VERSION ""

NS_ :

BS_:

BU_: ADSP CH ChassisBus DIPF DIPR ETH FC GTW GTWU HVI HVS ODIN PARTY PartyBus Receiver SDCV SUI UI UIS VEH VIRT VITALS VehicleBus X

CM_ "Merged Tesla Model Y DBC. Priority order (highest wins on message-ID conflict):
  1. joshwardell/model3dbc (Model3CAN.dbc) (159 messages)
  2. talas9/tesla_can_signals (ModelY_ETH.compact.json) (148 messages)
  3. onyx-m2/onyx-m2-dbc (tesla_model3.dbc) (316 messages)
  4. commaai/opendbc (tesla_model3_party.dbc) (21 messages)
Generated by overlaying sources by message ID; lower-priority sources fill IDs missing from higher-priority ones.";

BO_ 12 ID00CUI_status: 8 VehicleBus
 SG_ UI_audioActive : 1|1@1+ (1,0) [0|1] ""  Receiver
 SG_ UI_autopilotTrial : 12|2@1+ (1,0) [0|3] ""  Receiver
 SG_ UI_bluetoothActive : 2|1@1+ (1,0) [0|1] ""  Receiver
 SG_ UI_cameraActive : 41|1@1+ (1,0) [0|1] ""  Receiver
 SG_ UI_cellActive : 3|1@1+ (1,0) [0|1] ""  Receiver
 SG_ UI_cellConnected : 10|1@1+ (1,0) [0|1] ""  Receiver
 SG_ UI_cellNetworkTechnology : 19|4@1+ (1,0) [0|15] ""  Receiver
 SG_ UI_cellReceiverPower : 24|8@1+ (1,-128) [-128|127] "dB"  Receiver
 SG_ UI_cellSignalBars : 42|3@1+ (1,0) [0|7] ""  Receiver
 SG_ UI_cpuTemperature : 56|8@1- (1,40) [-20|100] "C"  Receiver
 SG_ UI_developmentCar : 40|1@1+ (1,0) [0|1] ""  Receiver
 SG_ UI_displayOn : 5|1@1+ (1,0) [0|1] ""  Receiver
 SG_ UI_displayReady : 4|1@1+ (1,0) [0|1] ""  Receiver
 SG_ UI_factoryReset : 14|2@1+ (1,0) [0|3] ""  Receiver
 SG_ UI_falseTouchCounter : 32|8@1+ (1,0) [0|255] "1"  Receiver
 SG_ UI_gpsActive : 16|1@1+ (1,0) [0|1] ""  Receiver
 SG_ UI_pcbTemperature : 48|8@1- (1,40) [-20|100] "C"  Receiver
 SG_ UI_radioActive : 18|1@1+ (1,0) [0|1] ""  Receiver
 SG_ UI_readyForDrive : 9|1@1+ (1,0) [0|1] ""  Receiver
 SG_ UI_screenshotActive : 17|1@1+ (1,0) [0|1] ""  Receiver
 SG_ UI_systemActive : 8|1@1+ (1,0) [0|1] ""  Receiver
 SG_ UI_touchActive : 0|1@1+ (1,0) [0|1] ""  Receiver
 SG_ UI_vpnActive : 11|1@1+ (1,0) [0|1] ""  Receiver
 SG_ UI_wifiActive : 6|1@1+ (1,0) [0|1] ""  Receiver
 SG_ UI_wifiConnected : 7|1@1+ (1,0) [0|1] ""  Receiver

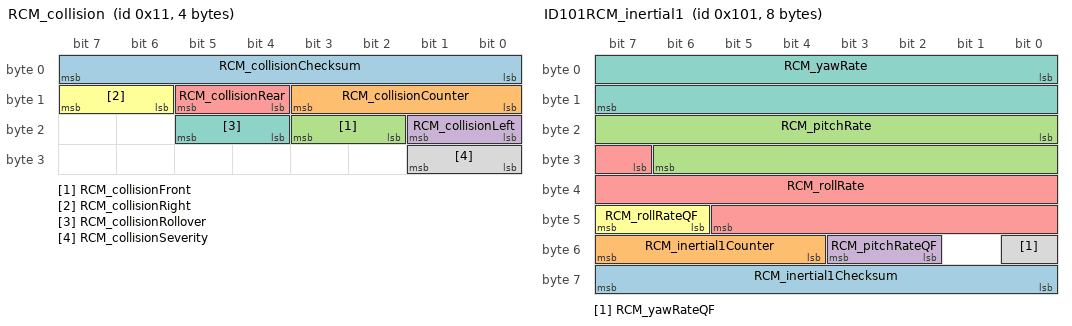
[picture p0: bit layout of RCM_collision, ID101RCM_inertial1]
BO_ 17 RCM_collision: 4 VEH
 SG_ RCM_collisionChecksum: 0|8@1+ (1,0) [0|0] "" X
 SG_ RCM_collisionCounter: 8|4@1+ (1,0) [0|0] "" X
 SG_ RCM_collisionFront: 18|2@1+ (1,0) [0|0] "" X
 SG_ RCM_collisionLeft: 16|2@1+ (1,0) [0|0] "" X
 SG_ RCM_collisionRear: 12|2@1+ (1,0) [0|0] "" X
 SG_ RCM_collisionRight: 14|2@1+ (1,0) [0|0] "" X
 SG_ RCM_collisionRollover: 20|2@1+ (1,0) [0|0] "" X
 SG_ RCM_collisionSeverity: 24|2@1+ (1,0) [0|0] "" X

BO_ 22 ID016DI_bmsRequest: 1 VehicleBus
 SG_ DI_bmsOpenContactorsRequest : 4|1@1+ (1,0) [0|1] ""  Receiver
 SG_ DI_bmsRequestInterfaceVersion : 0|4@1+ (1,0) [0|15] ""  Receiver

BO_ 60 GTW_info: 8 VEH
 SG_ GTW_infoIndex M: 0|8@1+ (1,0) [0|0] "" X
 SG_ GTW_applicationGitHash m17: 10|54@1+ (4,0) [0|0] "" X
 SG_ GTW_buildType m10: 8|3@1+ (1,0) [0|0] "" X
 SG_ GTW_hardwareId m10: 32|16@1+ (1,0) [0|0] "" X
 SG_ GTW_bootGitHash m18: 10|54@1+ (4,0) [0|0] "" X
 SG_ GTW_bootCrc m20: 32|32@1+ (1,0) [0|0] "" X
 SG_ GTW_platformType m13: 8|8@1+ (1,0) [0|0] "" X
 SG_ GTW_appCrc m13: 32|32@1+ (1,0) [0|0] "" X

BO_ 62 GTW_alertMatrix: 8 VEH
 SG_ GTW_matrixIndex M: 0|4@1+ (1,0) [0|0] "" X
 SG_ GTW_w000_GTW_ALERT_DO_NOT_USE m0: 4|1@1+ (1,0) [0|0] "" X
 SG_ GTW_w001_canVEHTxQueue m0: 5|1@1+ (1,0) [0|0] "" X
 SG_ GTW_w002_taskError m0: 6|1@1+ (1,0) [0|0] "" X
 SG_ GTW_w003_logWriteRecord m0: 7|1@1+ (1,0) [0|0] "" X
 SG_ GTW_w004_mallocHook m0: 8|1@1+ (1,0) [0|0] "" X
 SG_ GTW_w005_stackOverflowHook m0: 9|1@1+ (1,0) [0|0] "" X
 SG_ GTW_w006_ifTxOutputFull m0: 10|1@1+ (1,0) [0|0] "" X
 SG_ GTW_w007_ifRxBufError m0: 11|1@1+ (1,0) [0|0] "" X
 SG_ GTW_w008_ifPbufAllocError m0: 12|1@1+ (1,0) [0|0] "" X
 SG_ GTW_w009_lateTask m0: 13|1@1+ (1,0) [0|0] "" X
 SG_ GTW_w010_wdTaskCount m0: 14|1@1+ (1,0) [0|0] "" X
 SG_ GTW_w011_cancoreWatchdog m0: 15|1@1+ (1,0) [0|0] "" X
 SG_ GTW_w012_maincoreWatchdog m0: 16|1@1+ (1,0) [0|0] "" X
 SG_ GTW_w014_APSversionMismatch m0: 17|1@1+ (1,0) [0|0] "" X
 SG_ GTW_w015_DISversionMismatch m0: 18|1@1+ (1,0) [0|0] "" X
 SG_ GTW_w016_BLEEPversionMismatch m0: 19|1@1+ (1,0) [0|0] "" X
 SG_ GTW_w017_BMSversionMismatch m0: 20|1@1+ (1,0) [0|0] "" X
 SG_ GTW_w018_CMPversionMismatch m0: 21|1@1+ (1,0) [0|0] "" X
 SG_ GTW_w019_CPversionMismatch m0: 22|1@1+ (1,0) [0|0] "" X
 SG_ GTW_w020_DIversionMismatch m0: 23|1@1+ (1,0) [0|0] "" X
 SG_ GTW_w021_EPAS3PversionMismatch m0: 24|1@1+ (1,0) [0|0] "" X
 SG_ GTW_w022_EPBLversionMismatch m0: 25|1@1+ (1,0) [0|0] "" X
 SG_ GTW_w023_EPBRversionMismatch m0: 26|1@1+ (1,0) [0|0] "" X
 SG_ GTW_w024_ESPversionMismatch m0: 27|1@1+ (1,0) [0|0] "" X
 SG_ GTW_w025_ESPCALversionMismatch m0: 28|1@1+ (1,0) [0|0] "" X
 SG_ GTW_w026_GTWversionMismatch m0: 29|1@1+ (1,0) [0|0] "" X
 SG_ GTW_w027_HVPversionMismatch m0: 30|1@1+ (1,0) [0|0] "" X
 SG_ GTW_w028_IBSTversionMismatch m0: 31|1@1+ (1,0) [0|0] "" X
 SG_ GTW_w029_IBSTCALversionMismatch m0: 32|1@1+ (1,0) [0|0] "" X
 SG_ GTW_w030_OCS1PversionMismatch m0: 33|1@1+ (1,0) [0|0] "" X
 SG_ GTW_w031_PARKversionMismatch m0: 34|1@1+ (1,0) [0|0] "" X
 SG_ GTW_w032_PCSversionMismatch m0: 35|1@1+ (1,0) [0|0] "" X
 SG_ GTW_w033_PCSCPU2versionMismatch m0: 36|1@1+ (1,0) [0|0] "" X
 SG_ GTW_w034_PMversionMismatch m0: 37|1@1+ (1,0) [0|0] "" X
 SG_ GTW_w035_PMSversionMismatch m0: 38|1@1+ (1,0) [0|0] "" X
 SG_ GTW_w036_PTCversionMismatch m0: 39|1@1+ (1,0) [0|0] "" X
 SG_ GTW_w037_RADCversionMismatch m0: 40|1@1+ (1,0) [0|0] "" X
 SG_ GTW_w038_RCMversionMismatch m0: 41|1@1+ (1,0) [0|0] "" X
 SG_ GTW_w039_RCMCALversionMismatch m0: 42|1@1+ (1,0) [0|0] "" X
 SG_ GTW_w040_SCCMversionMismatch m0: 43|1@1+ (1,0) [0|0] "" X
 SG_ GTW_w041_VCSECversionMismatch m0: 44|1@1+ (1,0) [0|0] "" X
 SG_ GTW_w042_TASversionMismatch m0: 45|1@1+ (1,0) [0|0] "" X
 SG_ GTW_w043_THSversionMismatch m0: 46|1@1+ (1,0) [0|0] "" X
 SG_ GTW_w044_TPMSversionMismatch m0: 47|1@1+ (1,0) [0|0] "" X
 SG_ GTW_w045_VCFRONTversionMismatch m0: 48|1@1+ (1,0) [0|0] "" X
 SG_ GTW_w046_VCLEFTversionMismatch m0: 49|1@1+ (1,0) [0|0] "" X
 SG_ GTW_w047_VCRIGHTversionMismatch m0: 50|1@1+ (1,0) [0|0] "" X
 SG_ GTW_w048_EPAS3SversionMismatch m0: 51|1@1+ (1,0) [0|0] "" X
 SG_ GTW_w049_corruptedManifest m0: 52|1@1+ (1,0) [0|0] "" X
 SG_ GTW_w050_sdCardInitFailure m0: 53|1@1+ (1,0) [0|0] "" X
 SG_ GTW_w051_sdCardFileSystemFailure m0: 54|1@1+ (1,0) [0|0] "" X
 SG_ GTW_w052_ifTxSpans m0: 55|1@1+ (1,0) [0|0] "" X
 SG_ GTW_w053_busSleepFailure m0: 56|1@1+ (1,0) [0|0] "" X
 SG_ GTW_w054_OPCversionMismatch m0: 57|1@1+ (1,0) [0|0] "" X
 SG_ GTW_w055_OPCSversionMismatch m0: 58|1@1+ (1,0) [0|0] "" X
 SG_ GTW_w057_i2cFailure m0: 59|1@1+ (1,0) [0|0] "" X
 SG_ GTW_w058_rtcAlarmFailure m0: 60|1@1+ (1,0) [0|0] "" X
 SG_ GTW_w059_inFactoryMode m0: 61|1@1+ (1,0) [0|0] "" X
 SG_ GTW_w060_unFused m0: 62|1@1+ (1,0) [0|0] "" X
 SG_ GTW_w061_bmpSleepFailure m0: 63|1@1+ (1,0) [0|0] "" X
 SG_ GTW_w062_bmpWatchdog m1: 4|1@1+ (1,0) [0|0] "" X
 SG_ GTW_w063_VEH_canFault m1: 5|1@1+ (1,0) [0|0] "" X
 SG_ GTW_w064_CH_canFault m1: 6|1@1+ (1,0) [0|0] "" X
 SG_ GTW_w065_PARTY_canFault m1: 7|1@1+ (1,0) [0|0] "" X
 SG_ GTW_w066_exception m1: 8|1@1+ (1,0) [0|0] "" X
 SG_ GTW_w067_tcpDebug m1: 9|1@1+ (1,0) [0|0] "" X
 SG_ GTW_w068_prodKeyMissing m1: 10|1@1+ (1,0) [0|0] "" X
 SG_ GTW_w069_diskioErr m1: 11|1@1+ (1,0) [0|0] "" X
 SG_ GTW_w070_hrlDump m1: 12|1@1+ (1,0) [0|0] "" X
 SG_ GTW_w071_hrlTrigger m1: 13|1@1+ (1,0) [0|0] "" X
 SG_ GTW_w072_updateFailure m1: 14|1@1+ (1,0) [0|0] "" X
 SG_ GTW_w073_steeringWheelReset m1: 15|1@1+ (1,0) [0|0] "" X
 SG_ GTW_w074_epas3pMIA m1: 16|1@1+ (1,0) [0|0] "" X
 SG_ GTW_w075_epas3sMIA m1: 17|1@1+ (1,0) [0|0] "" X
 SG_ GTW_w076_VEHInterfaceReset m1: 18|1@1+ (1,0) [0|0] "" X
 SG_ GTW_w077_bmpPmicError m1: 19|1@1+ (1,0) [0|0] "" X
 SG_ GTW_w078_VEHbusOverloaded m1: 20|1@1+ (1,0) [0|0] "" X
 SG_ GTW_w079_PARTYbusOverloaded m1: 21|1@1+ (1,0) [0|0] "" X
 SG_ GTW_w080_CHbusOverloaded m1: 22|1@1+ (1,0) [0|0] "" X
 SG_ GTW_w081_udsMessageRejected m1: 23|1@1+ (1,0) [0|0] "" X
 SG_ GTW_w082_sdCardBSCorrupted m1: 24|1@1+ (1,0) [0|0] "" X
 SG_ GTW_w083_udsMsgDroppedByTcpStack m1: 25|1@1+ (1,0) [0|0] "" X
 SG_ GTW_w084_canFrameDropped m1: 26|1@1+ (1,0) [0|0] "" X
 SG_ GTW_w085_iBoosterStuck m1: 27|1@1+ (1,0) [0|0] "" X
 SG_ GTW_w086_ocu m1: 28|1@1+ (1,0) [0|0] "" X
 SG_ GTW_w087_ocuInProgress m1: 29|1@1+ (1,0) [0|0] "" X
 SG_ GTW_w088_sdCardInvReqParallel m1: 30|1@1+ (1,0) [0|0] "" X
 SG_ GTW_w089_sdCardWatchdog m1: 31|1@1+ (1,0) [0|0] "" X
 SG_ GTW_w090_ocuFailed m1: 32|1@1+ (1,0) [0|0] "" X
 SG_ GTW_w091_lowStack m1: 33|1@1+ (1,0) [0|0] "" X
 SG_ GTW_w092_sdCardInvReqZero m1: 34|1@1+ (1,0) [0|0] "" X
 SG_ GTW_w093_sdCardInvReqOverflowBase m1: 35|1@1+ (1,0) [0|0] "" X
 SG_ GTW_w094_sdCardInvReqOverflowCount m1: 36|1@1+ (1,0) [0|0] "" X
 SG_ GTW_w095_sdCardFull m1: 37|1@1+ (1,0) [0|0] "" X
 SG_ GTW_w096_sdCardFatCorrupted m1: 38|1@1+ (1,0) [0|0] "" X
 SG_ GTW_w097_HCMLversionMismatch m1: 39|1@1+ (1,0) [0|0] "" X
 SG_ GTW_w098_HCMRversionMismatch m1: 40|1@1+ (1,0) [0|0] "" X
 SG_ GTW_w099_SWCversionMismatch m1: 41|1@1+ (1,0) [0|0] "" X
 SG_ GTW_w100_CBCversionMismatch m1: 42|1@1+ (1,0) [0|0] "" X
 SG_ GTW_w101_switchWatchdog m1: 43|1@1+ (1,0) [0|0] "" X
 SG_ GTW_w103_sdCardFormatted m1: 44|1@1+ (1,0) [0|0] "" X
 SG_ GTW_w104_sdCardDriverArgCorrupted m1: 45|1@1+ (1,0) [0|0] "" X
 SG_ GTW_w105_eBuckConfigured m1: 46|1@1+ (1,0) [0|0] "" X
 SG_ GTW_w106_failedToStartUpdater m1: 47|1@1+ (1,0) [0|0] "" X

BO_ 79 ID04FGPSLatLong: 8 ChassisBus
 SG_ GPSAccuracy04F : 57|7@1+ (0.2,0) [0|25.2] "m"  Receiver
 SG_ GPSLongitude04F : 28|28@1- (1E-006,0) [-134.218|134.218] "Deg"  Receiver
 SG_ GPSLatitude04F : 0|28@1- (1E-006,0) [-134.218|134.218] "Deg"  Receiver

BO_ 130 ID082UI_tripPlanning: 8 VehicleBus
 SG_ UI_energyAtDestination : 48|16@1- (0.01,0) [-327.67|327.67] "kWh"  Receiver
 SG_ UI_hindsightEnergy : 32|16@1- (0.01,0) [-327.67|327.67] "kWh"  Receiver
 SG_ UI_navToSupercharger : 1|1@1+ (1,0) [0|1] ""  Receiver
 SG_ UI_predictedEnergy : 16|16@1- (0.01,0) [-327.67|327.67] "kWh"  Receiver
 SG_ UI_requestActiveBatteryHeating : 2|1@1+ (1,0) [0|1] ""  Receiver
 SG_ UI_tripPlanningActive : 0|1@1+ (1,0) [0|1] ""  Receiver

BO_ 139 UI_tripPlanning2: 6 VEH
 SG_ UI_maxSpeedToReachDestination : 0|16@1+ (0.01,0) [0|655.34] "m/s" X
 SG_ UI_remainingWeightedRMSSpeed : 16|16@1+ (0.01,0) [0|655.34] "m/s" X
 SG_ UI_timeToDestination : 32|16@1+ (1,0) [0|65534] "s" X

BO_ 257 ID101RCM_inertial1: 8 ChassisBus
 SG_ RCM_inertial1Checksum : 56|8@1+ (1,0) [0|255] ""  Receiver
 SG_ RCM_inertial1Counter : 52|4@1+ (1,0) [0|15] ""  Receiver
 SG_ RCM_pitchRate : 16|15@1- (0.00025,0) [-4.096|4.09575] "rad/s"  Receiver
 SG_ RCM_pitchRateQF : 50|2@1+ (1,0) [0|3] ""  Receiver
 SG_ RCM_rollRate : 31|15@1- (0.00025,0) [-4.096|4.09575] "rad/s"  Receiver
 SG_ RCM_rollRateQF : 46|2@1+ (1,0) [0|3] ""  Receiver
 SG_ RCM_yawRate : 0|16@1- (0.0001,0) [-3.2766|3.2766] "rad/s"  Receiver
 SG_ RCM_yawRateQF : 48|1@1+ (1,0) [0|1] ""  Receiver

BO_ 258 ID102VCLEFT_doorStatus: 8 VehicleBus
 SG_ VCLEFT_frontHandlePWM : 16|7@1+ (1,0) [0|100] "%"  Receiver
 SG_ VCLEFT_frontHandlePulled : 10|1@1+ (1,0) [0|1] ""  Receiver
 SG_ VCLEFT_frontHandlePulledPersist : 62|1@1+ (1,0) [0|1] ""  Receiver
 SG_ VCLEFT_frontIntSwitchPressed : 31|1@1+ (1,0) [0|1] ""  Receiver
 SG_ VCLEFT_frontLatchStatus : 0|4@1+ (1,0) [0|8] ""  Receiver
 SG_ VCLEFT_frontLatchSwitch : 8|1@1+ (1,0) [0|1] ""  Receiver
 SG_ VCLEFT_frontRelActuatorSwitch : 12|1@1+ (1,0) [0|1] ""  Receiver
 SG_ VCLEFT_mirrorDipped : 61|1@1+ (1,0) [0|1] ""  Receiver
 SG_ VCLEFT_mirrorFoldState : 52|3@1+ (1,0) [0|4] ""  Receiver
 SG_ VCLEFT_mirrorHeatState : 58|3@1+ (1,0) [0|4] ""  Receiver
 SG_ VCLEFT_mirrorRecallState : 55|3@1+ (1,0) [0|5] ""  Receiver
 SG_ VCLEFT_mirrorState : 49|3@1+ (1,0) [0|4] ""  Receiver
 SG_ VCLEFT_mirrorTiltXPosition : 33|8@1+ (0.02,0) [0|5] "V"  Receiver
 SG_ VCLEFT_mirrorTiltYPosition : 41|8@1+ (0.02,0) [0|5] "V"  Receiver
 SG_ VCLEFT_rearHandlePWM : 24|7@1+ (1,0) [0|100] "%"  Receiver
 SG_ VCLEFT_rearHandlePulled : 11|1@1+ (1,0) [0|1] ""  Receiver
 SG_ VCLEFT_rearIntSwitchPressed : 32|1@1+ (1,0) [0|1] ""  Receiver
 SG_ VCLEFT_rearLatchStatus : 4|4@1+ (1,0) [0|8] ""  Receiver
 SG_ VCLEFT_rearLatchSwitch : 9|1@1+ (1,0) [0|1] ""  Receiver
 SG_ VCLEFT_rearRelActuatorSwitch : 13|1@1+ (1,0) [0|1] ""  Receiver

BO_ 259 ID103VCRIGHT_doorStatus: 8 VehicleBus
 SG_ VCRIGHT_frontHandlePWM : 14|7@1+ (1,0) [0|100] "%"  Receiver
 SG_ VCRIGHT_frontHandlePulled : 10|1@1+ (1,0) [0|1] ""  Receiver
 SG_ VCRIGHT_frontHandlePulledPersist : 30|1@1+ (1,0) [0|1] ""  Receiver
 SG_ VCRIGHT_frontIntSwitchPressed : 31|1@1+ (1,0) [0|1] ""  Receiver
 SG_ VCRIGHT_frontLatchStatus : 0|4@1+ (1,0) [0|8] ""  Receiver
 SG_ VCRIGHT_frontLatchSwitch : 8|1@1+ (1,0) [0|1] ""  Receiver
 SG_ VCRIGHT_frontRelActuatorSwitch : 12|1@1+ (1,0) [0|1] ""  Receiver
 SG_ VCRIGHT_mirrorDipped : 63|1@1+ (1,0) [0|1] ""  Receiver
 SG_ VCRIGHT_mirrorFoldState : 52|3@1+ (1,0) [0|4] ""  Receiver
 SG_ VCRIGHT_mirrorRecallState : 60|3@1+ (1,0) [0|5] ""  Receiver
 SG_ VCRIGHT_mirrorState : 49|3@1+ (1,0) [0|4] ""  Receiver
 SG_ VCRIGHT_mirrorTiltXPosition : 33|8@1+ (0.02,0) [0|5] "V"  Receiver
 SG_ VCRIGHT_mirrorTiltYPosition : 41|8@1+ (0.02,0) [0|5] "V"  Receiver
 SG_ VCRIGHT_rearHandlePWM : 21|7@1+ (1,0) [0|100] "%"  Receiver
 SG_ VCRIGHT_rearHandlePulled : 11|1@1+ (1,0) [0|1] ""  Receiver
 SG_ VCRIGHT_rearIntSwitchPressed : 32|1@1+ (1,0) [0|1] ""  Receiver
 SG_ VCRIGHT_rearLatchStatus : 4|4@1+ (1,0) [0|8] ""  Receiver
 SG_ VCRIGHT_rearLatchSwitch : 9|1@1+ (1,0) [0|1] ""  Receiver
 SG_ VCRIGHT_rearRelActuatorSwitch : 13|1@1+ (1,0) [0|1] ""  Receiver
 SG_ VCRIGHT_reservedForBackCompat : 28|2@1+ (1,0) [0|3] ""  Receiver
 SG_ VCRIGHT_trunkLatchStatus : 56|4@1+ (1,0) [0|8] ""  Receiver

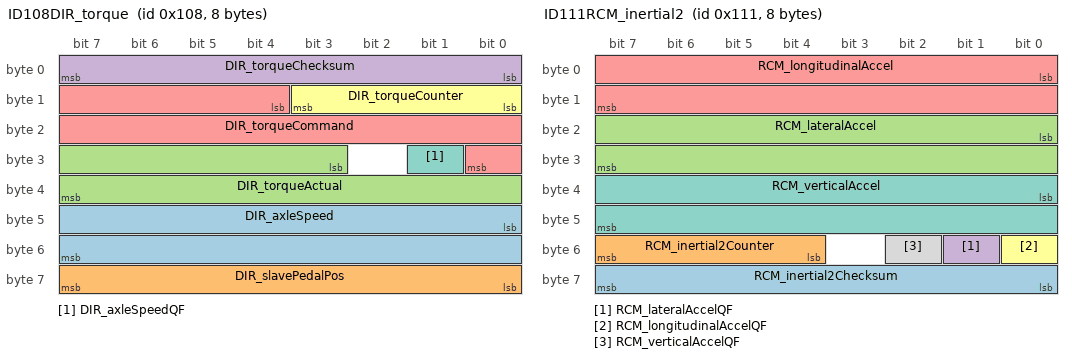
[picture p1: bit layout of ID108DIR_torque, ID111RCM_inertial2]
BO_ 264 ID108DIR_torque: 8 VehicleBus
 SG_ DIR_axleSpeed : 40|16@1- (0.1,0) [-2750|2750] "RPM"  Receiver
 SG_ DIR_slavePedalPos : 56|8@1+ (0.4,0) [0|100] "%"  Receiver
 SG_ DIR_torqueActual : 27|13@1- (2,0) [-7500|7500] "Nm"  Receiver
 SG_ DIR_torqueChecksum : 0|8@1+ (1,0) [0|255] ""  Receiver
 SG_ DIR_torqueCommand : 12|13@1- (2,0) [-7500|7500] "Nm"  Receiver
 SG_ DIR_torqueCounter : 8|4@1+ (1,0) [0|15] ""  Receiver
 SG_ DIR_axleSpeedQF : 25|1@1+ (1,0) [0|1] ""  Receiver

BO_ 273 ID111RCM_inertial2: 8 ChassisBus
 SG_ RCM_inertial2Checksum : 56|8@1+ (1,0) [0|255] ""  Receiver
 SG_ RCM_inertial2Counter : 52|4@1+ (1,0) [0|15] ""  Receiver
 SG_ RCM_lateralAccel : 16|16@1- (0.00125,0) [-40.9575|40.9575] "m/s^2"  Receiver
 SG_ RCM_lateralAccelQF : 49|1@1+ (1,0) [0|1] ""  Receiver
 SG_ RCM_longitudinalAccel : 0|16@1- (0.00125,0) [-40.9575|40.9575] "m/s^2"  Receiver
 SG_ RCM_longitudinalAccelQF : 48|1@1+ (1,0) [0|1] ""  Receiver
 SG_ RCM_verticalAccel : 32|16@1- (0.00125,0) [-40.9575|40.9575] "m/s^2"  Receiver
 SG_ RCM_verticalAccelQF : 50|1@1+ (1,0) [0|1] ""  Receiver

BO_ 274 GTW_adc1: 8 VEH
 SG_ GTW_1V1_VEH: 24|12@0+ (1,0) [0|0] "mV" X
 SG_ GTW_1V5_VEH: 32|12@0+ (1,0) [0|0] "mV" X
 SG_ GTW_3V3_VEH: 0|12@0+ (1.03,0) [0|0] "mV" X
 SG_ GTW_3V3_SW: 8|12@0+ (1.5,0) [0|0] "mV" X
 SG_ GTW_5V0_SW: 48|12@0+ (2,0) [0|0] "mV" X

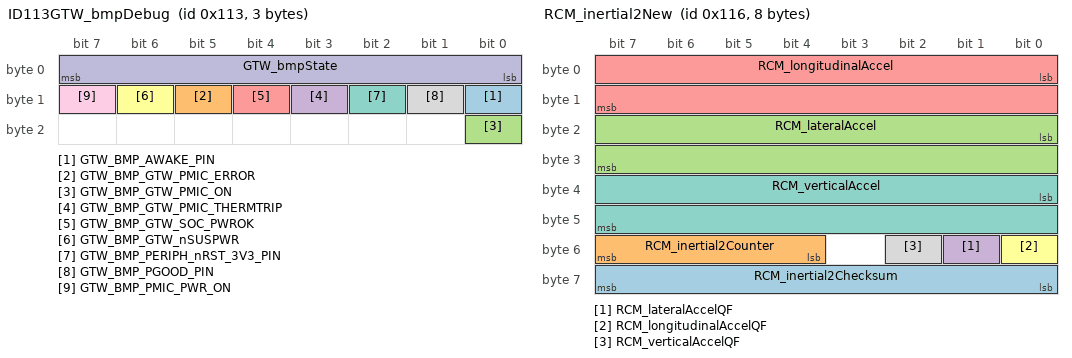
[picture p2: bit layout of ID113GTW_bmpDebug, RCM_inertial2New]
BO_ 275 ID113GTW_bmpDebug: 3 VehicleBus
 SG_ GTW_BMP_AWAKE_PIN : 8|1@1+ (1,0) [0|1] ""  Receiver
 SG_ GTW_BMP_GTW_PMIC_ERROR : 13|1@1+ (1,0) [0|1] ""  Receiver
 SG_ GTW_BMP_GTW_PMIC_ON : 16|1@1+ (1,0) [0|1] ""  Receiver
 SG_ GTW_BMP_GTW_PMIC_THERMTRIP : 11|1@1+ (1,0) [0|1] ""  Receiver
 SG_ GTW_BMP_GTW_SOC_PWROK : 12|1@1+ (1,0) [0|1] ""  Receiver
 SG_ GTW_BMP_GTW_nSUSPWR : 14|1@1+ (1,0) [0|1] ""  Receiver
 SG_ GTW_BMP_PERIPH_nRST_3V3_PIN : 10|1@1+ (1,0) [0|1] ""  Receiver
 SG_ GTW_BMP_PGOOD_PIN : 9|1@1+ (1,0) [0|1] ""  Receiver
 SG_ GTW_BMP_PMIC_PWR_ON : 15|1@1+ (1,0) [0|1] ""  Receiver
 SG_ GTW_bmpState : 7|8@0+ (1,0) [0|255] ""  Receiver

BO_ 276 GTW_adc3: 8 VEH
 SG_ GTW_1V2_CSI: 24|12@0+ (1,0) [0|0] "mV" X
 SG_ GTW_1V8_VID: 8|12@0+ (1,0) [0|0] "mV" X
 SG_ GTW_1V8_VIO: 0|12@0+ (2,0) [0|0] "mV" X
 SG_ GTW_3V3_BMP: 32|12@0+ (2,0) [0|0] "mV" X
 SG_ GTW_GSM_BRD_REV: 48|12@0+ (1,0) [0|0] "mV" X

BO_ 278 RCM_inertial2New: 8 ChassisBus
 SG_ RCM_inertial2Checksum : 56|8@1+ (1,0) [0|255] ""  Receiver
 SG_ RCM_inertial2Counter : 52|4@1+ (1,0) [0|15] ""  Receiver
 SG_ RCM_lateralAccel : 16|16@1- (0.00125,0) [-40.9575|40.9575] "m/s^2"  Receiver
 SG_ RCM_lateralAccelQF : 49|1@1+ (1,0) [0|1] ""  Receiver
 SG_ RCM_longitudinalAccel : 0|16@1- (0.00125,0) [-40.9575|40.9575] "m/s^2"  Receiver
 SG_ RCM_longitudinalAccelQF : 48|1@1+ (1,0) [0|1] ""  Receiver
 SG_ RCM_verticalAccel : 32|16@1- (0.00125,0) [-40.9575|40.9575] "m/s^2"  Receiver
 SG_ RCM_verticalAccelQF : 50|1@1+ (1,0) [0|1] ""  Receiver

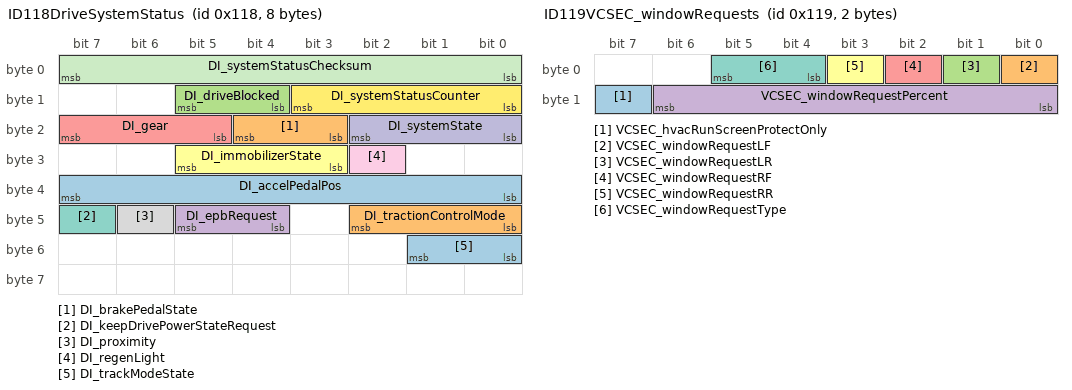
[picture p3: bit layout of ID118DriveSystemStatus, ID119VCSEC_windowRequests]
BO_ 280 ID118DriveSystemStatus: 8 VehicleBus
 SG_ DI_accelPedalPos : 32|8@1+ (0.4,0) [0|100] "%"  Receiver
 SG_ DI_brakePedalState : 19|2@1+ (1,0) [0|2] ""  Receiver
 SG_ DI_driveBlocked : 12|2@1+ (1,0) [0|2] ""  Receiver
 SG_ DI_epbRequest : 44|2@1+ (1,0) [0|2] ""  Receiver
 SG_ DI_gear : 21|3@1+ (1,0) [0|7] ""  Receiver
 SG_ DI_immobilizerState : 27|3@1+ (1,0) [0|6] ""  Receiver
 SG_ DI_keepDrivePowerStateRequest : 47|1@1+ (1,0) [0|1] ""  Receiver
 SG_ DI_proximity : 46|1@1+ (1,0) [0|1] ""  Receiver
 SG_ DI_regenLight : 26|1@1+ (1,0) [0|1] ""  Receiver
 SG_ DI_systemState : 16|3@1+ (1,0) [0|5] ""  Receiver
 SG_ DI_systemStatusChecksum : 0|8@1+ (1,0) [0|255] ""  Receiver
 SG_ DI_systemStatusCounter : 8|4@1+ (1,0) [0|15] ""  Receiver
 SG_ DI_trackModeState : 48|2@1+ (1,0) [0|2] ""  Receiver
 SG_ DI_tractionControlMode : 40|3@1+ (1,0) [0|6] ""  Receiver

BO_ 281 ID119VCSEC_windowRequests: 2 VehicleBus
 SG_ VCSEC_hvacRunScreenProtectOnly : 15|1@1+ (1,0) [0|1] ""  Receiver
 SG_ VCSEC_windowRequestLF : 0|1@1+ (1,0) [0|1] ""  Receiver
 SG_ VCSEC_windowRequestLR : 1|1@1+ (1,0) [0|1] ""  Receiver
 SG_ VCSEC_windowRequestPercent : 8|7@1+ (1,0) [0|127] ""  Receiver
 SG_ VCSEC_windowRequestRF : 2|1@1+ (1,0) [0|1] ""  Receiver
 SG_ VCSEC_windowRequestRR : 3|1@1+ (1,0) [0|1] ""  Receiver
 SG_ VCSEC_windowRequestType : 4|2@1+ (1,0) [0|3] ""  Receiver

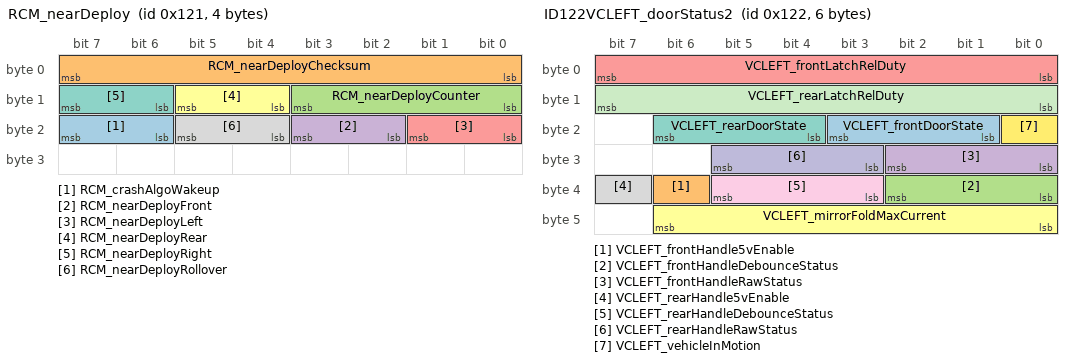
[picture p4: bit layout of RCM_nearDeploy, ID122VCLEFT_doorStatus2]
BO_ 289 RCM_nearDeploy: 4 VEH
 SG_ RCM_crashAlgoWakeup: 22|2@1+ (1,0) [0|0] "" X
 SG_ RCM_nearDeployChecksum: 0|8@1+ (1,0) [0|0] "" X
 SG_ RCM_nearDeployCounter: 8|4@1+ (1,0) [0|0] "" X
 SG_ RCM_nearDeployFront: 18|2@1+ (1,0) [0|0] "" X
 SG_ RCM_nearDeployLeft: 16|2@1+ (1,0) [0|0] "" X
 SG_ RCM_nearDeployRear: 12|2@1+ (1,0) [0|0] "" X
 SG_ RCM_nearDeployRight: 14|2@1+ (1,0) [0|0] "" X
 SG_ RCM_nearDeployRollover: 20|2@1+ (1,0) [0|0] "" X

BO_ 290 ID122VCLEFT_doorStatus2: 6 VehicleBus
 SG_ VCLEFT_frontDoorState : 17|3@1+ (1,0) [0|4] ""  Receiver
 SG_ VCLEFT_frontHandle5vEnable : 38|1@1+ (1,0) [0|1] ""  Receiver
 SG_ VCLEFT_frontHandleDebounceStatus : 32|3@1+ (1,0) [0|5] ""  Receiver
 SG_ VCLEFT_frontHandleRawStatus : 24|3@1+ (1,0) [0|5] ""  Receiver
 SG_ VCLEFT_frontLatchRelDuty : 0|8@1+ (1,0) [0|255] "%"  Receiver
 SG_ VCLEFT_mirrorFoldMaxCurrent : 40|7@1- (0.046,0) [-2.944|2.898] "A"  Receiver
 SG_ VCLEFT_rearDoorState : 20|3@1+ (1,0) [0|4] ""  Receiver
 SG_ VCLEFT_rearHandle5vEnable : 39|1@1+ (1,0) [0|1] ""  Receiver
 SG_ VCLEFT_rearHandleDebounceStatus : 35|3@1+ (1,0) [0|5] ""  Receiver
 SG_ VCLEFT_rearHandleRawStatus : 27|3@1+ (1,0) [0|5] ""  Receiver
 SG_ VCLEFT_rearLatchRelDuty : 8|8@1+ (1,0) [0|255] "%"  Receiver
 SG_ VCLEFT_vehicleInMotion : 16|1@1+ (1,0) [0|1] ""  Receiver

BO_ 291 ID123UI_alertMatrix1: 8 VehicleBus
 SG_ UI_a001_DriverDoorOpen : 0|1@1+ (1,0) [0|1] ""  Receiver
 SG_ UI_a002_DoorOpen : 1|1@1+ (1,0) [0|1] ""  Receiver
 SG_ UI_a003_TrunkOpen : 2|1@1+ (1,0) [0|1] ""  Receiver
 SG_ UI_a004_FrunkOpen : 3|1@1+ (1,0) [0|1] ""  Receiver
 SG_ UI_a005_HeadlightsOnDoorOpen : 4|1@1+ (1,0) [0|1] ""  Receiver
 SG_ UI_a006_RemoteServiceAlert : 5|1@1+ (1,0) [0|1] ""  Receiver
 SG_ UI_a007_SoftPackConfigMismatch : 6|1@1+ (1,0) [0|1] ""  Receiver
 SG_ UI_a008_TouchScreenError : 7|1@1+ (1,0) [0|1] ""  Receiver
 SG_ UI_a009_SquashfsError : 8|1@1+ (1,0) [0|1] ""  Receiver
 SG_ UI_a010_MapsMissing : 9|1@1+ (1,0) [0|1] ""  Receiver
 SG_ UI_a011_IncorrectMap : 10|1@1+ (1,0) [0|1] ""  Receiver
 SG_ UI_a012_NotOnPrivateProperty : 11|1@1+ (1,0) [0|1] ""  Receiver
 SG_ UI_a013_TPMSHardWarning : 12|1@1+ (1,0) [0|1] ""  Receiver
 SG_ UI_a014_TPMSSoftWarning : 13|1@1+ (1,0) [0|1] ""  Receiver
 SG_ UI_a015_TPMSOverPressureWarning : 14|1@1+ (1,0) [0|1] ""  Receiver
 SG_ UI_a016_TPMSTemperatureWarning : 15|1@1+ (1,0) [0|1] ""  Receiver
 SG_ UI_a017_TPMSSystemFault : 16|1@1+ (1,0) [0|1] ""  Receiver
 SG_ UI_a018_SlipStartOn : 17|1@1+ (1,0) [0|1] ""  Receiver
 SG_ UI_a019_ParkBrakeFault : 18|1@1+ (1,0) [0|1] ""  Receiver
 SG_ UI_a020_SteeringReduced : 19|1@1+ (1,0) [0|1] ""  Receiver
 SG_ UI_a021_RearSeatbeltUnbuckled : 20|1@1+ (1,0) [0|1] ""  Receiver
 SG_ UI_a022_ApeFusesEtc : 21|1@1+ (1,0) [0|1] ""  Receiver
 SG_ UI_a023_CellInternetCheckFailed : 22|1@1+ (1,0) [0|1] ""  Receiver
 SG_ UI_a024_WifiInternetCheckFailed : 23|1@1+ (1,0) [0|1] ""  Receiver
 SG_ UI_a025_WifiOnlineCheckFailed : 24|1@1+ (1,0) [0|1] ""  Receiver
 SG_ UI_a026_ModemResetLoopDetected : 25|1@1+ (1,0) [0|1] ""  Receiver
 SG_ UI_a027_AutoSteerMIA : 26|1@1+ (1,0) [0|1] ""  Receiver
 SG_ UI_a028_FrontTrunkPopupClosed : 27|1@1+ (1,0) [0|1] ""  Receiver
 SG_ UI_a029_ModemMIA : 28|1@1+ (1,0) [0|1] ""  Receiver
 SG_ UI_a030_ModemVMCrash : 29|1@1+ (1,0) [0|1] ""  Receiver
 SG_ UI_a031_BrakeFluidLow : 30|1@1+ (1,0) [0|1] ""  Receiver
 SG_ UI_a032_CellModemRecoveryResets : 31|1@1+ (1,0) [0|1] ""  Receiver
 SG_ UI_a033_ApTrialExpired : 32|1@1+ (1,0) [0|1] ""  Receiver
 SG_ UI_a034_WakeupProblem : 33|1@1+ (1,0) [0|1] ""  Receiver
 SG_ UI_a035_AudioWatchdogKernelError : 34|1@1+ (1,0) [0|1] ""  Receiver
 SG_ UI_a036_AudioWatchdogHfpError : 35|1@1+ (1,0) [0|1] ""  Receiver
 SG_ UI_a037_AudioWatchdogXrunStormEr : 36|1@1+ (1,0) [0|1] ""  Receiver
 SG_ UI_a038_AudioWatchdogA2bI2cLocku : 37|1@1+ (1,0) [0|1] ""  Receiver
 SG_ UI_a039_AudioA2bNeedRediscovery : 38|1@1+ (1,0) [0|1] ""  Receiver
 SG_ UI_a040_HomelinkTransmit : 39|1@1+ (1,0) [0|1] ""  Receiver
 SG_ UI_a041_AudioDmesgXrun : 40|1@1+ (1,0) [0|1] ""  Receiver
 SG_ UI_a042_AudioDmesgRtThrottling : 41|1@1+ (1,0) [0|1] ""  Receiver
 SG_ UI_a043_InvalidMapDataOverride : 42|1@1+ (1,0) [0|1] ""  Receiver
 SG_ UI_a044_AudioDmesgDspException : 43|1@1+ (1,0) [0|1] ""  Receiver
 SG_ UI_a045_ECallNeedsService : 44|1@1+ (1,0) [0|1] ""  Receiver
 SG_ UI_a046_BackupCameraStreamError : 45|1@1+ (1,0) [0|1] ""  Receiver
 SG_ UI_a047_CellRoamingDisallowed : 46|1@1+ (1,0) [0|1] ""  Receiver
 SG_ UI_a048_AudioPremiumAmpCheckFail : 47|1@1+ (1,0) [0|1] ""  Receiver
 SG_ UI_a049_BrakeShiftRequired : 48|1@1+ (1,0) [0|1] ""  Receiver
 SG_ UI_a050_BackupCameraIPUTimeout : 49|1@1+ (1,0) [0|1] ""  Receiver
 SG_ UI_a051_BackupCameraFrameTimeout : 50|1@1+ (1,0) [0|1] ""  Receiver
 SG_ UI_a052_KernelPanicReported : 51|1@1+ (1,0) [0|1] ""  Receiver
 SG_ UI_a053_QtCarExitError : 52|1@1+ (1,0) [0|1] ""  Receiver
 SG_ UI_a054_AudioBoostPowerBad : 53|1@1+ (1,0) [0|1] ""  Receiver
 SG_ UI_a055_ManualECallDisabled : 54|1@1+ (1,0) [0|1] ""  Receiver
 SG_ UI_a056_ManualECallButtonDisconn : 55|1@1+ (1,0) [0|1] ""  Receiver
 SG_ UI_a057_CellAntennaDisconnected : 56|1@1+ (1,0) [0|1] ""  Receiver
 SG_ UI_a058_GPSAntennaDisconnected : 57|1@1+ (1,0) [0|1] ""  Receiver
 SG_ UI_a059_ECallSpeakerDisconnected : 58|1@1+ (1,0) [0|1] ""  Receiver
 SG_ UI_a060_ECallMicDisconnected : 59|1@1+ (1,0) [0|1] ""  Receiver
 SG_ UI_a061_SIMTestFailed : 60|1@1+ (1,0) [0|1] ""  Receiver
 SG_ UI_a062_ENSTestFailed : 61|1@1+ (1,0) [0|1] ""  Receiver
 SG_ UI_a063_CellularTestFailed : 62|1@1+ (1,0) [0|1] ""  Receiver
 SG_ UI_a064_ModemFirmwareTestFailed : 63|1@1+ (1,0) [0|1] ""  Receiver

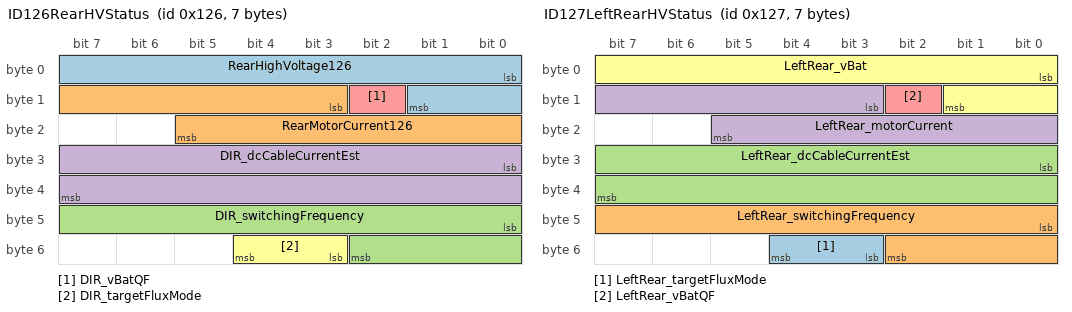
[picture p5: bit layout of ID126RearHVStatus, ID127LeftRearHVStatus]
BO_ 294 ID126RearHVStatus: 7 VehicleBus
 SG_ RearHighVoltage126 : 0|10@1+ (0.5,0) [0|500] "V"  Receiver
 SG_ RearMotorCurrent126 : 11|11@1+ (1,0) [0|2047] "A"  Receiver
 SG_ DIR_switchingFrequency : 40|11@1+ (0.01,0) [0|20] "kHz"  Receiver
 SG_ DIR_dcCableCurrentEst : 24|16@1- (0.1,0) [-3276.8|3276.7] "A"  Receiver
 SG_ DIR_vBatQF : 10|1@1+ (1,0) [0|1] ""  Receiver
 SG_ DIR_targetFluxMode : 51|2@1+ (1,0) [0|0] ""  Receiver

BO_ 295 ID127LeftRearHVStatus: 7 VehicleBus
 SG_ LeftRear_targetFluxMode : 51|2@1+ (1,0) [0|0] ""  Receiver
 SG_ LeftRear_switchingFrequency : 40|11@1+ (0.01,0) [0|0] "kHz"  Receiver
 SG_ LeftRear_dcCableCurrentEst : 24|16@1- (0.1,0) [0|0] "A"  Receiver
 SG_ LeftRear_motorCurrent : 11|11@1+ (1,0) [0|0] "A"  Receiver
 SG_ LeftRear_vBatQF : 10|1@1+ (1,0) [0|0] ""  Receiver
 SG_ LeftRear_vBat : 0|10@1+ (0.5,0) [0|0] "V"  Receiver

BO_ 297 ID129SteeringAngle: 8 VehicleBus
 SG_ SteeringSensorC129 : 56|8@1+ (1,0) [0|255] ""  Receiver
 SG_ SteeringSensorB129 : 48|8@1+ (1,0) [0|255] ""  Receiver
 SG_ SteeringSensorA129 : 46|2@1+ (1,0) [0|3] ""  Receiver
 SG_ SteeringSpeed129 : 32|14@1+ (0.5,-4096) [-4096|4095.5] "D/S"  Receiver
 SG_ SteeringAngle129 : 16|14@1+ (0.1,-819.2) [-819.2|819.1] "Deg"  Receiver

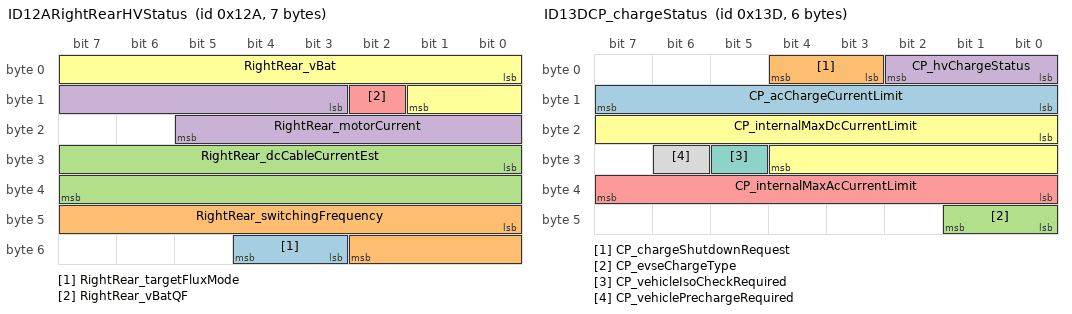
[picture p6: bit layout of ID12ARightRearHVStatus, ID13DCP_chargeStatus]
BO_ 298 ID12ARightRearHVStatus: 7 VehicleBus
 SG_ RightRear_targetFluxMode : 51|2@1+ (1,0) [0|0] ""  Receiver
 SG_ RightRear_switchingFrequency : 40|11@1+ (0.01,0) [0|0] "kHz"  Receiver
 SG_ RightRear_dcCableCurrentEst : 24|16@1- (0.1,0) [0|0] "A"  Receiver
 SG_ RightRear_motorCurrent : 11|11@1+ (1,0) [0|0] "A"  Receiver
 SG_ RightRear_vBatQF : 10|1@1+ (1,0) [0|0] ""  Receiver
 SG_ RightRear_vBat : 0|10@1+ (0.5,0) [0|0] "V"  Receiver

BO_ 306 ID132HVBattAmpVolt: 8 VehicleBus
 SG_ ChargeHoursRemaining132 : 48|12@1+ (1,0) [0|4095] "Min"  Receiver
 SG_ BattVoltage132 : 0|16@1+ (0.01,0) [0|655.35] "V"  Receiver
 SG_ RawBattCurrent132 : 32|16@1- (-0.05,822) [-1138.35|2138.4] "A"  Receiver
 SG_ SmoothBattCurrent132 : 16|16@1- (-0.1,0) [-3276.7|3276.7] "A"  Receiver

BO_ 307 UI_presentPhoneKeysOSInfo: 1 VEH
 SG_ UI_presentPhoneKey1RunsiOS: 0|1@1+ (1,0) [0|0] "" X
 SG_ UI_presentPhoneKey2RunsiOS: 1|1@1+ (1,0) [0|0] "" X
 SG_ UI_presentPhoneKey3RunsiOS: 2|1@1+ (1,0) [0|0] "" X

BO_ 317 ID13DCP_chargeStatus: 6 VehicleBus
 SG_ CP_acChargeCurrentLimit : 8|8@1+ (0.5,0) [0|127.5] "A"  Receiver
 SG_ CP_chargeShutdownRequest : 3|2@1+ (1,0) [0|2] ""  Receiver
 SG_ CP_evseChargeType : 40|2@1+ (1,0) [0|2] ""  Receiver
 SG_ CP_hvChargeStatus : 0|3@1+ (1,0) [0|6] ""  Receiver
 SG_ CP_internalMaxAcCurrentLimit : 32|8@1+ (0.5,0) [0|127.5] "A"  Receiver
 SG_ CP_internalMaxDcCurrentLimit : 16|13@1+ (0.146502,0) [0|1200] "A"  Receiver
 SG_ CP_vehicleIsoCheckRequired : 29|1@1+ (1,0) [0|1] ""  Receiver
 SG_ CP_vehiclePrechargeRequired : 30|1@1+ (1,0) [0|1] ""  Receiver

BO_ 322 ID142VCLEFT_liftgateStatus: 8 VehicleBus
 SG_ VCLEFT_liftgateStatusIndex M : 0|2@1+ (1,0) [0|2] ""  Receiver
 SG_ VCLEFT_liftgateLatchRequest m0 : 61|3@1+ (1,0) [0|4] ""  Receiver
 SG_ VCLEFT_liftgateMvmntNotAllowedCo m0 : 14|3@1+ (1,0) [0|5] ""  Receiver
 SG_ VCLEFT_liftgatePhysicalChimeRequ m0 : 21|3@1+ (1,0) [0|4] ""  Receiver
 SG_ VCLEFT_liftgatePosition m1 : 21|7@1- (1,46) [-5|95] "deg"  Receiver
 SG_ VCLEFT_liftgatePositionCalibrate m0 : 17|1@1+ (1,0) [0|1] ""  Receiver
 SG_ VCLEFT_liftgateRequestSource m0 : 7|3@1+ (1,0) [0|7] ""  Receiver
 SG_ VCLEFT_liftgateSpeed m1 : 28|10@1- (0.1,0) [-30|30] "deg/s"  Receiver
 SG_ VCLEFT_liftgateState m0 : 3|4@1+ (1,0) [0|12] ""  Receiver
 SG_ VCLEFT_liftgateStoppingCondition m0 : 10|4@1+ (1,0) [0|11] ""  Receiver
 SG_ VCLEFT_liftgateStrutCurrent m1 : 11|10@1- (0.1,0) [-30|30] "A"  Receiver
 SG_ VCLEFT_liftgateStrutDutyCycle m1 : 3|8@1- (1,0) [-100|100] "%"  Receiver
 SG_ VCLEFT_liftgateUIChimeRequest m0 : 18|3@1+ (1,0) [0|4] ""  Receiver

BO_ 325 ID145ESP_status: 8 ChassisBus
 SG_ ESP_absBrakeEvent2 : 22|2@1+ (1,0) [0|3] ""  Receiver
 SG_ ESP_absFaultLamp : 17|1@1+ (1,0) [0|1] ""  Receiver
 SG_ ESP_brakeApply : 31|1@1+ (1,0) [0|1] ""  Receiver
 SG_ ESP_brakeDiscWipingActive : 28|1@1+ (1,0) [0|1] ""  Receiver
 SG_ ESP_brakeLamp : 21|1@1+ (1,0) [0|1] ""  Receiver
 SG_ ESP_brakeTorqueTarget : 51|13@1+ (2,0) [0|16382] "Nm"  Receiver
 SG_ ESP_btcTargetState : 38|2@1+ (1,0) [0|3] ""  Receiver
 SG_ ESP_cdpStatus : 34|2@1+ (1,0) [0|3] ""  Receiver
 SG_ ESP_driverBrakeApply : 29|2@1+ (1,0) [0|3] ""  Receiver
 SG_ ESP_ebdFaultLamp : 16|1@1+ (1,0) [0|1] ""  Receiver
 SG_ ESP_ebrStandstillSkid : 48|1@1+ (1,0) [0|1] ""  Receiver
 SG_ ESP_ebrStatus : 49|2@1+ (1,0) [0|3] ""  Receiver
 SG_ ESP_espFaultLamp : 18|1@1+ (1,0) [0|1] ""  Receiver
 SG_ ESP_espLampFlash : 20|1@1+ (1,0) [0|1] ""  Receiver
 SG_ ESP_espModeActive : 12|2@1+ (1,0) [0|3] ""  Receiver
 SG_ ESP_hydraulicBoostEnabled : 19|1@1+ (1,0) [0|1] ""  Receiver
 SG_ ESP_lateralAccelQF : 25|1@1+ (1,0) [0|1] ""  Receiver
 SG_ ESP_longitudinalAccelQF : 24|1@1+ (1,0) [0|1] ""  Receiver
 SG_ ESP_ptcTargetState : 36|2@1+ (1,0) [0|3] ""  Receiver
 SG_ ESP_stabilityControlSts2 : 14|2@1+ (1,0) [0|3] ""  Receiver
 SG_ ESP_statusChecksum : 0|8@1+ (1,0) [0|255] ""  Receiver
 SG_ ESP_statusCounter : 8|4@1+ (1,0) [0|15] ""  Receiver
 SG_ ESP_steeringAngleQF : 27|1@1+ (1,0) [0|1] ""  Receiver
 SG_ ESP_yawRateQF : 26|1@1+ (1,0) [0|1] ""  Receiver

BO_ 340 ID154RearTorqueOld: 8 VehicleBus
 SG_ RAWTorqueRear154 : 40|12@1- (0.25,0) [-512|511.75] "NM"  Receiver

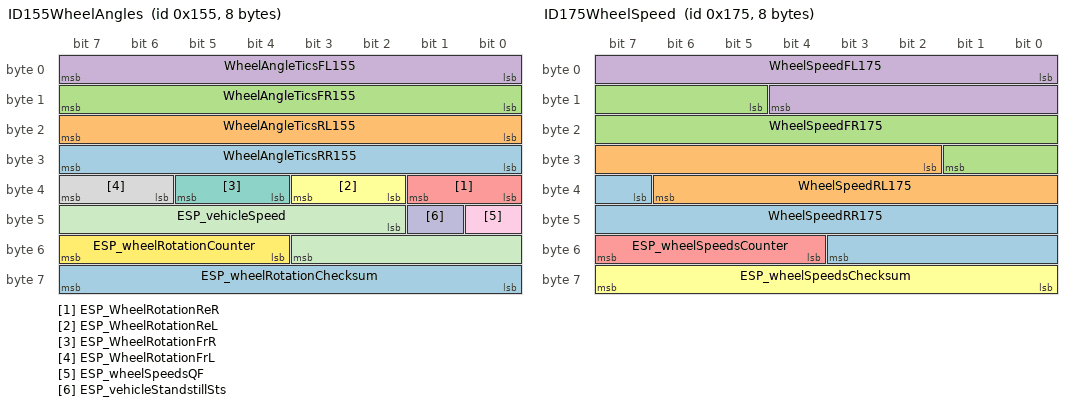
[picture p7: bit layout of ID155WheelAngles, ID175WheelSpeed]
BO_ 341 ID155WheelAngles: 8 ChassisBus
 SG_ WheelAngleTicsRR155 : 24|8@1+ (1.40625,0) [0|358.594] "deg"  Receiver
 SG_ WheelAngleTicsRL155 : 16|8@1+ (1.40625,0) [0|358.594] "deg"  Receiver
 SG_ WheelAngleTicsFR155 : 8|8@1+ (1.40625,0) [0|358.594] "deg"  Receiver
 SG_ WheelAngleTicsFL155 : 0|8@1+ (1.40625,0) [0|358.594] "deg"  Receiver
 SG_ ESP_WheelRotationReR : 32|2@1+ (1,0) [0|3] ""  Receiver
 SG_ ESP_WheelRotationReL : 34|2@1+ (1,0) [0|3] ""  Receiver
 SG_ ESP_WheelRotationFrR : 36|2@1+ (1,0) [0|3] ""  Receiver
 SG_ ESP_WheelRotationFrL : 38|2@1+ (1,0) [0|3] ""  Receiver
 SG_ ESP_wheelSpeedsQF : 40|1@1+ (1,0) [0|1] ""  Receiver
 SG_ ESP_vehicleStandstillSts : 41|1@1+ (1,0) [0|1] ""  Receiver
 SG_ ESP_vehicleSpeed : 42|10@1+ (0.5,0) [0|511] "kph"  Receiver
 SG_ ESP_wheelRotationCounter : 52|4@1+ (1,0) [0|15] ""  Receiver
 SG_ ESP_wheelRotationChecksum : 56|8@1+ (1,0) [0|255] ""  Receiver

BO_ 371 UI_presentPhoneKey3Info: 8 VEH
 SG_ UI_presentPhoneKey3SHA1: 10|54@1+ (1024,0) [0|0] "" X

BO_ 373 ID175WheelSpeed: 8 ChassisBus
 SG_ WheelSpeedRR175 : 39|13@1+ (0.04,0) [0|327.64] "KPH"  Receiver
 SG_ WheelSpeedRL175 : 26|13@1+ (0.04,0) [0|327.64] "KPH"  Receiver
 SG_ WheelSpeedFR175 : 13|13@1+ (0.04,0) [0|327.64] "KPH"  Receiver
 SG_ WheelSpeedFL175 : 0|13@1+ (0.04,0) [0|327.64] "KPH"  Receiver
 SG_ ESP_wheelSpeedsCounter : 52|4@1+ (1,0) [0|15] ""  Receiver
 SG_ ESP_wheelSpeedsChecksum : 56|8@1+ (1,0) [0|255] ""  Receiver

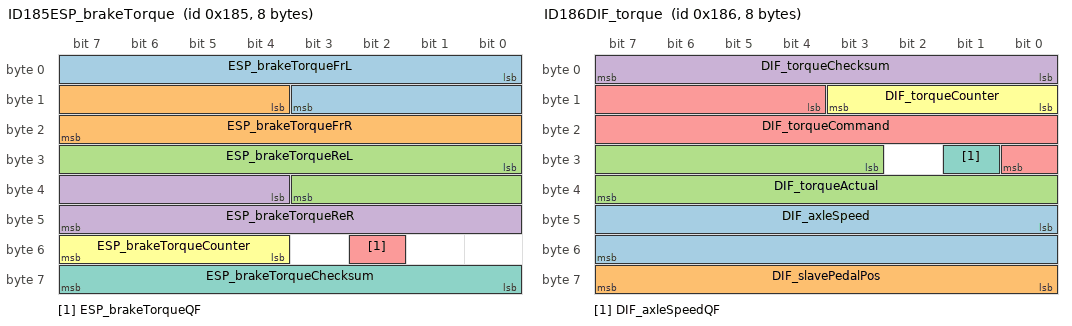
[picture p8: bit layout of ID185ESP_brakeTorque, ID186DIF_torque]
BO_ 389 ID185ESP_brakeTorque: 8 ChassisBus
 SG_ ESP_brakeTorqueFrL : 0|12@1+ (2,0) [0|8190] "Nm"  Receiver
 SG_ ESP_brakeTorqueFrR : 12|12@1+ (2,0) [0|8190] "Nm"  Receiver
 SG_ ESP_brakeTorqueReL : 24|12@1+ (2,0) [0|8190] "Nm"  Receiver
 SG_ ESP_brakeTorqueReR : 36|12@1+ (2,0) [0|8190] "Nm"  Receiver
 SG_ ESP_brakeTorqueQF : 50|1@1+ (1,0) [0|1] ""  Receiver
 SG_ ESP_brakeTorqueCounter : 52|4@1+ (1,0) [0|15] ""  Receiver
 SG_ ESP_brakeTorqueChecksum : 56|8@1+ (1,0) [0|255] ""  Receiver

BO_ 390 ID186DIF_torque: 8 VehicleBus
 SG_ DIF_axleSpeed : 40|16@1- (0.1,0) [-2750|2750] "RPM"  Receiver
 SG_ DIF_slavePedalPos : 56|8@1+ (0.4,0) [0|100] "%"  Receiver
 SG_ DIF_torqueActual : 27|13@1- (2,0) [-7500|7500] "Nm"  Receiver
 SG_ DIF_torqueChecksum : 0|8@1+ (1,0) [0|255] ""  Receiver
 SG_ DIF_torqueCommand : 12|13@1- (2,0) [-7500|7500] "Nm"  Receiver
 SG_ DIF_torqueCounter : 8|4@1+ (1,0) [0|15] ""  Receiver
 SG_ DIF_axleSpeedQF : 25|1@1+ (1,0) [0|1] ""  Receiver

BO_ 392 DIS_capability2: 2 VEH
 SG_ DIS_heatPowerMax: 8|8@1+ (0.08,0) [0|0] "kW" X
 SG_ DIS_heatPowerOptimal: 0|8@1+ (0.08,0) [0|0] "kW" X

BO_ 421 ID1A5FrontHVStatus: 7 VehicleBus
 SG_ FrontHighVoltage1A5 : 0|10@1+ (0.5,0) [0|500] "V"  Receiver
 SG_ FrontMotorCurrent1A5 : 11|11@1+ (1,0) [0|2047] "A"  Receiver
 SG_ DIF_switchingFrequency : 40|11@1+ (0.01,0) [0|20] "kHz"  Receiver
 SG_ DIF_dcCableCurrentEst : 24|16@1- (0.1,0) [-3276.8|3276.7] "A"  Receiver
 SG_ DIF_vBatQF : 10|1@1+ (1,0) [0|0] ""  Receiver
 SG_ DIF_targetFluxMode : 51|2@1+ (1,0) [0|0] ""  Receiver

BO_ 435 UI_presentPhoneKey2Info: 8 VEH
 SG_ UI_presentPhoneKey2SHA1: 10|54@1+ (1024,0) [0|0] "" X

BO_ 463 PM_systemState: 8 GTW
 SG_ PM_hvilSystemStatus : 24|2@1+ (1,0) [0|3] "" ODIN

BO_ 468 ID1D4FrontTorqueOld: 8 VehicleBus
 SG_ RAWTorqueFront1D4 : 40|12@1- (0.25,0) [-512|511.75] "NM"  Receiver

BO_ 469 ID1D5FrontTorque: 8 VehicleBus
 SG_ FrontTorqueRequest1D5 : 8|13@1- (0.222,0) [-909.312|909.09] "NM"  Receiver
 SG_ FrontTorque1D5 : 21|13@1- (0.222,0) [-909.312|909.09] "NM"  Receiver

BO_ 470 ID1D6DI_limits: 5 VehicleBus
 SG_ DI_limitBaseSpeed : 15|1@1+ (1,0) [0|1] ""  Receiver
 SG_ DI_limitClutch : 28|1@1+ (1,0) [0|1] ""  Receiver
 SG_ DI_limitDcCapTemp : 17|1@1+ (1,0) [0|1] ""  Receiver
 SG_ DI_limitDeltaFluidTemp : 5|1@1+ (1,0) [0|1] ""  Receiver
 SG_ DI_limitDiff : 22|1@1+ (1,0) [0|1] ""  Receiver
 SG_ DI_limitDischargePower : 6|1@1+ (1,0) [0|1] ""  Receiver
 SG_ DI_limitDriveTorque : 10|1@1+ (1,0) [0|1] ""  Receiver
 SG_ DI_limitGracefulPowerOff : 23|1@1+ (1,0) [0|1] ""  Receiver
 SG_ DI_limitIBat : 16|1@1+ (1,0) [0|1] ""  Receiver
 SG_ DI_limitIGBTJunctTemp : 24|1@1+ (1,0) [0|1] ""  Receiver
 SG_ DI_limitInverterTemp : 1|1@1+ (1,0) [0|1] ""  Receiver
 SG_ DI_limitLimpMode : 4|1@1+ (1,0) [0|1] ""  Receiver
 SG_ DI_limitMotorCurrent : 8|1@1+ (1,0) [0|1] ""  Receiver
 SG_ DI_limitMotorSpeed : 20|1@1+ (1,0) [0|1] ""  Receiver
 SG_ DI_limitMotorVoltage : 9|1@1+ (1,0) [0|1] ""  Receiver
 SG_ DI_limitObstacleDetection : 29|1@1+ (1,0) [0|1] ""  Receiver
 SG_ DI_limitOilPumpFluidTemp : 26|1@1+ (1,0) [0|1] ""  Receiver
 SG_ DI_limitPCBTemp : 0|1@1+ (1,0) [0|1] ""  Receiver
 SG_ DI_limitPoleTemp : 3|1@1+ (1,0) [0|1] ""  Receiver
 SG_ DI_limitRegenPower : 7|1@1+ (1,0) [0|1] ""  Receiver
 SG_ DI_limitRegenTorque : 11|1@1+ (1,0) [0|1] ""  Receiver
 SG_ DI_limitRotorTemp : 36|1@1+ (1,0) [0|1] ""  Receiver
 SG_ DI_limitShift : 14|1@1+ (1,0) [0|1] ""  Receiver
 SG_ DI_limitShockTorque : 25|1@1+ (1,0) [0|1] ""  Receiver
 SG_ DI_limitStatorFrequency : 27|1@1+ (1,0) [0|1] ""  Receiver
 SG_ DI_limitStatorTemp : 2|1@1+ (1,0) [0|1] ""  Receiver
 SG_ DI_limitTCDrive : 12|1@1+ (1,0) [0|1] ""  Receiver
 SG_ DI_limitTCRegen : 13|1@1+ (1,0) [0|1] ""  Receiver
 SG_ DI_limitVBatHigh : 19|1@1+ (1,0) [0|1] ""  Receiver
 SG_ DI_limitVBatLow : 18|1@1+ (1,0) [0|1] ""  Receiver
 SG_ DI_limitVehicleSpeed : 21|1@1+ (1,0) [0|1] ""  Receiver
 SG_ DI_limitdcLinkCapTemp : 33|1@1+ (1,0) [0|1] ""  Receiver
 SG_ DI_limithvDcCableTemp : 37|1@1+ (1,0) [0|1] ""  Receiver
 SG_ DI_limitnegDcBusbarTemp : 34|1@1+ (1,0) [0|1] ""  Receiver
 SG_ DI_limitphaseOutBusBarWeldTemp : 31|1@1+ (1,0) [0|1] ""  Receiver
 SG_ DI_limitphaseOutBusbarTemp : 30|1@1+ (1,0) [0|1] ""  Receiver
 SG_ DI_limitphaseOutLugTemp : 32|1@1+ (1,0) [0|1] ""  Receiver
 SG_ DI_limitposDcBusbarTemp : 35|1@1+ (1,0) [0|1] ""  Receiver

BO_ 472 ID1D8RearTorque: 8 VehicleBus
 SG_ Checksum1D8 : 56|8@1+ (1,0) [0|255] ""  Receiver
 SG_ Counter1D8 : 53|3@1+ (1,0) [0|7] ""  Receiver
 SG_ RearTorqueRequest1D8 : 8|13@1- (0.222,0) [-909.312|909.09] "NM"  Receiver
 SG_ RearTorque1D8 : 21|13@1- (0.222,0) [-909.312|909.09] "NM"  Receiver
 SG_ TorqueFlags1D8 : 0|8@1+ (1,0) [0|255] ""  Receiver

BO_ 473 VCSEC_IsoTpUDPPipeUI: 8 VEH
 SG_ VCSEC_IsoTpUDPPipeUI0: 0|8@1+ (1,0) [0|0] "" X
 SG_ VCSEC_IsoTpUDPPipeUI1: 8|8@1+ (1,0) [0|0] "" X
 SG_ VCSEC_IsoTpUDPPipeUI2: 16|8@1+ (1,0) [0|0] "" X
 SG_ VCSEC_IsoTpUDPPipeUI3: 24|8@1+ (1,0) [0|0] "" X
 SG_ VCSEC_IsoTpUDPPipeUI4: 32|8@1+ (1,0) [0|0] "" X
 SG_ VCSEC_IsoTpUDPPipeUI5: 40|8@1+ (1,0) [0|0] "" X
 SG_ VCSEC_IsoTpUDPPipeUI6: 48|8@1+ (1,0) [0|0] "" X
 SG_ VCSEC_IsoTpUDPPipeUI7: 56|8@1+ (1,0) [0|0] "" X

BO_ 499 UI_presentPhoneKey1Info: 8 VEH
 SG_ UI_presentPhoneKey1SHA1: 10|54@1+ (1024,0) [0|0] "" X

BO_ 505 VCSEC_requests: 1 VEH
 SG_ VCSEC_chargePortRequest: 0|2@1+ (1,0) [0|0] "" X
 SG_ VCSEC_driveAttemptedWithoutAuth: 2|1@1+ (1,0) [0|0] "" X

BO_ 513 ID201VCFRONT_loggingAndVitals10H: 8 VehicleBus
 SG_ VCFRONT_loggingAndVitals10HzInde M : 0|3@1+ (1,0) [0|7] ""  Receiver
 SG_ VCFRONT_activeLouverOpenPos m1 : 16|7@1+ (1,0) [0|100] "%"  Receiver
 SG_ VCFRONT_activeLouverOpenPosTarg m1 : 8|7@1+ (1,0) [0|100] "%"  Receiver
 SG_ VCFRONT_cclExvFlow m3 : 44|10@1+ (0.1,0) [0|100] "%"  Receiver
 SG_ VCFRONT_cclExvFlowTarget m5 : 44|10@1+ (0.1,0) [0|100] "%"  Receiver
 SG_ VCFRONT_cclExvState m6 : 20|4@1+ (1,0) [0|9] ""  Receiver
 SG_ VCFRONT_ccrExvFlow m3 : 54|10@1+ (0.1,0) [0|100] "%"  Receiver
 SG_ VCFRONT_ccrExvFlowTarget m5 : 54|10@1+ (0.1,0) [0|100] "%"  Receiver
 SG_ VCFRONT_ccrExvState m6 : 24|4@1+ (1,0) [0|9] ""  Receiver
 SG_ VCFRONT_chillerExvFlow m3 : 3|10@1+ (0.1,0) [0|100] "%"  Receiver
 SG_ VCFRONT_chillerExvFlowTarget m5 : 3|10@1+ (0.1,0) [0|100] "%"  Receiver
 SG_ VCFRONT_chillerExvState m6 : 3|4@1+ (1,0) [0|9] ""  Receiver
 SG_ VCFRONT_compDemandChiller m2 : 39|7@1+ (1,0) [0|100] "%"  Receiver
 SG_ VCFRONT_compDemandEvap m2 : 26|7@1+ (1,0) [0|100] "%"  Receiver
 SG_ VCFRONT_compressorState m2 : 24|2@1+ (1,0) [0|3] ""  Receiver
 SG_ VCFRONT_coolantValveMode m2 : 61|2@1+ (1,0) [0|3] ""  Receiver
 SG_ VCFRONT_evapExvFlow m3 : 13|10@1+ (0.1,0) [0|100] "%"  Receiver
 SG_ VCFRONT_evapExvFlowTarget m5 : 13|10@1+ (0.1,0) [0|100] "%"  Receiver
 SG_ VCFRONT_evapExvState m6 : 8|4@1+ (1,0) [0|9] ""  Receiver
 SG_ VCFRONT_exvFlowTarget m0 : 54|10@1+ (0.1,0) [0|100] "%"  Receiver
 SG_ VCFRONT_exvState m2 : 33|4@1+ (1,0) [0|9] ""  Receiver
 SG_ VCFRONT_fanDemand m2 : 16|7@1+ (1,0) [0|100] "%"  Receiver
 SG_ VCFRONT_hpBatteryLoadType m4 : 16|2@1+ (1,0) [0|2] ""  Receiver
 SG_ VCFRONT_hpBlendType m4 : 11|2@1+ (1,0) [0|2] ""  Receiver
 SG_ VCFRONT_hpCabinLoadType m4 : 14|2@1+ (1,0) [0|3] ""  Receiver
 SG_ VCFRONT_hpDominantLoad m4 : 8|3@1+ (1,0) [0|6] ""  Receiver
 SG_ VCFRONT_hpHighSideHX m4 : 3|2@1+ (1,0) [0|3] ""  Receiver
 SG_ VCFRONT_hpLowSideHX m4 : 5|2@1+ (1,0) [0|3] ""  Receiver
 SG_ VCFRONT_hpQuietModeEnabled m4 : 13|1@1+ (1,0) [0|1] ""  Receiver
 SG_ VCFRONT_hpReqCoolantMode m4 : 18|3@1+ (1,0) [0|4] ""  Receiver
 SG_ VCFRONT_lccExvFlow m3 : 34|10@1+ (0.1,0) [0|100] "%"  Receiver
 SG_ VCFRONT_lccExvFlowTarget m5 : 34|10@1+ (0.1,0) [0|100] "%"  Receiver
 SG_ VCFRONT_lccExvState m6 : 16|4@1+ (1,0) [0|9] ""  Receiver
 SG_ VCFRONT_pressureRefrigDischargeV m2 : 53|8@1+ (0.125,0) [0|31.75] "bar"  Receiver
 SG_ VCFRONT_pressureRefrigLiquid m1 : 40|8@1+ (0.125,0) [0|31.75] "bar"  Receiver
 SG_ VCFRONT_pressureRefrigSuctionVit m2 : 46|7@1+ (0.125,0) [0|11.5] "bar"  Receiver
 SG_ VCFRONT_pumpBatteryRPMActual m0 : 3|10@1+ (10,0) [0|10000] "rpm"  Receiver
 SG_ VCFRONT_pumpPowertrainRPMActual m0 : 13|10@1+ (10,0) [0|10000] "rpm"  Receiver
 SG_ VCFRONT_radiatorFanRPMActual m0 : 24|10@1+ (10,0) [0|10000] "rpm"  Receiver
 SG_ VCFRONT_recircExvFlow m3 : 24|10@1+ (0.1,0) [0|100] "%"  Receiver
 SG_ VCFRONT_recircExvFlowTarget m5 : 24|10@1+ (0.1,0) [0|100] "%"  Receiver
 SG_ VCFRONT_recircExvState m6 : 12|4@1+ (1,0) [0|9] ""  Receiver
 SG_ VCFRONT_solenoidEvapState m2 : 37|2@1+ (1,0) [0|3] ""  Receiver
 SG_ VCFRONT_tempRefrigDischarge m2 : 3|11@1+ (0.125,-40) [-40|150] "C"  Receiver
 SG_ VCFRONT_tempRefrigLiquid m1 : 24|11@1+ (0.125,-40) [-40|150] "C"  Receiver
 SG_ VCFRONT_tempSuperheatActFiltered m1 : 48|8@1- (0.25,26.5) [-5|58] "C"  Receiver
 SG_ VCFRONT_tempSuperheatActual m0 : 34|10@1+ (0.1,-20) [-20|80] "C"  Receiver
 SG_ VCFRONT_tempSuperheatTarget m0 : 44|10@1+ (0.1,0) [0|60] "C"  Receiver

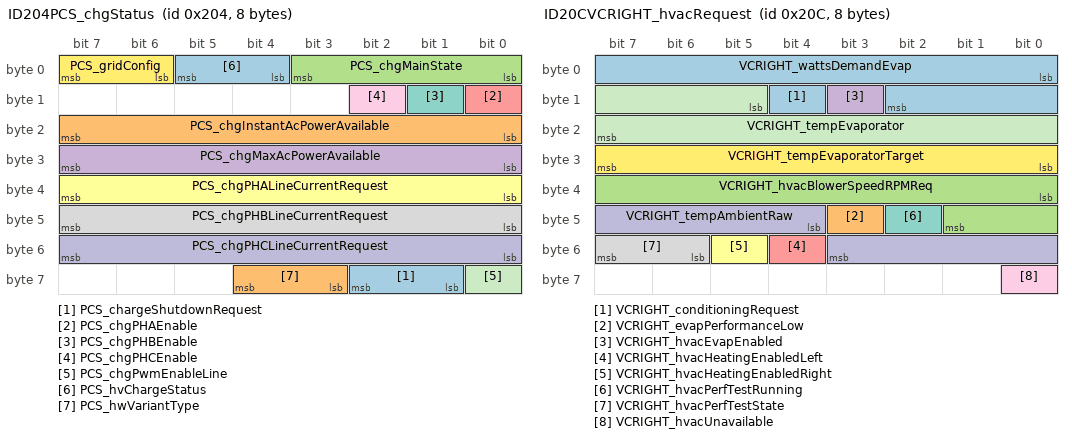
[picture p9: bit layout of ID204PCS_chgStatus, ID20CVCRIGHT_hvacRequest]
BO_ 516 ID204PCS_chgStatus: 8 VehicleBus
 SG_ PCS_chargeShutdownRequest : 57|2@1+ (1,0) [0|2] ""  Receiver
 SG_ PCS_chgInstantAcPowerAvailable : 16|8@1+ (0.1,0) [0|20] "kW"  Receiver
 SG_ PCS_chgMainState : 0|4@1+ (1,0) [0|9] ""  Receiver
 SG_ PCS_chgMaxAcPowerAvailable : 24|8@1+ (0.1,0) [0|20] "kW"  Receiver
 SG_ PCS_chgPHAEnable : 8|1@1+ (1,0) [0|1] ""  Receiver
 SG_ PCS_chgPHALineCurrentRequest : 32|8@1+ (0.1,0) [0|20] "A"  Receiver
 SG_ PCS_chgPHBEnable : 9|1@1+ (1,0) [0|1] ""  Receiver
 SG_ PCS_chgPHBLineCurrentRequest : 40|8@1+ (0.1,0) [0|20] "A"  Receiver
 SG_ PCS_chgPHCEnable : 10|1@1+ (1,0) [0|1] ""  Receiver
 SG_ PCS_chgPHCLineCurrentRequest : 48|8@1+ (0.1,0) [0|20] "A"  Receiver
 SG_ PCS_chgPwmEnableLine : 56|1@1+ (1,0) [0|1] ""  Receiver
 SG_ PCS_gridConfig : 6|2@1+ (1,0) [0|3] ""  Receiver
 SG_ PCS_hvChargeStatus : 4|2@1+ (1,0) [0|3] ""  Receiver
 SG_ PCS_hwVariantType : 59|2@1+ (1,0) [0|3] ""  Receiver

BO_ 522 ID20AHVP_contactorState: 6 VehicleBus
 SG_ HVP_dcLinkAllowedToEnergize : 36|1@1+ (1,0) [0|1] ""  Receiver
 SG_ HVP_fcContNegativeAuxOpen : 7|1@1+ (1,0) [0|1] ""  Receiver
 SG_ HVP_fcContNegativeState : 12|3@1+ (1,0) [0|7] ""  Receiver
 SG_ HVP_fcContPositiveAuxOpen : 6|1@1+ (1,0) [0|1] ""  Receiver
 SG_ HVP_fcContPositiveState : 16|3@1+ (1,0) [0|7] ""  Receiver
 SG_ HVP_fcContactorSetState : 19|4@1+ (1,0) [0|9] ""  Receiver
 SG_ HVP_fcCtrsClosingAllowed : 29|1@1+ (1,0) [0|1] ""  Receiver
 SG_ HVP_fcCtrsOpenNowRequested : 27|1@1+ (1,0) [0|1] ""  Receiver
 SG_ HVP_fcCtrsOpenRequested : 28|1@1+ (1,0) [0|1] ""  Receiver
 SG_ HVP_fcCtrsRequestStatus : 24|2@1+ (1,0) [0|2] ""  Receiver
 SG_ HVP_fcCtrsResetRequestRequired : 26|1@1+ (1,0) [0|1] ""  Receiver
 SG_ HVP_fcLinkAllowedToEnergize : 44|2@1+ (1,0) [0|2] ""  Receiver
 SG_ HVP_hvilStatus : 40|4@1+ (1,0) [0|9] ""  Receiver
 SG_ HVP_packContNegativeState : 0|3@1+ (1,0) [0|7] ""  Receiver
 SG_ HVP_packContPositiveState : 3|3@1+ (1,0) [0|7] ""  Receiver
 SG_ HVP_packContactorSetState : 8|4@1+ (1,0) [0|9] ""  Receiver
 SG_ HVP_packCtrsClosingAllowed : 35|1@1+ (1,0) [0|1] ""  Receiver
 SG_ HVP_packCtrsOpenNowRequested : 33|1@1+ (1,0) [0|1] ""  Receiver
 SG_ HVP_packCtrsOpenRequested : 34|1@1+ (1,0) [0|1] ""  Receiver
 SG_ HVP_packCtrsRequestStatus : 30|2@1+ (1,0) [0|2] ""  Receiver
 SG_ HVP_packCtrsResetRequestRequired : 32|1@1+ (1,0) [0|1] ""  Receiver
 SG_ HVP_pyroTestInProgress : 37|1@1+ (1,0) [0|1] ""  Receiver

BO_ 523 TAS_heights: 8 VEH
 SG_ TAS_fastFilteredHeightFL: 0|8@1+ (1,-128) [0|0] "mm" X
 SG_ TAS_fastFilteredHeightFR: 8|8@1+ (1,-128) [0|0] "mm" X
 SG_ TAS_fastFilteredHeightRL: 16|8@1+ (1,-128) [0|0] "mm" X
 SG_ TAS_fastFilteredHeightRR: 24|8@1+ (1,-128) [0|0] "mm" X
 SG_ TAS_modeFilteredHeightFL: 32|8@1+ (1,-128) [0|0] "mm" X
 SG_ TAS_modeFilteredHeightFR: 40|8@1+ (1,-128) [0|0] "mm" X
 SG_ TAS_modeFilteredHeightRL: 48|8@1+ (1,-128) [0|0] "mm" X
 SG_ TAS_modeFilteredHeightRR: 56|8@1+ (1,-128) [0|0] "mm" X

BO_ 524 ID20CVCRIGHT_hvacRequest: 8 VehicleBus
 SG_ VCRIGHT_conditioningRequest : 12|1@1+ (1,0) [0|1] ""  Receiver
 SG_ VCRIGHT_evapPerformanceLow : 43|1@1+ (1,0) [0|1] ""  Receiver
 SG_ VCRIGHT_hvacBlowerSpeedRPMReq : 32|10@1+ (5,0) [0|5115] "RPM"  Receiver
 SG_ VCRIGHT_hvacEvapEnabled : 11|1@1+ (1,0) [0|1] ""  Receiver
 SG_ VCRIGHT_hvacHeatingEnabledLeft : 52|1@1+ (1,0) [0|1] ""  Receiver
 SG_ VCRIGHT_hvacHeatingEnabledRight : 53|1@1+ (1,0) [0|1] ""  Receiver
 SG_ VCRIGHT_hvacPerfTestRunning : 42|1@1+ (1,0) [0|1] ""  Receiver
 SG_ VCRIGHT_hvacPerfTestState : 54|2@1+ (1,0) [0|2] ""  Receiver
 SG_ VCRIGHT_hvacUnavailable : 56|1@1+ (1,0) [0|1] ""  Receiver
 SG_ VCRIGHT_tempAmbientRaw : 44|8@1+ (0.5,-40) [-40|80] "C"  Receiver
 SG_ VCRIGHT_tempEvaporator : 13|11@1+ (0.1,-40) [-40|105] "C"  Receiver
 SG_ VCRIGHT_tempEvaporatorTarget : 24|8@1+ (0.2,0) [0|50] "C"  Receiver
 SG_ VCRIGHT_wattsDemandEvap : 0|11@1+ (5,0) [0|10000] "W"  Receiver

BO_ 525 TAS_states: 8 VEH
 SG_ TAS_compressorRun: 30|1@1+ (1,0) [0|0] "" X
 SG_ TAS_currentLevel: 42|3@1+ (1,0) [0|0] "" X
 SG_ TAS_filterMode: 27|3@1+ (1,0) [0|0] "" X
 SG_ TAS_highAllowed: 36|1@1+ (1,0) [0|0] "" X
 SG_ TAS_jackMode: 38|1@1+ (1,0) [0|0] "" X
 SG_ TAS_leanDetected: 32|1@1+ (1,0) [0|0] "" X
 SG_ TAS_levelingState: 0|4@1+ (1,0) [0|0] "" X
 SG_ TAS_levelingType: 4|4@1+ (1,0) [0|0] "" X
 SG_ TAS_limpHomeMode: 48|3@1+ (1,0) [0|0] "" X
 SG_ TAS_lowAllowed: 34|1@1+ (1,0) [0|0] "" X
 SG_ TAS_pressureGallery: 8|8@1+ (0.1,0) [0|0] "bar" X
 SG_ TAS_pressureReservoir: 16|8@1+ (0.1,0) [0|0] "bar" X
 SG_ TAS_redWarningLamp: 40|1@1+ (1,0) [0|0] "" X
 SG_ TAS_runMode: 24|3@1+ (1,0) [0|0] "" X
 SG_ TAS_spinnerUI: 41|1@1+ (1,0) [0|0] "" X
 SG_ TAS_standardAllowed: 35|1@1+ (1,0) [0|0] "" X
 SG_ TAS_statesChecksum: 56|8@1+ (1,0) [0|0] "" X
 SG_ TAS_statesCounter: 52|4@1+ (1,0) [0|0] "" X
 SG_ TAS_targetLevel: 45|3@1+ (1,0) [0|0] "" X
 SG_ TAS_twistDetected: 31|1@1+ (1,0) [0|0] "" X
 SG_ TAS_veryHighAllowed: 37|1@1+ (1,0) [0|0] "" X
 SG_ TAS_veryLowAllowed: 33|1@1+ (1,0) [0|0] "" X
 SG_ TAS_yellowWarningLamp: 39|1@1+ (1,0) [0|0] "" X

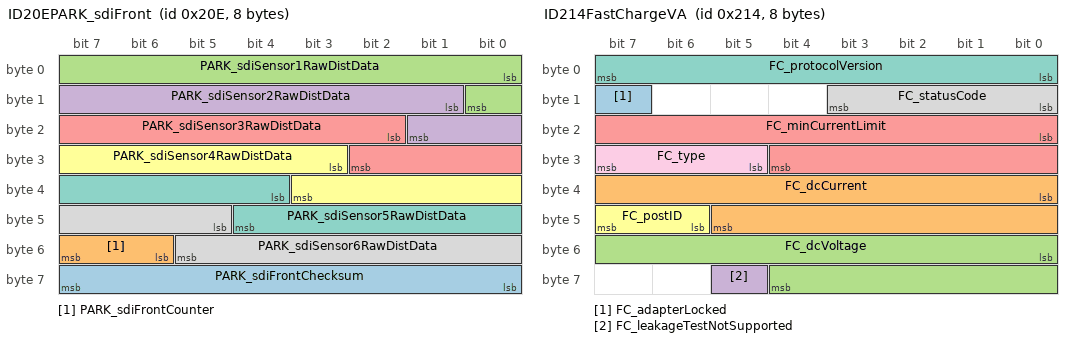
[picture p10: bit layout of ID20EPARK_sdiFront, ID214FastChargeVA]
BO_ 526 ID20EPARK_sdiFront: 8 ChassisBus
 SG_ PARK_sdiFrontChecksum : 56|8@1+ (1,0) [0|255] ""  Receiver
 SG_ PARK_sdiFrontCounter : 54|2@1+ (1,0) [0|3] ""  Receiver
 SG_ PARK_sdiSensor1RawDistData : 0|9@1+ (1,0) [0|511] "cm"  Receiver
 SG_ PARK_sdiSensor2RawDistData : 9|9@1+ (1,0) [0|511] "cm"  Receiver
 SG_ PARK_sdiSensor3RawDistData : 18|9@1+ (1,0) [0|511] "cm"  Receiver
 SG_ PARK_sdiSensor4RawDistData : 27|9@1+ (1,0) [0|511] "cm"  Receiver
 SG_ PARK_sdiSensor5RawDistData : 36|9@1+ (1,0) [0|511] "cm"  Receiver
 SG_ PARK_sdiSensor6RawDistData : 45|9@1+ (1,0) [0|511] "cm"  Receiver

BO_ 528 CP_status: 8 GTW
 SG_ CP_chargeCableState : 14|2@1+ (1,0) [0|2] "" ODIN,UI,VITALS

BO_ 529 RCM_status: 6 GTW
 SG_ RCM_armStatus : 12|2@1+ (1,0) [0|3] "" ODIN,SUI,UI

BO_ 530 ID212BMS_status: 8 VehicleBus
 SG_ BMS_activeHeatingWorthwhile : 5|1@1+ (1,0) [0|1] ""  Receiver
 SG_ BMS_chargeRequest : 29|1@1+ (1,0) [0|1] ""  Receiver
 SG_ BMS_chargeRetryCount : 51|3@1+ (1,0) [0|7] ""  Receiver
 SG_ BMS_chgPowerAvailable : 40|11@1+ (0.125,0) [0|255.75] "kW"  Receiver
 SG_ BMS_contactorState : 8|3@1+ (1,0) [0|6] ""  Receiver
 SG_ BMS_cpMiaOnHvs : 6|1@1+ (1,0) [0|1] ""  Receiver
 SG_ BMS_diLimpRequest : 36|1@1+ (1,0) [0|1] ""  Receiver
 SG_ BMS_ecuLogUploadRequest : 14|2@1+ (1,0) [0|3] ""  Receiver
 SG_ BMS_hvState : 16|3@1+ (1,0) [0|6] ""  Receiver
 SG_ BMS_hvacPowerRequest : 0|1@1+ (1,0) [0|1] ""  Receiver
 SG_ BMS_isolationResistance : 19|10@1+ (10,0) [0|10000] "kOhm"  Receiver
 SG_ BMS_keepWarmRequest : 30|1@1+ (1,0) [0|1] ""  Receiver
 SG_ BMS_notEnoughPowerForDrive : 1|1@1+ (1,0) [0|1] ""  Receiver
 SG_ BMS_notEnoughPowerForSupport : 2|1@1+ (1,0) [0|1] ""  Receiver
 SG_ BMS_okToShipByAir : 37|1@1+ (1,0) [0|1] ""  Receiver
 SG_ BMS_okToShipByLand : 38|1@1+ (1,0) [0|1] ""  Receiver
 SG_ BMS_pcsPwmEnabled : 7|1@1+ (1,0) [0|1] ""  Receiver
 SG_ BMS_preconditionAllowed : 3|1@1+ (1,0) [0|1] ""  Receiver
 SG_ BMS_smStateRequest : 56|4@1+ (1,0) [0|9] ""  Receiver
 SG_ BMS_state : 32|4@1+ (1,0) [0|10] ""  Receiver
 SG_ BMS_uiChargeStatus : 11|3@1+ (1,0) [0|5] ""  Receiver
 SG_ BMS_updateAllowed : 4|1@1+ (1,0) [0|1] ""  Receiver

BO_ 531 UI_cruiseControl: 3 VEH
 SG_ UI_cruiseControlChecksum: 16|8@1+ (1,0) [0|0] "" X
 SG_ UI_cruiseControlCounter: 11|4@1+ (1,0) [0|0] "" X
 SG_ UI_cruiseSpeedCommand: 8|3@1+ (1,0) [0|0] "" X
 SG_ UI_speedLimitTick: 0|8@1+ (1,0) [0|0] "speed" X

BO_ 532 ID214FastChargeVA: 8 VehicleBus
 SG_ FC_adapterLocked : 15|1@1+ (1,0) [0|1] ""  Receiver
 SG_ FC_dcCurrent : 32|14@1- (0.0732422,0) [-600|599.927] "A"  Receiver
 SG_ FC_dcVoltage : 48|13@1+ (0.0732422,0) [0|599.927] "V"  Receiver
 SG_ FC_leakageTestNotSupported : 61|1@1+ (1,0) [0|1] ""  Receiver
 SG_ FC_minCurrentLimit : 16|13@1+ (0.1,0) [0|600] "A"  Receiver
 SG_ FC_postID : 46|2@1+ (1,0) [0|3] ""  Receiver
 SG_ FC_protocolVersion : 0|8@1+ (1,0) [0|255] ""  Receiver
 SG_ FC_statusCode : 8|4@1+ (1,0) [0|15] ""  Receiver
 SG_ FC_type : 29|3@1+ (1,0) [0|7] ""  Receiver

BO_ 533 ID215FCisolation: 1 VehicleBus
 SG_ FCIsolation215 : 0|8@1+ (40,0) [0|10200] "kOhm"  Receiver

BO_ 535 ID217FC_status3: 8 VehicleBus
 SG_ FC_status3DataSelect M : 0|7@1+ (1,0) [0|1] ""  Receiver
 SG_ FC_billingEnergy m1 : 8|16@1+ (0.015259,0) [0|1000] "kWh"  Receiver
 SG_ FC_brand m0 : 16|4@1+ (1,0) [0|1] ""  Receiver
 SG_ FC_class m0 : 8|8@1+ (1,0) [0|2] ""  Receiver
 SG_ FC_coolingType m0 : 20|4@1+ (1,0) [0|2] ""  Receiver
 SG_ FC_generation m0 : 32|8@1+ (1,0) [0|255] ""  Receiver
 SG_ FC_status3DummySig : 7|1@1+ (1,0) [0|1] ""  Receiver
 SG_ FC_uiStopType m0 : 24|4@1+ (1,0) [0|2] ""  Receiver

BO_ 536 UI_driverAssistRoadSign: 8 VEH
 SG_ UI_roadSign M: 0|8@1+ (1,0) [0|0] "" X
 SG_ UI_roadSignChecksum: 56|8@1+ (1,0) [0|0] "" X
 SG_ UI_roadSignCounter: 52|4@1+ (1,0) [0|0] "" X
 SG_ UI_splineID: 48|4@1+ (1,0) [0|0] "" X
 SG_ UI_splineLocConfidence: 40|7@1+ (1,0) [0|0] "1" X
 SG_ UI_dummyData m0: 8|1@1+ (1,0) [0|0] "" X
 SG_ UI_stopSignStopLineDist m1: 8|10@1+ (0.25,-8) [0|0] "m" X
 SG_ UI_stopSignStopLineConf m1: 18|7@1+ (1,0) [0|0] "1" X
 SG_ UI_trafficLightStopLineDist m2: 8|10@1+ (0.25,-8) [0|0] "m" X
 SG_ UI_trafficLightStopLineConf m2: 18|7@1+ (1,0) [0|0] "1" X
 SG_ UI_baseMapSpeedLimitMPS m3: 8|8@1+ (0.25,0) [0|0] "m/s" X
 SG_ UI_bottomQrtlFleetSpeedMPS m3: 16|8@1+ (0.25,0) [0|0] "m/s" X
 SG_ UI_topQrtlFleetSpeedMPS m3: 24|8@1+ (0.25,0) [0|0] "m/s" X
 SG_ UI_meanFleetSplineSpeedMPS m4: 8|8@1+ (0.25,0) [0|0] "m/s" X
 SG_ UI_medianFleetSpeedMPS m4: 16|8@1+ (0.25,0) [0|0] "m/s" X
 SG_ UI_meanFleetSplineAccelMPS2 m4: 24|8@1+ (0.05,-6.35) [0|0] "m/s^2" X
 SG_ UI_rampType m4: 32|3@1+ (1,0) [0|0] "" X
 SG_ UI_currSplineIdFull m5: 8|32@1+ (1,0) [0|0] "1" X

BO_ 537 ID219VCSEC_TPMSData: 5 ChassisBus
 SG_ VCSEC_TPMSDataIndex M : 0|2@1+ (1,0) [0|3] ""  Receiver
 SG_ VCSEC_TPMSBatVoltage0 m0 : 24|8@1+ (0.01,1.5) [1.5|4.04] "V"  Receiver
 SG_ VCSEC_TPMSBatVoltage1 m1 : 24|8@1+ (0.01,1.5) [1.5|4.04] "V"  Receiver
 SG_ VCSEC_TPMSBatVoltage2 m2 : 24|8@1+ (0.01,1.5) [1.5|4.04] "V"  Receiver
 SG_ VCSEC_TPMSBatVoltage3 m3 : 24|8@1+ (0.01,1.5) [1.5|4.04] "V"  Receiver
 SG_ VCSEC_TPMSLocation0 m0 : 32|3@1+ (1,0) [0|4] ""  Receiver
 SG_ VCSEC_TPMSLocation1 m1 : 32|3@1+ (1,0) [0|4] ""  Receiver
 SG_ VCSEC_TPMSLocation2 m2 : 32|3@1+ (1,0) [0|4] ""  Receiver
 SG_ VCSEC_TPMSLocation3 m3 : 32|3@1+ (1,0) [0|4] ""  Receiver
 SG_ VCSEC_TPMSPressure0 m0 : 8|8@1+ (0.025,0) [0|6.35] "bar"  Receiver
 SG_ VCSEC_TPMSPressure1 m1 : 8|8@1+ (0.025,0) [0|6.35] "bar"  Receiver
 SG_ VCSEC_TPMSPressure2 m2 : 8|8@1+ (0.025,0) [0|6.35] "bar"  Receiver
 SG_ VCSEC_TPMSPressure3 m3 : 8|8@1+ (0.025,0) [0|6.35] "bar"  Receiver
 SG_ VCSEC_TPMSTemperature0 m0 : 16|8@1+ (1,-40) [-40|214] "C"  Receiver
 SG_ VCSEC_TPMSTemperature1 m1 : 16|8@1+ (1,-40) [-40|214] "C"  Receiver
 SG_ VCSEC_TPMSTemperature2 m2 : 16|8@1+ (1,-40) [-40|214] "C"  Receiver
 SG_ VCSEC_TPMSTemperature3 m3 : 16|8@1+ (1,-40) [-40|214] "C"  Receiver

BO_ 541 ID21DCP_evseStatus: 8 VehicleBus
 SG_ CP_acChargeState : 53|3@1+ (1,0) [0|6] ""  Receiver
 SG_ CP_acNumRetries : 40|2@1+ (1,0) [0|3] ""  Receiver
 SG_ CP_cableCurrentLimit : 24|7@1+ (1,0) [0|127] "A"  Receiver
 SG_ CP_cableType : 16|3@1+ (1,0) [0|4] ""  Receiver
 SG_ CP_digitalCommsAttempts : 32|2@1+ (1,0) [0|3] ""  Receiver
 SG_ CP_digitalCommsEstablished : 37|1@1+ (1,0) [0|1] ""  Receiver
 SG_ CP_evseAccept : 0|1@1+ (1,0) [0|1] ""  Receiver
 SG_ CP_evseChargeType_UI : 38|2@1+ (1,0) [0|2] ""  Receiver
 SG_ CP_evseRequest : 1|1@1+ (1,0) [0|1] ""  Receiver
 SG_ CP_gbState : 42|4@1+ (1,0) [0|15] ""  Receiver
 SG_ CP_gbdcChargeAttempts : 51|2@1+ (1,0) [0|3] ""  Receiver
 SG_ CP_gbdcFailureReason : 49|2@1+ (1,0) [0|3] ""  Receiver
 SG_ CP_gbdcStopChargeReason : 46|3@1+ (1,0) [0|7] ""  Receiver
 SG_ CP_iecComboState : 60|4@1+ (1,0) [0|12] ""  Receiver
 SG_ CP_pilot : 4|3@1+ (1,0) [0|7] ""  Receiver
 SG_ CP_pilotCurrent : 8|8@1+ (0.5,0) [0|127.5] "A"  Receiver
 SG_ CP_proximity : 2|2@1+ (1,0) [0|3] ""  Receiver
 SG_ CP_teslaDcState : 56|4@1+ (1,0) [0|10] ""  Receiver
 SG_ CP_teslaSwcanState : 34|3@1+ (1,0) [0|6] ""  Receiver

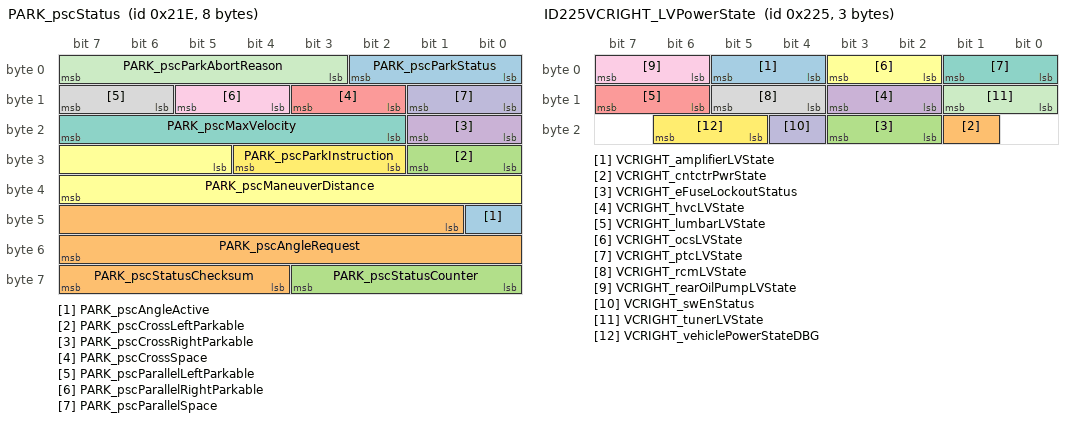
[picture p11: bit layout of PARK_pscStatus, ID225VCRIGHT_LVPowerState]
BO_ 542 PARK_pscStatus: 8 VEH
 SG_ PARK_pscAngleActive: 40|1@1+ (1,0) [0|0] "" X
 SG_ PARK_pscAngleRequest: 41|15@1+ (0.1,-1638.4) [0|0] "deg" X
 SG_ PARK_pscCrossLeftParkable: 24|2@1+ (1,0) [0|0] "" X
 SG_ PARK_pscCrossRightParkable: 16|2@1+ (1,0) [0|0] "" X
 SG_ PARK_pscCrossSpace: 10|2@1+ (1,0) [0|0] "" X
 SG_ PARK_pscManeuverDistance: 29|11@1+ (1,0) [0|0] "cm" X
 SG_ PARK_pscMaxVelocity: 18|6@1+ (0.1,0) [0|0] "kph" X
 SG_ PARK_pscParallelLeftParkable: 14|2@1+ (1,0) [0|0] "" X
 SG_ PARK_pscParallelRightParkable: 12|2@1+ (1,0) [0|0] "" X
 SG_ PARK_pscParallelSpace: 8|2@1+ (1,0) [0|0] "" X
 SG_ PARK_pscParkAbortReason: 3|5@1+ (1,0) [0|0] "" X
 SG_ PARK_pscParkInstruction: 26|3@1+ (1,0) [0|0] "" X
 SG_ PARK_pscParkStatus: 0|3@1+ (1,0) [0|0] "" X
 SG_ PARK_pscStatusChecksum: 60|4@1+ (1,0) [0|0] "" X
 SG_ PARK_pscStatusCounter: 56|4@1+ (1,0) [0|0] "" X

BO_ 545 ID221VCFRONT_LVPowerState: 8 VehicleBus
 SG_ VCFRONT_LVPowerStateIndex M : 0|5@1+ (1,0) [0|1] ""  Receiver
 SG_ VCFRONT_CMPDLVState m1 : 18|2@1+ (1,0) [0|3] ""  Receiver
 SG_ VCFRONT_amplifierLVRequest m0 : 28|2@1+ (1,0) [0|3] ""  Receiver
 SG_ VCFRONT_cpLVRequest m1 : 8|2@1+ (1,0) [0|3] ""  Receiver
 SG_ VCFRONT_das1HighCurrentLVState m0 : 30|2@1+ (1,0) [0|3] ""  Receiver
 SG_ VCFRONT_das2HighCurrentLVState m0 : 32|2@1+ (1,0) [0|3] ""  Receiver
 SG_ VCFRONT_difLVState m0 : 36|2@1+ (1,0) [0|3] ""  Receiver
 SG_ VCFRONT_dirLVRequest m0 : 34|2@1+ (1,0) [0|3] ""  Receiver
 SG_ VCFRONT_epasLVState m1 : 10|2@1+ (1,0) [0|3] ""  Receiver
 SG_ VCFRONT_espLVState m0 : 10|2@1+ (1,0) [0|3] ""  Receiver
 SG_ VCFRONT_hvacCompLVState m0 : 14|2@1+ (1,0) [0|3] ""  Receiver
 SG_ VCFRONT_hvcLVRequest m1 : 12|2@1+ (1,0) [0|3] ""  Receiver
 SG_ VCFRONT_iBoosterLVState m0 : 24|2@1+ (1,0) [0|3] ""  Receiver
 SG_ VCFRONT_ocsLVRequest m0 : 42|2@1+ (1,0) [0|3] ""  Receiver
 SG_ VCFRONT_oilPumpFrontLVState m0 : 38|2@1+ (1,0) [0|3] ""  Receiver
 SG_ VCFRONT_oilPumpRearLVRequest m0 : 40|2@1+ (1,0) [0|3] ""  Receiver
 SG_ VCFRONT_parkLVState m0 : 8|2@1+ (1,0) [0|3] ""  Receiver
 SG_ VCFRONT_pcsLVState m1 : 16|2@1+ (1,0) [0|3] ""  Receiver
 SG_ VCFRONT_ptcLVRequest m0 : 16|2@1+ (1,0) [0|3] ""  Receiver
 SG_ VCFRONT_radcLVState m0 : 12|2@1+ (1,0) [0|3] ""  Receiver
 SG_ VCFRONT_rcmLVRequest m0 : 22|2@1+ (1,0) [0|3] ""  Receiver
 SG_ VCFRONT_sccmLVRequest m0 : 18|2@1+ (1,0) [0|3] ""  Receiver
 SG_ VCFRONT_tasLVState m1 : 14|2@1+ (1,0) [0|3] ""  Receiver
 SG_ VCFRONT_tpmsLVRequest m0 : 20|2@1+ (1,0) [0|3] ""  Receiver
 SG_ VCFRONT_tunerLVRequest m0 : 26|2@1+ (1,0) [0|3] ""  Receiver
 SG_ VCFRONT_uiHiCurrentLVState m0 : 48|2@1+ (1,0) [0|3] ""  Receiver
 SG_ VCFRONT_vcleftHiCurrentLVState m0 : 44|2@1+ (1,0) [0|3] ""  Receiver
 SG_ VCFRONT_vcrightHiCurrentLVState m0 : 46|2@1+ (1,0) [0|3] ""  Receiver

BO_ 548 ID224PCSDCDCstatus: 8 VehicleBus
 SG_ DCDC12VSupportRtyCnt224 : 44|4@1+ (1,0) [0|0] ""  Receiver
 SG_ DCDC12VSupportStatus224 : 2|2@1+ (1,0) [0|0] ""  Receiver
 SG_ DCDCDischargeRtyCnt224 : 48|4@1+ (1,0) [0|0] ""  Receiver
 SG_ DCDCFaulted224 : 15|1@1+ (1,0) [0|0] ""  Receiver
 SG_ DCDCHvBusDischargeStatus224 : 4|2@1+ (1,0) [0|0] ""  Receiver
 SG_ DCDCInitialPrechargeSubState224 : 59|5@1+ (1,0) [0|0] ""  Receiver
 SG_ DCDCoutputCurrent224 : 16|12@1+ (0.1,0) [0|409.5] "A"  Receiver
 SG_ DCDCstate224 : 6|4@1+ (1,0) [0|0] ""  Receiver
 SG_ DCDCoutputCurrentMax224 : 29|12@1+ (0.1,0) [0|409.5] "A"  Receiver
 SG_ DCDCOutputIsLimited224 : 28|1@1+ (1,0) [0|0] ""  Receiver
 SG_ DCDCPrechargeRestartCnt224 : 56|3@1+ (1,0) [0|0] ""  Receiver
 SG_ DCDCPrechargeRtyCnt224 : 41|3@1+ (1,0) [0|0] ""  Receiver
 SG_ DCDCPrechargeStatus224 : 0|2@1+ (1,0) [0|0] ""  Receiver
 SG_ DCDCPwmEnableLine224 : 52|1@1+ (1,0) [0|0] ""  Receiver
 SG_ DCDCSubState224 : 10|5@1+ (1,0) [0|0] ""  Receiver
 SG_ DCDCSupportingFixedLvTarget224 : 53|1@1+ (1,0) [0|0] ""  Receiver
 SG_ PCS_ecuLogUploadRequest224 : 54|2@1+ (1,0) [0|0] ""  Receiver

BO_ 549 ID225VCRIGHT_LVPowerState: 3 VehicleBus
 SG_ VCRIGHT_amplifierLVState : 4|2@1+ (1,0) [0|3] ""  Receiver
 SG_ VCRIGHT_cntctrPwrState : 17|1@1+ (1,0) [0|1] ""  Receiver
 SG_ VCRIGHT_eFuseLockoutStatus : 18|2@1+ (1,0) [0|2] ""  Receiver
 SG_ VCRIGHT_hvcLVState : 10|2@1+ (1,0) [0|3] ""  Receiver
 SG_ VCRIGHT_lumbarLVState : 14|2@1+ (1,0) [0|3] ""  Receiver
 SG_ VCRIGHT_ocsLVState : 2|2@1+ (1,0) [0|3] ""  Receiver
 SG_ VCRIGHT_ptcLVState : 0|2@1+ (1,0) [0|3] ""  Receiver
 SG_ VCRIGHT_rcmLVState : 12|2@1+ (1,0) [0|3] ""  Receiver
 SG_ VCRIGHT_rearOilPumpLVState : 6|2@1+ (1,0) [0|3] ""  Receiver
 SG_ VCRIGHT_swEnStatus : 20|1@1+ (1,0) [0|1] ""  Receiver
 SG_ VCRIGHT_tunerLVState : 8|2@1+ (1,0) [0|3] ""  Receiver
 SG_ VCRIGHT_vehiclePowerStateDBG : 21|2@1+ (1,0) [0|3] ""  Receiver

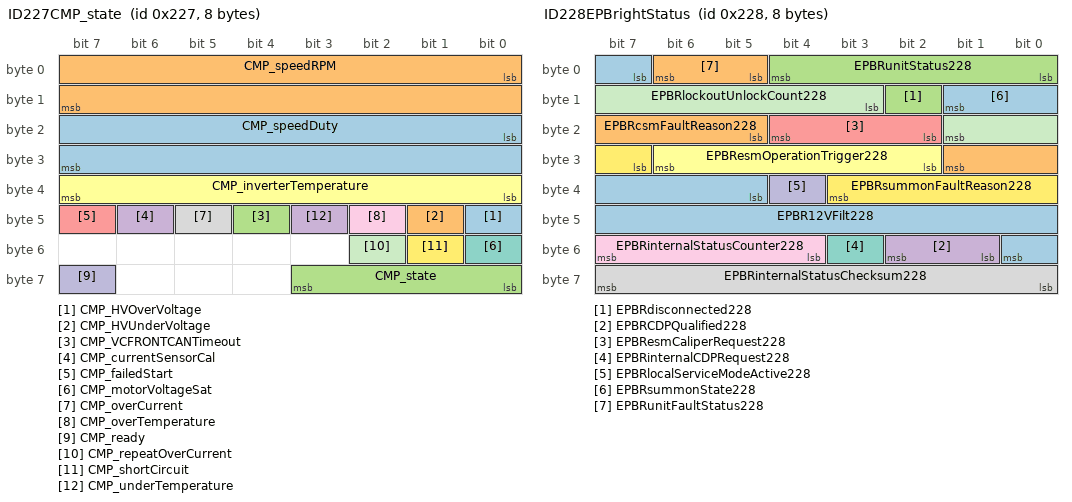
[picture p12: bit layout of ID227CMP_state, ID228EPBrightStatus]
BO_ 551 ID227CMP_state: 8 VehicleBus
 SG_ CMP_HVOverVoltage : 40|1@1+ (1,0) [0|1] ""  Receiver
 SG_ CMP_HVUnderVoltage : 41|1@1+ (1,0) [0|1] ""  Receiver
 SG_ CMP_VCFRONTCANTimeout : 44|1@1+ (1,0) [0|1] ""  Receiver
 SG_ CMP_currentSensorCal : 46|1@1+ (1,0) [0|1] ""  Receiver
 SG_ CMP_failedStart : 47|1@1+ (1,0) [0|1] ""  Receiver
 SG_ CMP_inverterTemperature : 32|8@1+ (1,-40) [-40|200] "C"  Receiver
 SG_ CMP_motorVoltageSat : 48|1@1+ (1,0) [0|1] ""  Receiver
 SG_ CMP_overCurrent : 45|1@1+ (1,0) [0|1] ""  Receiver
 SG_ CMP_overTemperature : 42|1@1+ (1,0) [0|1] ""  Receiver
 SG_ CMP_ready : 63|1@1+ (1,0) [0|1] ""  Receiver
 SG_ CMP_repeatOverCurrent : 50|1@1+ (1,0) [0|1] ""  Receiver
 SG_ CMP_shortCircuit : 49|1@1+ (1,0) [0|1] ""  Receiver
 SG_ CMP_speedDuty : 16|16@1+ (0.1,0) [0|100] "%"  Receiver
 SG_ CMP_speedRPM : 0|16@1+ (1,0) [0|65534] "RPM"  Receiver
 SG_ CMP_state : 56|4@1+ (1,0) [0|15] ""  Receiver
 SG_ CMP_underTemperature : 43|1@1+ (1,0) [0|1] ""  Receiver

BO_ 552 ID228EPBrightStatus: 8 VehicleBus
 SG_ EPBR12VFilt228 : 37|12@1+ (0.00544368,0) [0|0] "V"  Receiver
 SG_ EPBRcsmFaultReason228 : 21|5@1+ (1,0) [0|0] ""  Receiver
 SG_ EPBRdisconnected228 : 10|1@1+ (1,0) [0|0] ""  Receiver
 SG_ EPBRCDPQualified228 : 49|2@1+ (1,0) [0|0] ""  Receiver
 SG_ EPBResmCaliperRequest228 : 18|3@1+ (1,0) [0|0] ""  Receiver
 SG_ EPBResmOperationTrigger228 : 26|5@1+ (1,0) [0|0] ""  Receiver
 SG_ EPBRinternalCDPRequest228 : 51|1@1+ (1,0) [0|0] ""  Receiver
 SG_ EPBRinternalStatusChecksum228 : 56|8@1+ (1,0) [0|0] ""  Receiver
 SG_ EPBRinternalStatusCounter228 : 52|4@1+ (1,0) [0|0] ""  Receiver
 SG_ EPBRlocalServiceModeActive228 : 36|1@1+ (1,0) [0|0] ""  Receiver
 SG_ EPBRlockoutUnlockCount228 : 11|7@1+ (1,0) [0|0] ""  Receiver
 SG_ EPBRsummonFaultReason228 : 31|5@1+ (1,0) [0|0] ""  Receiver
 SG_ EPBRsummonState228 : 7|3@1+ (1,0) [0|0] ""  Receiver
 SG_ EPBRunitFaultStatus228 : 5|2@1+ (1,0) [0|0] ""  Receiver
 SG_ EPBRunitStatus228 : 0|5@1+ (1,0) [0|0] ""  Receiver

BO_ 553 ID229GearLever: 3 VehicleBus
 SG_ GearLeverPosition229 : 12|3@1+ (1,0) [0|7] ""  Receiver
 SG_ GearLeverButton229 : 16|2@1+ (1,0) [0|3] ""  Receiver

BO_ 554 ID22AHVP_pcsControl: 4 VehicleBus
 SG_ HVP_dcLinkVoltageFiltered : 20|11@1- (1,0) [-550|550] "V"  Receiver
 SG_ HVP_dcLinkVoltageRequest : 0|16@1- (0.1,0) [-550|550] "V"  Receiver
 SG_ HVP_pcsChargeHwEnabled : 18|1@1+ (1,0) [0|1] ""  Receiver
 SG_ HVP_pcsControlRequest : 16|2@1+ (1,0) [0|3] ""  Receiver
 SG_ HVP_pcsDcdcHwEnabled : 19|1@1+ (1,0) [0|1] ""  Receiver

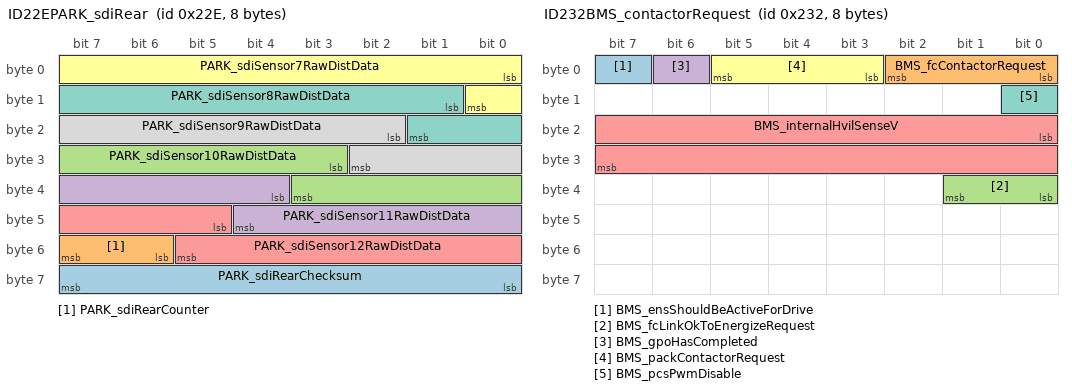
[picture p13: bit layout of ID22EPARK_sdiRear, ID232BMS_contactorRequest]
BO_ 558 ID22EPARK_sdiRear: 8 VehicleBus
 SG_ PARK_sdiRearChecksum : 56|8@1+ (1,0) [0|255] ""  Receiver
 SG_ PARK_sdiRearCounter : 54|2@1+ (1,0) [0|3] ""  Receiver
 SG_ PARK_sdiSensor10RawDistData : 27|9@1+ (1,0) [0|511] "cm"  Receiver
 SG_ PARK_sdiSensor11RawDistData : 36|9@1+ (1,0) [0|511] "cm"  Receiver
 SG_ PARK_sdiSensor12RawDistData : 45|9@1+ (1,0) [0|511] "cm"  Receiver
 SG_ PARK_sdiSensor7RawDistData : 0|9@1+ (1,0) [0|511] "cm"  Receiver
 SG_ PARK_sdiSensor8RawDistData : 9|9@1+ (1,0) [0|511] "cm"  Receiver
 SG_ PARK_sdiSensor9RawDistData : 18|9@1+ (1,0) [0|511] "cm"  Receiver

BO_ 562 ID232BMS_contactorRequest: 8 VehicleBus
 SG_ BMS_ensShouldBeActiveForDrive : 7|1@1+ (1,0) [0|1] ""  Receiver
 SG_ BMS_fcContactorRequest : 0|3@1+ (1,0) [0|5] ""  Receiver
 SG_ BMS_fcLinkOkToEnergizeRequest : 32|2@1+ (1,0) [0|2] ""  Receiver
 SG_ BMS_gpoHasCompleted : 6|1@1+ (1,0) [0|1] ""  Receiver
 SG_ BMS_internalHvilSenseV : 16|16@1+ (0.001,0) [0|65.534] "V"  Receiver
 SG_ BMS_packContactorRequest : 3|3@1+ (1,0) [0|5] ""  Receiver
 SG_ BMS_pcsPwmDisable : 8|1@1+ (1,0) [0|1] ""  Receiver

BO_ 568 ID238UI_driverAssistMapData: 8 ChassisBus
 SG_ UI_acceptBottsDots : 48|1@1+ (1,0) [0|1] ""  Receiver
 SG_ UI_autosteerRestricted : 49|1@1+ (1,0) [0|1] ""  Receiver
 SG_ UI_controlledAccess : 37|1@1+ (1,0) [0|1] ""  Receiver
 SG_ UI_countryCode : 16|10@1+ (1,0) [0|1023] ""  Receiver
 SG_ UI_gpsRoadMatch : 28|1@1+ (1,0) [0|1] ""  Receiver
 SG_ UI_inSuperchargerGeofence : 6|1@1+ (1,0) [0|1] ""  Receiver
 SG_ UI_mapDataChecksum : 56|8@1+ (1,0) [0|255] ""  Receiver
 SG_ UI_mapDataCounter : 52|4@1+ (1,0) [0|15] ""  Receiver
 SG_ UI_mapSpeedLimit : 8|5@1+ (1,0) [0|31] ""  Receiver
 SG_ UI_mapSpeedLimitDependency : 0|3@1+ (1,0) [0|7] ""  Receiver
 SG_ UI_mapSpeedLimitType : 13|3@1+ (1,0) [0|7] ""  Receiver
 SG_ UI_mapSpeedUnits : 7|1@1+ (1,0) [0|1] ""  Receiver
 SG_ UI_navRouteActive : 29|1@1+ (1,0) [0|1] ""  Receiver
 SG_ UI_nextBranchDist : 32|5@1+ (10,0) [0|300] "m"  Receiver
 SG_ UI_nextBranchLeftOffRamp : 38|1@1+ (1,0) [0|1] ""  Receiver
 SG_ UI_nextBranchRightOffRamp : 39|1@1+ (1,0) [0|1] ""  Receiver
 SG_ UI_parallelAutoparkEnabled : 30|1@1+ (1,0) [0|1] ""  Receiver
 SG_ UI_perpendicularAutoparkEnabled : 31|1@1+ (1,0) [0|1] ""  Receiver
 SG_ UI_pmmEnabled : 50|1@1+ (1,0) [0|1] ""  Receiver
 SG_ UI_rejectAutosteer : 46|1@1+ (1,0) [0|1] ""  Receiver
 SG_ UI_rejectHPP : 42|1@1+ (1,0) [0|1] ""  Receiver
 SG_ UI_rejectHandsOn : 47|1@1+ (1,0) [0|1] ""  Receiver
 SG_ UI_rejectLeftFreeSpace : 44|1@1+ (1,0) [0|1] ""  Receiver
 SG_ UI_rejectLeftLane : 40|1@1+ (1,0) [0|1] ""  Receiver
 SG_ UI_rejectNav : 43|1@1+ (1,0) [0|1] ""  Receiver
 SG_ UI_rejectRightFreeSpace : 45|1@1+ (1,0) [0|1] ""  Receiver
 SG_ UI_rejectRightLane : 41|1@1+ (1,0) [0|1] ""  Receiver
 SG_ UI_roadClass : 3|3@1+ (1,0) [0|6] ""  Receiver
 SG_ UI_scaEnabled : 51|1@1+ (1,0) [0|1] ""  Receiver
 SG_ UI_streetCount : 26|2@1+ (1,0) [0|3] ""  Receiver

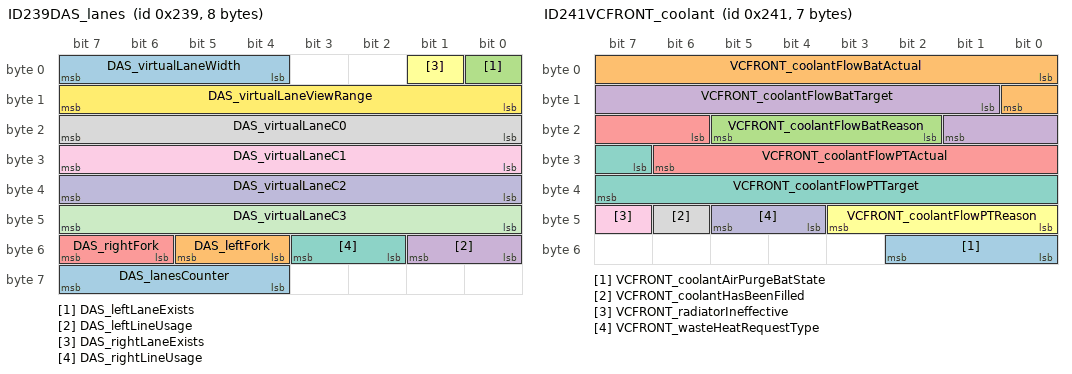
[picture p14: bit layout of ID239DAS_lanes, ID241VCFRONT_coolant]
BO_ 569 ID239DAS_lanes: 8 ChassisBus
 SG_ DAS_lanesCounter : 60|4@1+ (1,0) [0|15] ""  Receiver
 SG_ DAS_leftFork : 52|2@1+ (1,0) [0|3] ""  Receiver
 SG_ DAS_leftLaneExists : 0|1@1+ (1,0) [0|1] ""  Receiver
 SG_ DAS_leftLineUsage : 48|2@1+ (1,0) [0|3] ""  Receiver
 SG_ DAS_rightFork : 54|2@1+ (1,0) [0|3] ""  Receiver
 SG_ DAS_rightLaneExists : 1|1@1+ (1,0) [0|1] ""  Receiver
 SG_ DAS_rightLineUsage : 50|2@1+ (1,0) [0|3] ""  Receiver
 SG_ DAS_virtualLaneC0 : 16|8@1+ (0.035,-3.5) [-3.5|3.5] "m"  Receiver
 SG_ DAS_virtualLaneC1 : 24|8@1+ (0.0016,-0.2) [-0.2|0.2] "rad"  Receiver
 SG_ DAS_virtualLaneC2 : 32|8@1+ (2E-005,-0.0025) [-0.0025|0.0025] "m-1"  Receiver
 SG_ DAS_virtualLaneC3 : 40|8@1+ (2.4E-007,-3E-005) [-3E-005|3E-005] "m-2"  Receiver
 SG_ DAS_virtualLaneViewRange : 8|8@1+ (1,0) [0|160] "m"  Receiver
 SG_ DAS_virtualLaneWidth : 4|4@1+ (0.3125,2) [2|6.6875] "m"  Receiver

BO_ 570 VCSEC_TPMSStatus: 8 GTW
 SG_ VCSEC_TPMSSensorMACAddress0 : 8|48@1+ (1,0) [0|281474976710655] "" ODIN,UI,VITALS
 SG_ VCSEC_TPMSSensorMACAddress1 : 8|48@1+ (1,0) [0|281474976710655] "" ODIN,UI,VITALS
 SG_ VCSEC_TPMSSensorMACAddress2 : 8|48@1+ (1,0) [0|281474976710655] "" ODIN,UI,VITALS
 SG_ VCSEC_TPMSSensorMACAddress3 : 8|48@1+ (1,0) [0|281474976710655] "" ODIN,UI,VITALS
 SG_ VCSEC_TPMSStatusIndex : 0|5@1+ (1,0) [0|19] "" XXX

BO_ 573 ID23DCP_chargeStatus: 4 VehicleBus
 SG_ CP_acChargeCurrentLimit : 8|8@1+ (0.5,0) [0|127.5] "A"  Receiver
 SG_ CP_chargeShutdownRequest : 3|2@1+ (1,0) [0|2] ""  Receiver
 SG_ CP_hvChargeStatus : 0|3@1+ (1,0) [0|6] ""  Receiver
 SG_ CP_internalMaxCurrentLimit : 16|13@1+ (0.146502,0) [0|1200] "A"  Receiver
 SG_ CP_vehicleIsoCheckRequired : 29|1@1+ (1,0) [0|1] ""  Receiver
 SG_ CP_vehiclePrechargeRequired : 30|1@1+ (1,0) [0|1] ""  Receiver

BO_ 577 ID241VCFRONT_coolant: 7 VehicleBus
 SG_ VCFRONT_coolantAirPurgeBatState : 48|3@1+ (1,0) [0|4] ""  Receiver
 SG_ VCFRONT_coolantFlowBatActual : 0|9@1+ (0.1,0) [0|40] "LPM"  Receiver
 SG_ VCFRONT_coolantFlowBatReason : 18|4@1+ (1,0) [0|14] ""  Receiver
 SG_ VCFRONT_coolantFlowBatTarget : 9|9@1+ (0.1,0) [0|40] "LPM"  Receiver
 SG_ VCFRONT_coolantFlowPTActual : 22|9@1+ (0.1,0) [0|40] "LPM"  Receiver
 SG_ VCFRONT_coolantFlowPTReason : 40|4@1+ (1,0) [0|14] ""  Receiver
 SG_ VCFRONT_coolantFlowPTTarget : 31|9@1+ (0.1,0) [0|40] "LPM"  Receiver
 SG_ VCFRONT_coolantHasBeenFilled : 46|1@1+ (1,0) [0|1] ""  Receiver
 SG_ VCFRONT_radiatorIneffective : 47|1@1+ (1,0) [0|1] ""  Receiver
 SG_ VCFRONT_wasteHeatRequestType : 44|2@1+ (1,0) [0|2] ""  Receiver

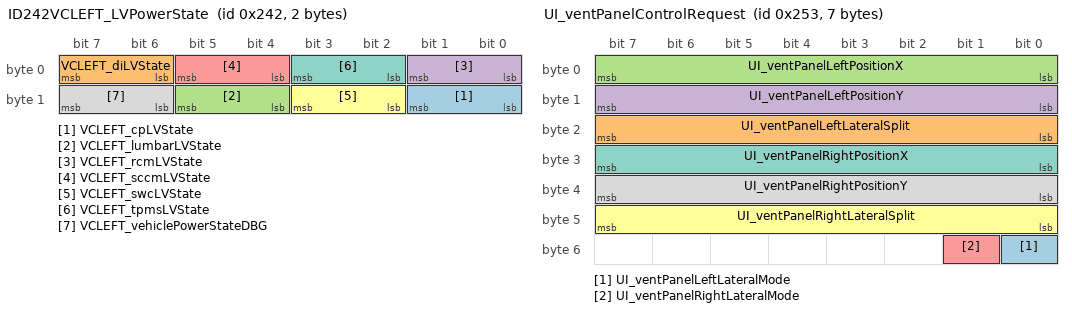
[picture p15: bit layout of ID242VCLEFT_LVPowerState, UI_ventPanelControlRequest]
BO_ 578 ID242VCLEFT_LVPowerState: 2 VehicleBus
 SG_ VCLEFT_cpLVState : 8|2@1+ (1,0) [0|3] ""  Receiver
 SG_ VCLEFT_diLVState : 6|2@1+ (1,0) [0|3] ""  Receiver
 SG_ VCLEFT_lumbarLVState : 12|2@1+ (1,0) [0|3] ""  Receiver
 SG_ VCLEFT_rcmLVState : 0|2@1+ (1,0) [0|3] ""  Receiver
 SG_ VCLEFT_sccmLVState : 4|2@1+ (1,0) [0|3] ""  Receiver
 SG_ VCLEFT_swcLVState : 10|2@1+ (1,0) [0|3] ""  Receiver
 SG_ VCLEFT_tpmsLVState : 2|2@1+ (1,0) [0|3] ""  Receiver
 SG_ VCLEFT_vehiclePowerStateDBG : 14|2@1+ (1,0) [0|3] ""  Receiver

BO_ 579 ID243VCRIGHT_hvacStatus: 8 VehicleBus
 SG_ VCRIGHT_hvacStatusIndex M : 0|2@1+ (1,0) [0|3] ""  Receiver
 SG_ VCRIGHT_hvacACRunning m0 : 50|1@1+ (1,0) [0|1] ""  Receiver
 SG_ VCRIGHT_hvacAirDistributionMode m0 : 41|3@1+ (1,0) [0|7] ""  Receiver
 SG_ VCRIGHT_hvacBlowerSegment m0 : 44|4@1+ (1,0) [0|11] ""  Receiver
 SG_ VCRIGHT_hvacCabinTempEst m0 : 30|11@1+ (0.1,-40) [-40|164] "C"  Receiver
 SG_ VCRIGHT_hvacDuctTargetLeft m1 : 48|8@1+ (0.5,-40) [-40|80] "C"  Receiver
 SG_ VCRIGHT_hvacDuctTargetRight m1 : 56|8@1+ (0.5,-40) [-40|80] "C"  Receiver
 SG_ VCRIGHT_hvacEvapInletTempEstimat m2 : 19|10@1+ (0.13,-40) [-40|90] "C"  Receiver
 SG_ VCRIGHT_hvacMassflowRefrigSystem m1 : 2|8@1+ (1,0) [0|250] "g/s"  Receiver
 SG_ VCRIGHT_hvacModelInitStatus m0 : 60|3@1+ (1,0) [0|5] ""  Receiver
 SG_ VCRIGHT_hvacOverheatProtActive m0 : 63|1@1+ (1,0) [0|1] ""  Receiver
 SG_ VCRIGHT_hvacPowerState m0 : 51|3@1+ (1,0) [0|4] ""  Receiver
 SG_ VCRIGHT_hvacQdotLeft m0 : 2|14@1+ (1,-8191) [-8191|8191] "W"  Receiver
 SG_ VCRIGHT_hvacQdotRight m0 : 16|14@1+ (1,-8191) [-8191|8191] "W"  Receiver
 SG_ VCRIGHT_hvacRecirc m0 : 48|2@1+ (1,0) [0|2] ""  Receiver
 SG_ VCRIGHT_hvacRecircDoorPercent m1 : 10|6@1+ (1.6,0) [0|100] "%"  Receiver
 SG_ VCRIGHT_hvacSecondRowState m0 : 56|3@1+ (1,0) [0|4] ""  Receiver
 SG_ VCRIGHT_hvacSystemNominal m0 : 59|1@1+ (1,0) [0|1] ""  Receiver
 SG_ VCRIGHT_hvacVentStatus m0 : 54|2@1+ (1,0) [0|2] ""  Receiver
 SG_ VCRIGHT_tempDuctLeft m1 : 16|8@1+ (0.5,-22) [-22|105] "C"  Receiver
 SG_ VCRIGHT_tempDuctLeftLower m1 : 24|8@1+ (0.5,-22) [-22|105] "C"  Receiver
 SG_ VCRIGHT_tempDuctLeftUpper m2 : 2|8@1+ (0.5,-22) [-22|105] "C"  Receiver
 SG_ VCRIGHT_tempDuctRight m1 : 32|8@1+ (0.5,-22) [-22|105] "C"  Receiver
 SG_ VCRIGHT_tempDuctRightLower m1 : 40|8@1+ (0.5,-22) [-22|105] "C"  Receiver
 SG_ VCRIGHT_tempDuctRightUpper m2 : 10|8@1+ (0.5,-22) [-22|105] "C"  Receiver

BO_ 580 ID244FastChargeLimits: 8 VehicleBus
 SG_ FCMinVlimit244 : 48|13@1+ (0.073242,0) [0|599.925] "V"  Receiver
 SG_ FCMaxVlimit244 : 32|13@1+ (0.073242,0) [0|599.925] "V"  Receiver
 SG_ FCCurrentLimit244 : 16|13@1+ (0.073242,0) [0|599.925] "A"  Receiver
 SG_ FCPowerLimit244 : 0|13@1+ (0.062256,0) [0|509.939] "kW"  Receiver

BO_ 583 DAS_autopilotDebug: 8 VEH
 SG_ DAS_autopilotAbortReason: 32|8@1+ (1,0) [0|255] "" X
 SG_ DAS_behaviorReport: 16|6@1+ (1,0) [0|43] "" X
 SG_ DAS_cameraContext: 30|2@1+ (1,0) [0|0] "" X
 SG_ DAS_constructionZone: 23|1@1+ (1,0) [0|0] "" X
 SG_ DAS_controlDistance: 24|6@1+ (2,0) [0|0] "m" X
 SG_ DAS_controlTarget: 12|1@1+ (1,0) [0|0] "" X
 SG_ DAS_controllerHealth: 21|2@1+ (1,0) [0|0] "" X
 SG_ DAS_controllerRef: 9|3@1+ (1,0) [0|0] "" X
 SG_ DAS_forkState: 45|5@1+ (1,0) [0|0] "" X
 SG_ DAS_laneChangeState: 50|6@1+ (1,0) [0|0] "" X
 SG_ DAS_lastWatchdogCode: 56|7@1+ (1,0) [0|0] "" X
 SG_ DAS_mapAvailability: 8|1@1+ (1,0) [0|0] "" X
 SG_ DAS_missionPlan: 0|2@1+ (1,0) [0|0] "" X
 SG_ DAS_roadEstimator: 0|2@1+ (1,0) [0|0] "" X
 SG_ DAS_arbiterBehavior : 2|3@1+ (1,0) [0|4] "" X
 SG_ DAS_rqstedBehaviorStatus: 40|5@1+ (1,0) [0|0] "" X

BO_ 585 ID249SCCMLeftStalk: 4 VehicleBus
 SG_ SCCM_highBeamStalkStatus : 12|2@1+ (1,0) [0|3] ""  Receiver
 SG_ SCCM_leftStalkCounter : 8|4@1+ (1,0) [0|15] ""  Receiver
 SG_ SCCM_leftStalkCrc : 0|8@1+ (1,0) [0|255] ""  Receiver
 SG_ SCCM_leftStalkReserved1 : 24|5@1+ (1,0) [0|31] ""  Receiver
 SG_ SCCM_turnIndicatorStalkStatus : 16|4@1+ (1,0) [0|9] ""  Receiver
 SG_ SCCM_washWipeButtonStatus : 14|2@1+ (1,0) [0|3] ""  Receiver

BO_ 586 ID24ADAS_visualDebug: 8 ChassisBus
 SG_ DAS_accSmartSpeedActive : 48|1@1+ (1,0) [0|1] ""  Receiver
 SG_ DAS_accSmartSpeedState : 49|3@1+ (1,0) [0|7] ""  Receiver
 SG_ DAS_autosteerBottsDotsUsage : 12|2@1+ (1,0) [0|3] ""  Receiver
 SG_ DAS_autosteerHPPUsage : 6|2@1+ (1,0) [0|3] ""  Receiver
 SG_ DAS_autosteerHealthAnomalyLevel : 18|3@1+ (1,0) [0|7] ""  Receiver
 SG_ DAS_autosteerHealthState : 21|3@1+ (1,0) [0|5] ""  Receiver
 SG_ DAS_autosteerModelUsage : 10|2@1+ (1,0) [0|3] ""  Receiver
 SG_ DAS_autosteerNavigationUsage : 8|2@1+ (1,0) [0|3] ""  Receiver
 SG_ DAS_autosteerVehiclesUsage : 4|2@1+ (1,0) [0|3] ""  Receiver
 SG_ DAS_behaviorType : 56|2@1+ (1,0) [0|3] ""  Receiver
 SG_ DAS_devAppInterfaceEnabled : 38|1@1+ (1,0) [0|1] ""  Receiver
 SG_ DAS_lastAutosteerAbortReason : 32|6@1+ (1,0) [0|34] ""  Receiver
 SG_ DAS_lastLinePreferenceReason : 24|4@1+ (1,0) [0|15] ""  Receiver
 SG_ DAS_navAvailable : 39|1@1+ (1,0) [0|1] ""  Receiver
 SG_ DAS_navDistance : 40|8@1+ (100,0) [0|25500] "km"  Receiver
 SG_ DAS_offsetSide : 14|2@1+ (1,0) [0|3] ""  Receiver
 SG_ DAS_plannerState : 28|4@1+ (1,0) [0|7] ""  Receiver
 SG_ DAS_rearLeftVehDetectedCurrent : 61|1@1+ (1,0) [0|1] ""  Receiver
 SG_ DAS_rearLeftVehDetectedTrip : 63|1@1+ (1,0) [0|1] ""  Receiver
 SG_ DAS_rearRightVehDetectedTrip : 62|1@1+ (1,0) [0|1] ""  Receiver
 SG_ DAS_rearVehDetectedThisCycle : 60|1@1+ (1,0) [0|1] ""  Receiver
 SG_ DAS_roadSurfaceType : 16|2@1+ (1,0) [0|2] ""  Receiver
 SG_ DAS_ulcInProgress : 52|1@1+ (1,0) [0|1] ""  Receiver
 SG_ DAS_ulcType : 58|2@1+ (1,0) [0|2] ""  Receiver

BO_ 590 PARK_pscVehSlot: 8 CH
 SG_ PARK_pscVehSlotType M: 0|2@1+ (1,0) [0|0] "" X
 SG_ PARK_pscLeftParallelVehX m0: 5|11@1+ (2,-2048) [0|0] "cm" X
 SG_ PARK_pscLeftParallelVehY m0: 16|11@1+ (2,-2048) [0|0] "cm" X
 SG_ PARK_pscLeftParallelPsi m0: 32|13@1+ (0.000976563,0) [0|0] "radians" X
 SG_ PARK_pscLeftParallelSizeX m0: 48|8@1+ (4,0) [0|0] "cm" X
 SG_ PARK_pscLeftParallelSizeY m0: 56|8@1+ (4,0) [0|0] "cm" X
 SG_ PARK_pscLeftCrossVehX m1: 5|11@1+ (2,-2048) [0|0] "cm" X
 SG_ PARK_pscLeftCrossVehY m1: 16|11@1+ (2,-2048) [0|0] "cm" X
 SG_ PARK_pscLeftCrossPsi m1: 32|13@1+ (0.000976563,0) [0|0] "radians" X
 SG_ PARK_pscLeftCrossSizeX m1: 48|8@1+ (4,0) [0|0] "cm" X
 SG_ PARK_pscLeftCrossSizeY m1: 56|8@1+ (4,0) [0|0] "cm" X
 SG_ PARK_pscRightParallelVehX m2: 5|11@1+ (2,-2048) [0|0] "cm" X
 SG_ PARK_pscRightParallelVehY m2: 16|11@1+ (2,-2048) [0|0] "cm" X
 SG_ PARK_pscRightParallelPsi m2: 32|13@1+ (0.000976563,0) [0|0] "radians" X
 SG_ PARK_pscRightParallelSizeX m2: 48|8@1+ (4,0) [0|0] "cm" X
 SG_ PARK_pscRightParallelSizeY m2: 56|8@1+ (4,0) [0|0] "cm" X
 SG_ PARK_pscRightCrossVehX m3: 5|11@1+ (2,-2048) [0|0] "cm" X
 SG_ PARK_pscRightCrossVehY m3: 16|11@1+ (2,-2048) [0|0] "cm" X
 SG_ PARK_pscRightCrossPsi m3: 32|13@1+ (0.000976563,0) [0|0] "radians" X
 SG_ PARK_pscRightCrossSizeX m3: 48|8@1+ (4,0) [0|0] "cm" X
 SG_ PARK_pscRightCrossSizeY m3: 56|8@1+ (4,0) [0|0] "cm" X

BO_ 594 ID252BMS_powerAvailable: 8 VehicleBus
 SG_ BMS_hvacPowerBudget : 50|10@1+ (0.02,0) [0|20.46] "kW"  Receiver
 SG_ BMS_maxDischargePower : 16|16@1+ (0.013,0) [0|655.35] "kW"  Receiver
 SG_ BMS_maxRegenPower : 0|16@1+ (0.01,0) [0|655.35] "kW"  Receiver
 SG_ BMS_maxStationaryHeatPower : 32|10@1+ (0.01,0) [0|10.23] "kW"  Receiver
 SG_ BMS_notEnoughPowerForHeatPump : 42|1@1+ (1,0) [0|1] ""  Receiver
 SG_ BMS_powerLimitsState : 48|1@1+ (1,0) [0|1] ""  Receiver

BO_ 595 UI_ventPanelControlRequest: 7 VEH
 SG_ UI_ventPanelLeftLateralMode: 48|1@1+ (1,0) [0|0] "" X
 SG_ UI_ventPanelLeftLateralSplit: 16|8@1+ (0.5,0) [0|0] "%" X
 SG_ UI_ventPanelLeftPositionX: 0|8@1+ (0.5,0) [0|0] "%" X
 SG_ UI_ventPanelLeftPositionY: 8|8@1+ (0.5,0) [0|0] "%" X
 SG_ UI_ventPanelRightLateralMode: 49|1@1+ (1,0) [0|0] "" X
 SG_ UI_ventPanelRightLateralSplit: 40|8@1+ (0.5,0) [0|0] "%" X
 SG_ UI_ventPanelRightPositionX: 24|8@1+ (0.5,0) [0|0] "%" X
 SG_ UI_ventPanelRightPositionY: 32|8@1+ (0.5,0) [0|0] "%" X

BO_ 598 DIR_status: 7 GTW
 SG_ DIR_state : 12|3@1+ (1,0) [0|4] "" ODIN,SUI,UI
 SG_ DIR_wasteState : 32|2@1+ (1,0) [0|3] "" ODIN

BO_ 599 ID257DIspeed: 8 VehicleBus
 SG_ DI_speedChecksum : 0|8@1+ (1,0) [0|255] ""  Receiver
 SG_ DI_speedCounter : 8|4@1+ (1,0) [0|15] ""  Receiver
 SG_ DI_uiSpeed : 24|9@1+ (1,0) [0|510] ""  Receiver
 SG_ DI_uiSpeedHighSpeed : 34|9@1+ (1,0) [0|510] ""  Receiver
 SG_ DI_uiSpeedUnits : 33|1@1+ (1,0) [0|1] ""  Receiver
 SG_ DI_vehicleSpeed : 12|12@1+ (0.08,-40) [-40|285] "kph"  Receiver

BO_ 600 APB_status: 8 CH
 SG_ APB_statusChecksum: 56|8@1+ (1,0) [0|0] "" X
 SG_ APB_statusCounter: 52|4@1+ (1,0) [0|0] "" X
 SG_ APB_watchdogState: 0|3@1+ (1,0) [0|0] "" X

BO_ 601 APP_status: 8 CH
 SG_ APP_statusChecksum: 56|8@1+ (1,0) [0|0] "" X
 SG_ APP_statusCounter: 52|4@1+ (1,0) [0|0] "" X
 SG_ APP_watchdogState: 0|3@1+ (1,0) [0|0] "" X

BO_ 602 TPMS_bluetoothData: 8 CH
SG_ TPMS_btPressureFL : 0|8@1+ (0.025,0) [0|6.375] "bar" X
SG_ TPMS_btPressureFR : 8|8@1+ (0.025,0) [0|6.375] "bar" X
SG_ TPMS_btPressureRL : 16|8@1+ (0.025,0) [0|6.375] "bar" X
SG_ TPMS_btPressureRR : 24|8@1+ (0.025,0) [0|6.375] "bar" X
SG_ TPMSFLunknown : 32|8@1+ (1,0) [0|0] "" X
SG_ TPMSFRunknown : 40|8@1+ (1,0) [0|0] "" X
SG_ TPMSRLunknown : 48|8@1+ (1,0) [0|0] "" X
SG_ TPMSRRunknown : 56|8@1+ (1,0) [0|0] "" X

BO_ 603 ID25BAPP_environment: 1 ChassisBus
 SG_ APP_environmentRainy : 0|1@1+ (1,0) [0|1] ""  Receiver
 SG_ APP_environmentSnowy : 1|1@1+ (1,0) [0|1] ""  Receiver

BO_ 605 ID25DCP_status: 8 VehicleBus
 SG_ CP_UHF_controlState : 38|4@1+ (1,0) [0|10] ""  Receiver
 SG_ CP_UHF_handleFound : 42|1@1+ (1,0) [0|1] ""  Receiver
 SG_ CP_apsVoltage : 24|8@1+ (0.0715686,0) [0|18.249] "V"  Receiver
 SG_ CP_chargeCablePresent : 3|1@1+ (1,0) [0|1] ""  Receiver
 SG_ CP_chargeCableSecured : 4|1@1+ (1,0) [0|1] ""  Receiver
 SG_ CP_chargeCableState : 14|2@1+ (1,0) [0|2] ""  Receiver
 SG_ CP_chargeDoorOpen : 10|1@1+ (1,0) [0|1] ""  Receiver
 SG_ CP_chargeDoorOpenUI : 51|1@1+ (1,0) [0|1] ""  Receiver
 SG_ CP_coldWeatherMode : 60|1@1+ (1,0) [0|1] ""  Receiver
 SG_ CP_coverClosed : 63|1@1+ (1,0) [0|1] ""  Receiver
 SG_ CP_doorButtonPressed : 32|1@1+ (1,0) [0|1] ""  Receiver
 SG_ CP_doorControlState : 11|3@1+ (1,0) [0|6] ""  Receiver
 SG_ CP_doorOpenRequested : 43|1@1+ (1,0) [0|1] ""  Receiver
 SG_ CP_faultLineSensed : 44|1@1+ (1,0) [0|1] ""  Receiver
 SG_ CP_hvInletExposed : 61|1@1+ (1,0) [0|1] ""  Receiver
 SG_ CP_inductiveDoorState : 45|3@1+ (1,0) [0|7] ""  Receiver
 SG_ CP_inductiveSensorState : 48|3@1+ (1,0) [0|7] ""  Receiver
 SG_ CP_insertEnableLine : 2|1@1+ (1,0) [0|1] ""  Receiver
 SG_ CP_latch2ControlState : 19|3@1+ (1,0) [0|5] ""  Receiver
 SG_ CP_latch2State : 8|2@1+ (1,0) [0|3] ""  Receiver
 SG_ CP_latchControlState : 16|3@1+ (1,0) [0|5] ""  Receiver
 SG_ CP_latchEngaged : 62|1@1+ (1,0) [0|1] ""  Receiver
 SG_ CP_latchState : 5|2@1+ (1,0) [0|3] ""  Receiver
 SG_ CP_ledColor : 33|4@1+ (1,0) [0|10] ""  Receiver
 SG_ CP_numAlertsSet : 53|7@1+ (1,0) [0|127] ""  Receiver
 SG_ CP_permanentPowerRequest : 7|1@1+ (1,0) [0|1] ""  Receiver
 SG_ CP_swcanRelayClosed : 37|1@1+ (1,0) [0|1] ""  Receiver
 SG_ CP_type : 0|2@1+ (1,0) [0|3] ""  Receiver
 SG_ CP_vehicleUnlockRequest : 52|1@1+ (1,0) [0|1] ""  Receiver

BO_ 606 PARK_pscEnvSlot: 8 CH
 SG_ PARK_pscEnvSlotType M: 0|2@1+ (1,0) [0|0] "" X
 SG_ PARK_pscLeftParallelObj1X m0: 3|11@1+ (2,-2048) [0|0] "cm" X
 SG_ PARK_pscLeftParallelObj1Y m0: 14|11@1+ (2,-2048) [0|0] "cm" X
 SG_ PARK_pscLeftParallelObj1Alpha m0: 25|7@1+ (2,-128) [0|0] "deg" X
 SG_ PARK_pscLeftParallelObj2Y m0: 35|11@1+ (2,-2048) [0|0] "cm" X
 SG_ PARK_pscLeftParallelObj2X m0: 46|11@1+ (2,-2048) [0|0] "cm" X
 SG_ PARK_pscLeftParallelObj2Alpha m0: 57|7@1+ (2,-128) [0|0] "deg" X
 SG_ PARK_pscLeftCrossObj1X m1: 3|11@1+ (2,-2048) [0|0] "cm" X
 SG_ PARK_pscLeftCrossObj1Y m1: 14|11@1+ (2,-2048) [0|0] "cm" X
 SG_ PARK_pscLeftCrossObj1Alpha m1: 25|7@1+ (2,-128) [0|0] "deg" X
 SG_ PARK_pscLeftCrossObj2Y m1: 35|11@1+ (2,-2048) [0|0] "cm" X
 SG_ PARK_pscLeftCrossObj2X m1: 46|11@1+ (2,-2048) [0|0] "cm" X
 SG_ PARK_pscLeftCrossObj2Alpha m1: 57|7@1+ (2,-128) [0|0] "deg" X
 SG_ PARK_pscRightParallelObj1X m2: 3|11@1+ (2,-2048) [0|0] "cm" X
 SG_ PARK_pscRightParallelObj1Y m2: 14|11@1+ (2,-2048) [0|0] "cm" X
 SG_ PARK_pscRightParallelObj1Alpha m2: 25|7@1+ (2,-128) [0|0] "deg" X
 SG_ PARK_pscRightParallelObj2Y m2: 35|11@1+ (2,-2048) [0|0] "cm" X
 SG_ PARK_pscRightParallelObj2X m2: 46|11@1+ (2,-2048) [0|0] "cm" X
 SG_ PARK_pscRightParallelObj2Alpha m2: 57|7@1+ (2,-128) [0|0] "deg" X
 SG_ PARK_pscRightCrossObj1X m3: 3|11@1+ (2,-2048) [0|0] "cm" X
 SG_ PARK_pscRightCrossObj1Y m3: 14|11@1+ (2,-2048) [0|0] "cm" X
 SG_ PARK_pscRightCrossObj1Alpha m3: 25|7@1+ (2,-128) [0|0] "deg" X
 SG_ PARK_pscRightCrossObj2Y m3: 35|11@1+ (2,-2048) [0|0] "cm" X
 SG_ PARK_pscRightCrossObj2X m3: 46|11@1+ (2,-2048) [0|0] "cm" X
 SG_ PARK_pscRightCrossObj2Alpha m3: 57|7@1+ (2,-128) [0|0] "deg" X

BO_ 609 ID261_12vBattStatus: 8 VehicleBus
 SG_ VCFRONT_12VBatteryStatusChecksum : 56|8@1+ (1,0) [0|0] ""  Receiver
 SG_ VCFRONT_12VBatteryStatusCounter : 52|4@1+ (1,0) [0|0] ""  Receiver
 SG_ VCFRONT_LVBatteryDisconnected m1 : 50|1@1+ (1,0) [0|0] ""  Receiver
 SG_ VCFRONT_LVBatterySupported m1 : 49|1@1+ (1,0) [0|0] ""  Receiver
 SG_ VCFRONT_voltageFloorReachedCount m0 : 48|4@1+ (1,0) [0|0] ""  Receiver
 SG_ VCFRONT_reverseBatteryFault m1 : 48|1@1+ (1,0) [0|0] ""  Receiver
 SG_ VCFRONT_LVLoadRequest : 47|1@1+ (1,0) [0|0] ""  Receiver
 SG_ VCFRONT_good12VforUpdate : 46|1@1+ (1,0) [0|0] ""  Receiver
 SG_ VCFRONT_firstChargePOR m0 : 45|1@1+ (1,0) [0|0] ""  Receiver
 SG_ VCFRONT_chargeNeeded m1 : 45|1@1+ (1,0) [0|0] ""  Receiver
 SG_ VCFRONT_firstChargeOTA m0 : 44|1@1+ (1,0) [0|0] ""  Receiver
 SG_ VCFRONT_PCSMia m1 : 44|1@1+ (1,0) [0|0] ""  Receiver
 SG_ VCFRONT_silentWakeIBSCurrent m0 : 32|12@1- (0.1,-204.7) [-409.5|2.8421709430404E-014] "mA"  Receiver
 SG_ v12vBattVoltage261 m1 : 32|12@1+ (0.00544368,0) [0|22.2918696] "V"  Receiver
 SG_ VCFRONT_12VBatteryTargetVoltage m2 : 32|10@1+ (0.01,9) [9|19.23] "V"  Receiver
 SG_ v12vBattCurrent261 m0 : 16|16@1- (0.005,0) [-163.84|163.835] "A"  Receiver
 SG_ VCFRONT_IBSCurrent m1 : 16|16@1- (0.005,0) [-163.84|163.835] "A"  Receiver
 SG_ v12vBattTemp261 m2 : 16|16@1- (0.01,0) [-327.68|327.67] "C"  Receiver
 SG_ VCFRONT_shortedCellFaultCounter m0 : 13|3@1+ (1,0) [0|0] ""  Receiver
 SG_ VCFRONT_isVehicleSupported m0 : 12|1@1+ (1,0) [0|0] ""  Receiver
 SG_ VCFRONT_targetCurrent m1 : 8|8@1+ (0.125,0) [0|31.875] "A"  Receiver
 SG_ VCFRONT_voltageDropCounter m0 : 8|4@1+ (1,0) [0|0] ""  Receiver
 SG_ VCFRONT_batterySMState m1 : 4|4@1+ (1,0) [0|0] ""  Receiver
 SG_ VCFRONT_12VOverchargeCounter m0 : 4|4@1+ (1,0) [0|0] ""  Receiver
 SG_ VCFRONT_batterySupportRequest m1 : 3|1@1+ (1,0) [0|0] ""  Receiver
 SG_ v12vBattAH261 m2 : 2|14@1- (0.005,0) [-40.96|40.955] "Ah"  Receiver
 SG_ VCFRONT_voltageProfile m0 : 2|2@1+ (1,0) [0|0] ""  Receiver
 SG_ VCFRONT_IBSFault m1 : 2|1@1+ (1,0) [0|0] ""  Receiver
 SG_ VCFRONT_12VBatteryStatusIndex M : 0|2@1+ (1,0) [0|0] ""  Receiver

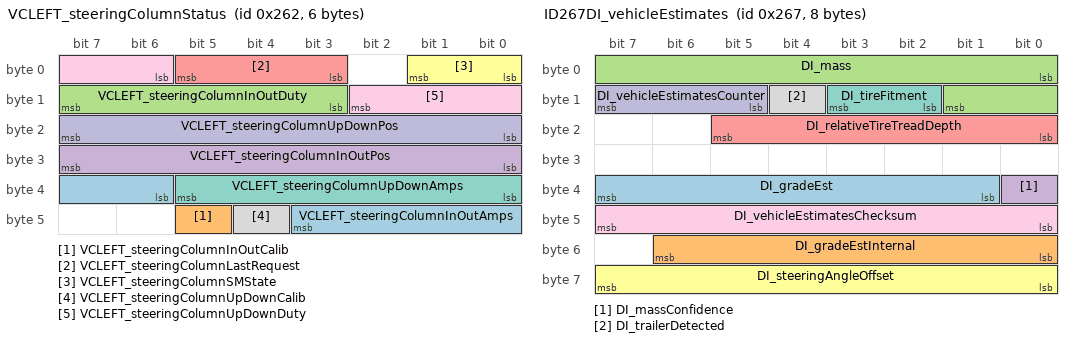
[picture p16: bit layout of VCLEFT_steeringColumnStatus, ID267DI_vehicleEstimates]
BO_ 610 VCLEFT_steeringColumnStatus: 6 VEH
 SG_ VCLEFT_steeringColumnInOutAmps: 38|6@1- (0.63,0) [0|0] "A" X
 SG_ VCLEFT_steeringColumnInOutCalib: 45|1@1+ (1,0) [0|0] "" X
 SG_ VCLEFT_steeringColumnInOutDuty: 11|5@1- (7,0) [0|0] "%" X
 SG_ VCLEFT_steeringColumnInOutPos: 24|8@1- (12,1284) [0|0] "ticks" X
 SG_ VCLEFT_steeringColumnLastRequest: 3|3@1+ (1,0) [0|0] "" X
 SG_ VCLEFT_steeringColumnSMState: 0|2@1+ (1,0) [0|0] "" X
 SG_ VCLEFT_steeringColumnUpDownAmps: 32|6@1- (0.63,0) [0|0] "A" X
 SG_ VCLEFT_steeringColumnUpDownCalib: 44|1@1+ (1,0) [0|0] "" X
 SG_ VCLEFT_steeringColumnUpDownDuty: 6|5@1- (7,0) [0|0] "%" X
 SG_ VCLEFT_steeringColumnUpDownPos: 16|8@1- (12,1284) [0|0] "ticks" X

BO_ 611 VCRIGHT_logging10Hz: 8 VEH
 SG_ VCRIGHT_logging10HzIndex M : 0|3@1+ (1,0) [0|4] ""  Receiver
 SG_ VCRIGHT_evapPulldownBias m3 : 8|8@1+ (0.4,0) [0|100] "%"  Receiver
 SG_ VCRIGHT_evapPulldownBiasActive m3 : 16|1@1+ (1,0) [0|1] ""  Receiver
 SG_ VCRIGHT_hvacCabinHumidityLevel m2 : 55|8@1+ (1,0) [0|100] "%"  Receiver
 SG_ VCRIGHT_hvacEstimateWindshieldRH m2 : 39|8@1+ (1,0) [0|150] "%"  Receiver
 SG_ VCRIGHT_hvacFilterLifeDetectActi m2 : 3|1@1+ (1,0) [0|1] ""  Receiver
 SG_ VCRIGHT_hvacFlashFoggingDetected m2 : 63|1@1+ (1,0) [0|1] ""  Receiver
 SG_ VCRIGHT_hvacFoggingRiskLevel m2 : 47|8@1+ (1,0) [0|100] "%"  Receiver
 SG_ VCRIGHT_hvacIntakeActuatorState m2 : 24|2@1+ (1,0) [0|2] ""  Receiver
 SG_ VCRIGHT_hvacIntakeOperationMode m2 : 10|1@1+ (1,0) [0|1] ""  Receiver
 SG_ VCRIGHT_hvacIntakePosition m1 : 56|8@1+ (0.4,0) [0|100] "%"  Receiver
 SG_ VCRIGHT_hvacIntakeTarget m0 : 56|8@1+ (0.4,0) [0|100] "%"  Receiver
 SG_ VCRIGHT_hvacLHBleedActuatorState m2 : 11|2@1+ (1,0) [0|2] ""  Receiver
 SG_ VCRIGHT_hvacLHBleedOperationMode m2 : 4|1@1+ (1,0) [0|1] ""  Receiver
 SG_ VCRIGHT_hvacLHBleedPosition m1 : 8|8@1+ (0.4,0) [0|100] "%"  Receiver
 SG_ VCRIGHT_hvacLHBleedTarget m0 : 8|8@1+ (0.4,0) [0|100] "%"  Receiver
 SG_ VCRIGHT_hvacLHVaneActuatorState m2 : 16|2@1+ (1,0) [0|2] ""  Receiver
 SG_ VCRIGHT_hvacLHVaneOperationMode m2 : 6|1@1+ (1,0) [0|1] ""  Receiver
 SG_ VCRIGHT_hvacLHVanePosition m1 : 24|8@1+ (0.4,0) [0|100] "%"  Receiver
 SG_ VCRIGHT_hvacLHVaneTarget m0 : 24|8@1+ (0.4,0) [0|100] "%"  Receiver
 SG_ VCRIGHT_hvacLowerModeActState m2 : 22|2@1+ (1,0) [0|2] ""  Receiver
 SG_ VCRIGHT_hvacLowerModeOpMode m2 : 9|1@1+ (1,0) [0|1] ""  Receiver
 SG_ VCRIGHT_hvacLowerModePosition m1 : 48|8@1+ (0.4,0) [0|100] "%"  Receiver
 SG_ VCRIGHT_hvacLowerModeTarget m0 : 48|8@1+ (0.4,0) [0|100] "%"  Receiver
 SG_ VCRIGHT_hvacRHBleedActuatorState m2 : 13|2@1+ (1,0) [0|2] ""  Receiver
 SG_ VCRIGHT_hvacRHBleedOperationMode m2 : 5|1@1+ (1,0) [0|1] ""  Receiver
 SG_ VCRIGHT_hvacRHBleedPosition m1 : 16|8@1+ (0.4,0) [0|100] "%"  Receiver
 SG_ VCRIGHT_hvacRHBleedTarget m0 : 16|8@1+ (0.4,0) [0|100] "%"  Receiver
 SG_ VCRIGHT_hvacRHVaneActuatorState m2 : 18|2@1+ (1,0) [0|2] ""  Receiver
 SG_ VCRIGHT_hvacRHVaneOperationMode m2 : 7|1@1+ (1,0) [0|1] ""  Receiver
 SG_ VCRIGHT_hvacRHVanePosition m1 : 32|8@1+ (0.4,0) [0|100] "%"  Receiver
 SG_ VCRIGHT_hvacRHVaneTarget m0 : 32|8@1+ (0.4,0) [0|100] "%"  Receiver
 SG_ VCRIGHT_hvacUpperModeActState m2 : 20|2@1+ (1,0) [0|2] ""  Receiver
 SG_ VCRIGHT_hvacUpperModeOpMode m2 : 8|1@1+ (1,0) [0|1] ""  Receiver
 SG_ VCRIGHT_hvacUpperModePosition m1 : 40|8@1+ (0.4,0) [0|100] "%"  Receiver
 SG_ VCRIGHT_hvacUpperModeTarget m0 : 40|8@1+ (0.4,0) [0|100] "%"  Receiver
 SG_ VCRIGHT_timeLeftToCabinModelInit m2 : 32|7@1+ (1,0) [0|127] ""  Receiver

BO_ 612 ID264ChargeLineStatus: 8 VehicleBus
 SG_ ChargeLinePower264 : 24|8@1+ (0.1,0) [0|25.5] "kW"  Receiver
 SG_ ChargeLineCurrentLimit264 : 32|10@1+ (0.1,0) [0|102.3] "A"  Receiver
 SG_ ChargeLineVoltage264 : 0|14@1+ (0.0333,0) [0|545.554] "V"  Receiver
 SG_ ChargeLineCurrent264 : 14|9@1+ (0.1,0) [0|51.1] "A"  Receiver

BO_ 614 ID266RearInverterPower: 8 VehicleBus
 SG_ RearHeatPowerMax266 : 24|8@1+ (0.08,0) [0|20] "kW"  Receiver
 SG_ RearPowerLimit266 : 48|9@1+ (1,0) [0|400] "kW"  Receiver
 SG_ RearHeatPower266 : 32|8@1+ (0.08,0) [0|20] "kW"  Receiver
 SG_ RearHeatPowerOptimal266 : 16|8@1+ (0.08,0) [0|20] "kW"  Receiver
 SG_ RearExcessHeatCmd : 40|8@1+ (0.08,0) [0|20] "kW"  Receiver
 SG_ RearPower266 : 0|11@1- (0.5,0) [-500|500] "kW"  Receiver

BO_ 615 ID267DI_vehicleEstimates: 8 VehicleBus
 SG_ DI_gradeEst : 33|7@1- (1,0) [-40|40] "%"  Receiver
 SG_ DI_gradeEstInternal : 48|7@1- (1,0) [-40|40] "%"  Receiver
 SG_ DI_mass : 0|10@1+ (5,1900) [1900|7010] "kg"  Receiver
 SG_ DI_massConfidence : 32|1@1+ (1,0) [0|1] ""  Receiver
 SG_ DI_relativeTireTreadDepth : 16|6@1- (0.2,0) [-6.2|6.2] "mm"  Receiver
 SG_ DI_steeringAngleOffset : 56|8@1- (0.2,0) [-25.6|25.4] "Deg"  Receiver
 SG_ DI_tireFitment : 10|2@1+ (1,0) [0|3] ""  Receiver
 SG_ DI_trailerDetected : 12|1@1+ (1,0) [0|1] ""  Receiver
 SG_ DI_vehicleEstimatesChecksum : 40|8@1+ (1,0) [0|255] ""  Receiver
 SG_ DI_vehicleEstimatesCounter : 13|3@1+ (1,0) [0|7] ""  Receiver

BO_ 616 ID268SystemPower: 5 VehicleBus
 SG_ SystemRegenPowerMax268 : 32|8@1+ (1,-100) [-100|155] "kW"  Receiver
 SG_ SystemHeatPowerMax268 : 0|8@1+ (0.08,0) [0|31875] "kW"  Receiver
 SG_ SystemHeatPower268 : 8|8@1+ (0.08,0) [0|31875] "kW"  Receiver
 SG_ SystemDrivePowerMax268 : 16|9@1+ (1,0) [0|511] "kW"  Receiver
 SG_ DI_primaryUnitSiliconType : 26|1@1+ (1,0) [0|1] ""  Receiver

BO_ 617 ID269LeftRearPower: 8 VehicleBus
 SG_ LeftRearHeatPowerOptimal : 16|8@1+ (0.08,0) [0|20.4] "kW"  Receiver
 SG_ LeftRearPower : 0|11@1- (0.5,0) [-512|511.5] "kW"  Receiver
 SG_ LeftRearPowerMax : 24|8@1+ (0.08,0) [0|20.4] "kW"  Receiver
 SG_ LeftRearPowerLimit : 48|9@1+ (1,0) [0|400] "kW"  Receiver
 SG_ LeftRearHeatPower : 32|8@1+ (0.08,0) [0|20.4] "kW"  Receiver
 SG_ LeftRearExcessHeatCmd : 40|8@1+ (0.08,0) [0|20] "kW"  Receiver

BO_ 626 VCLEFT_epbmDebug: 8 VEH
 SG_ VCLEFT_epbmDebugIndex M: 0|1@1+ (1,0) [0|0] "" X
 SG_ VCLEFT_epbmCaliperState m0: 1|3@1+ (1,0) [0|0] "" X
 SG_ VCLEFT_epbmMotorEnabled m0: 4|1@1+ (1,0) [0|0] "" X
 SG_ VCLEFT_epbMotorCurrent m0: 5|11@1+ (0.01,0) [0|0] "A" X
 SG_ VCLEFT_epbmApplyVoltage m0: 16|11@1+ (0.01,0) [0|0] "A" X
 SG_ VCLEFT_epbmReleaseVoltage m0: 27|11@1+ (0.01,0) [0|0] "A" X
 SG_ VCLEFT_summonFaultReason m0: 38|5@1+ (1,0) [0|0] "" X
 SG_ VCLEFT_epbSummonState m0: 43|3@1+ (1,0) [0|0] "" X
 SG_ VCLEFT_epbmSummonState m0: 46|3@1+ (1,0) [0|0] "" X
 SG_ VCLEFT_epbmUnitStatus m0: 49|5@1+ (1,0) [0|0] "" X
 SG_ VCLEFT_epbUnitStatus m0: 54|5@1+ (1,0) [0|0] "" X
 SG_ VCLEFT_epbmFaultStatus m0: 59|2@1+ (1,0) [0|0] "" X
 SG_ VCLEFT_epbFaultStatus m0: 61|2@1+ (1,0) [0|0] "" X
 SG_ VCLEFT_epbmOpenAllowed m1: 1|1@1+ (1,0) [0|0] "" X
 SG_ VCLEFT_epbmDynamicAllowed m1: 2|1@1+ (1,0) [0|0] "" X
 SG_ VCLEFT_epbmParkAllowed m1: 3|1@1+ (1,0) [0|0] "" X
 SG_ VCLEFT_epbmStartAllowed m1: 4|1@1+ (1,0) [0|0] "" X
 SG_ VCLEFT_epbmServiceAllowed m1: 5|1@1+ (1,0) [0|0] "" X
 SG_ VCLEFT_epbmWinchAllowed m1: 6|1@1+ (1,0) [0|0] "" X
 SG_ VCLEFT_epbmWinchReleaseAllowed m1: 7|1@1+ (1,0) [0|0] "" X
 SG_ VCLEFT_epbmParkingAllowed m1: 8|1@1+ (1,0) [0|0] "" X
 SG_ VCLEFT_epbmDynApplyingAllowed m1: 9|1@1+ (1,0) [0|0] "" X
 SG_ VCLEFT_epbmReleasingAllowed m1: 10|1@1+ (1,0) [0|0] "" X
 SG_ VCLEFT_epbmFaultAllowed m1: 11|1@1+ (1,0) [0|0] "" X
 SG_ VCLEFT_epbmSummonAllowed m1: 12|1@1+ (1,0) [0|0] "" X
 SG_ VCLEFT_epbmSummonParkAllowed m1: 13|1@1+ (1,0) [0|0] "" X
 SG_ VCLEFT_epbmSummonReleaseAllowed m1: 14|1@1+ (1,0) [0|0] "" X
 SG_ VCLEFT_summonInitAllowed m1: 15|1@1+ (1,0) [0|0] "" X
 SG_ VCLEFT_epbmUnknownAllowed m1: 16|1@1+ (1,0) [0|0] "" X
 SG_ VCLEFT_summonIdleAllowed m1: 17|1@1+ (1,0) [0|0] "" X
 SG_ VCLEFT_summonArmedAllowed m1: 18|1@1+ (1,0) [0|0] "" X
 SG_ VCLEFT_summonActiveAllowed m1: 19|1@1+ (1,0) [0|0] "" X
 SG_ VCLEFT_summonCompleteAllowed m1: 20|1@1+ (1,0) [0|0] "" X
 SG_ VCLEFT_summonFaultAllowed m1: 21|1@1+ (1,0) [0|0] "" X
 SG_ VCLEFT_summonUnavailableAllowed m1: 22|1@1+ (1,0) [0|0] "" X
 SG_ VCLEFT_cdpEnumDummy m1: 24|2@1+ (1,0) [0|0] "" X

BO_ 627 ID273UI_vehicleControl: 8 VehicleBus
 SG_ UI_accessoryPowerRequest : 0|1@1+ (1,0) [0|1] ""  Receiver
 SG_ UI_alarmEnabled : 20|1@1+ (1,0) [0|1] ""  Receiver
 SG_ UI_ambientLightingEnabled : 40|1@1+ (1,0) [0|1] ""  Receiver
 SG_ UI_autoFoldMirrorsOn : 52|1@1+ (1,0) [0|1] ""  Receiver
 SG_ UI_autoHighBeamEnabled : 41|1@1+ (1,0) [0|1] ""  Receiver
 SG_ UI_childDoorLockOn : 16|1@1+ (1,0) [0|1] ""  Receiver
 SG_ UI_displayBrightnessLevel : 32|8@1+ (0.5,0) [0|127] "%"  Receiver
 SG_ UI_domeLightSwitch : 59|2@1+ (1,0) [0|2] ""  Receiver
 SG_ UI_driveStateRequest : 62|1@1+ (1,0) [0|1] ""  Receiver
 SG_ UI_frontFogSwitch : 3|1@1+ (1,0) [0|1] ""  Receiver
 SG_ UI_frontLeftSeatHeatReq : 42|2@1+ (1,0) [0|3] ""  Receiver
 SG_ UI_frontRightSeatHeatReq : 44|2@1+ (1,0) [0|3] ""  Receiver
 SG_ UI_frunkRequest : 5|1@1+ (1,0) [0|1] ""  Receiver
 SG_ UI_globalUnlockOn : 15|1@1+ (1,0) [0|1] ""  Receiver
 SG_ UI_honkHorn : 61|1@1+ (1,0) [0|1] ""  Receiver
 SG_ UI_intrusionSensorOn : 21|1@1+ (1,0) [0|1] ""  Receiver
 SG_ UI_lockRequest : 17|3@1+ (1,0) [0|7] ""  Receiver
 SG_ UI_mirrorDipOnReverse : 53|1@1+ (1,0) [0|1] ""  Receiver
 SG_ UI_mirrorFoldRequest : 24|2@1+ (1,0) [0|3] ""  Receiver
 SG_ UI_mirrorHeatRequest : 26|1@1+ (1,0) [0|1] ""  Receiver
 SG_ UI_powerOff : 31|1@1+ (1,0) [0|1] ""  Receiver
 SG_ UI_rearCenterSeatHeatReq : 48|2@1+ (1,0) [0|3] ""  Receiver
 SG_ UI_rearFogSwitch : 23|1@1+ (1,0) [0|1] ""  Receiver
 SG_ UI_rearLeftSeatHeatReq : 46|2@1+ (1,0) [0|3] ""  Receiver
 SG_ UI_rearRightSeatHeatReq : 50|2@1+ (1,0) [0|3] ""  Receiver
 SG_ UI_rearWindowLockout : 63|1@1+ (1,0) [0|1] ""  Receiver
 SG_ UI_remoteClosureRequest : 54|2@1+ (1,0) [0|3] ""  Receiver
 SG_ UI_remoteStartRequest : 27|3@1+ (1,0) [0|4] ""  Receiver
 SG_ UI_seeYouHomeLightingOn : 30|1@1+ (1,0) [0|1] ""  Receiver
 SG_ UI_steeringBacklightEnabled : 8|1@1+ (1,0) [0|1] ""  Receiver
 SG_ UI_steeringButtonMode : 9|3@1+ (1,0) [0|5] ""  Receiver
 SG_ UI_stop12vSupport : 22|1@1+ (1,0) [0|1] ""  Receiver
 SG_ UI_summonActive : 4|1@1+ (1,0) [0|1] ""  Receiver
 SG_ UI_unlockOnPark : 14|1@1+ (1,0) [0|1] ""  Receiver
 SG_ UI_walkAwayLock : 13|1@1+ (1,0) [0|1] ""  Receiver
 SG_ UI_walkUpUnlock : 12|1@1+ (1,0) [0|1] ""  Receiver
 SG_ UI_wiperMode : 6|2@1+ (1,0) [0|3] ""  Receiver
 SG_ UI_wiperRequest : 56|3@1+ (1,0) [0|6] ""  Receiver

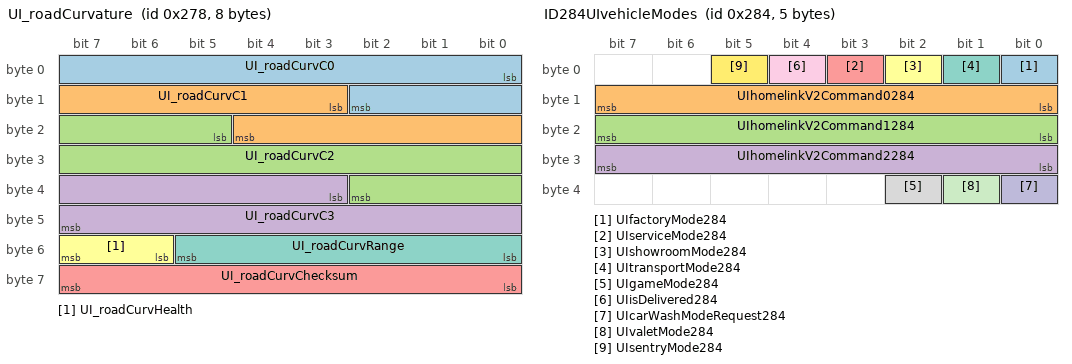
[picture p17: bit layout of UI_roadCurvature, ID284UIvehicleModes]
BO_ 632 UI_roadCurvature: 8 VEH
 SG_ UI_roadCurvC0: 0|11@1- (0.02,0) [0|0] "m" X
 SG_ UI_roadCurvC1: 11|10@1- (0.00075,0) [0|0] "1" X
 SG_ UI_roadCurvC2: 21|14@1- (7.5e-06,0) [0|0] "1/m" X
 SG_ UI_roadCurvC3: 35|13@1- (3e-08,0) [0|0] "1/m2" X
 SG_ UI_roadCurvChecksum: 56|8@1+ (1,0) [0|0] "" X
 SG_ UI_roadCurvHealth: 54|2@1+ (1,0) [0|0] "" X
 SG_ UI_roadCurvRange: 48|6@1+ (4,0) [0|0] "m" X

BO_ 633 DIR_lvStatus: 5 GTW
 SG_ DIR_hvilCmVoltage : 20|8@1+ (0.08,0) [0.0|20.4] "V" ODIN
 SG_ DIR_hvilCurrent : 12|8@1+ (0.1,0) [0.0|25.5] "mA" ODIN
 SG_ DIR_hvilStatus : 28|2@1+ (1,0) [0|3] "" ODIN,SUI,VITALS

BO_ 634 DIF_lvStatus: 5 GTW
 SG_ DIF_hvilCmVoltage : 20|8@1+ (0.08,0) [0.0|20.4] "V" ODIN
 SG_ DIF_hvilCurrent : 12|8@1+ (0.1,0) [0.0|25.5] "mA" ODIN
 SG_ DIF_hvilStatus : 28|2@1+ (1,0) [0|3] "" ODIN,VITALS

BO_ 636 ID27CRightRearPower: 8 VehicleBus
 SG_ RightRearHeatPowerOptimal : 16|8@1+ (0.08,0) [0|20.4] "kW"  Receiver
 SG_ RightRearPower : 0|11@1- (0.5,0) [-512|511.5] "kW"  Receiver
 SG_ RightRearHeatPowerMax : 24|8@1+ (0.08,0) [0|20.4] "kW"  Receiver
 SG_ RightRearPowerLimit : 48|9@1+ (1,0) [0|400] "kW"  Receiver
 SG_ RightRearHeatPower : 32|8@1+ (0.08,0) [0|20.4] "kW"  Receiver
 SG_ RightRearExcessHeatCmd : 40|8@1+ (0.08,0) [0|20] "kW"  Receiver

BO_ 637 ID27DCP_dcChargeLimits: 8 VehicleBus
 SG_ CP_evseInstantDcCurrentLimit : 52|12@1+ (0.146484,0) [0|599.854] "A"  Receiver
 SG_ CP_evseMaxDcCurrentLimit : 0|13@1+ (0.0732422,0) [0|599.927] "A"  Receiver
 SG_ CP_evseMaxDcVoltageLimit : 26|13@1+ (0.0732422,0) [0|599.927] "V"  Receiver
 SG_ CP_evseMinDcCurrentLimit : 13|13@1+ (0.0732422,0) [0|599.927] "A"  Receiver
 SG_ CP_evseMinDcVoltageLimit : 39|13@1+ (0.0732422,0) [0|599.927] "V"  Receiver

BO_ 641 ID281VCFRONT_CMPRequest: 8 VehicleBus
 SG_ VCFRONT_CMPTargetDuty : 0|16@1+ (0.1,0) [0|100] "%"  Receiver
 SG_ VCFRONT_CMPPowerLimit : 16|16@1+ (1,0) [0|65534] "W"  Receiver
 SG_ VCFRONT_CMPReset : 32|8@1+ (1,0) [0|255] ""  Receiver
 SG_ VCFRONT_CMPEnable : 40|1@1+ (1,0) [0|1] ""  Receiver

BO_ 642 ID282VCLEFT_hvacBlowerFeedback: 8 VehicleBus
 SG_ VCLEFT_blowerIndex M : 0|2@1+ (1,0) [0|1] ""  Receiver
 SG_ VCLEFT_hvacBlowerCBCCtrlState m1 : 58|3@1+ (1,0) [0|4] ""  Receiver
 SG_ VCLEFT_hvacBlowerCBCEstState m1 : 54|4@1+ (1,0) [0|14] ""  Receiver
 SG_ VCLEFT_hvacBlowerEnabled m0 : 2|1@1+ (1,0) [0|1] ""  Receiver
 SG_ VCLEFT_hvacBlowerFETTemp m0 : 44|7@1+ (1.5,-40) [-40|149] "C"  Receiver
 SG_ VCLEFT_hvacBlowerFault m0 : 59|1@1+ (1,0) [0|1] ""  Receiver
 SG_ VCLEFT_hvacBlowerIPhase0 m1 : 10|8@1+ (0.2,0) [0|50] "A"  Receiver
 SG_ VCLEFT_hvacBlowerIPhase1 m1 : 18|8@1+ (0.2,0) [0|50] "A"  Receiver
 SG_ VCLEFT_hvacBlowerIPhase2 m1 : 26|8@1+ (0.2,0) [0|50] "A"  Receiver
 SG_ VCLEFT_hvacBlowerITerm m0 : 51|7@1+ (0.05,-1.5) [-1.5|4.5] "Nm"  Receiver
 SG_ VCLEFT_hvacBlowerInitd m0 : 58|1@1+ (1,0) [0|1] ""  Receiver
 SG_ VCLEFT_hvacBlowerLimitFETTemps m0 : 60|1@1+ (1,0) [0|1] ""  Receiver
 SG_ VCLEFT_hvacBlowerOutputDuty m0 : 3|7@1+ (1,0) [0|100] "%"  Receiver
 SG_ VCLEFT_hvacBlowerPowerOn m0 : 61|1@1+ (1,0) [0|1] ""  Receiver
 SG_ VCLEFT_hvacBlowerRPMActual m0 : 20|10@1+ (10,0) [0|10000] "rpm"  Receiver
 SG_ VCLEFT_hvacBlowerRPMTarget m0 : 10|10@1+ (10,0) [0|10000] "rpm"  Receiver
 SG_ VCLEFT_hvacBlowerRs m1 : 2|8@1+ (0.25,0) [0|60] "mOhm"  Receiver
 SG_ VCLEFT_hvacBlowerRsOnlineActive m1 : 61|1@1+ (1,0) [0|1] ""  Receiver
 SG_ VCLEFT_hvacBlowerSpiError m0 : 62|1@1+ (1,0) [0|1] ""  Receiver
 SG_ VCLEFT_hvacBlowerTorque m0 : 34|10@1+ (0.006,-1.5) [-1.5|4.5] "Nm"  Receiver
 SG_ VCLEFT_hvacBlower_IO_CBC_HEAD m1 : 34|4@1+ (1,0) [0|15] ""  Receiver
 SG_ VCLEFT_hvacBlower_IO_CBC_Status m1 : 43|1@1+ (1,0) [0|1] ""  Receiver
 SG_ VCLEFT_hvacBlower_IO_CBC_TAIL m1 : 38|4@1+ (1,0) [0|15] ""  Receiver
 SG_ VCLEFT_hvacBlower_IO_CBC_TAIL_va m1 : 42|1@1+ (1,0) [0|1] ""  Receiver
 SG_ VCLEFT_hvacBlower_IO_CBC_numUart m1 : 46|8@1+ (1,0) [0|255] ""  Receiver

BO_ 644 ID284UIvehicleModes: 5 VehicleBus
 SG_ UIfactoryMode284 : 0|1@1+ (1,0) [0|0] ""  Receiver
 SG_ UIhomelinkV2Command0284 : 8|8@1+ (1,0) [0|0] ""  Receiver
 SG_ UIhomelinkV2Command1284 : 16|8@1+ (1,0) [0|0] ""  Receiver
 SG_ UIhomelinkV2Command2284 : 24|8@1+ (1,0) [0|0] ""  Receiver
 SG_ UIserviceMode284 : 3|1@1+ (1,0) [0|0] ""  Receiver
 SG_ UIshowroomMode284 : 2|1@1+ (1,0) [0|0] ""  Receiver
 SG_ UItransportMode284 : 1|1@1+ (1,0) [0|0] ""  Receiver
 SG_ UIgameMode284 : 34|1@1+ (1,0) [0|0] ""  Receiver
 SG_ UIisDelivered284 : 4|1@1+ (1,0) [0|0] ""  Receiver
 SG_ UIcarWashModeRequest284 : 32|1@1+ (1,0) [0|0] ""  Receiver
 SG_ UIvaletMode284 : 33|1@1+ (1,0) [0|0] ""  Receiver
 SG_ UIsentryMode284 : 5|1@1+ (1,0) [0|0] ""  Receiver

BO_ 645 UI_driverProfileRecall: 8 VEH
 SG_ UI_driverProfileRecallIndex M: 0|3@1+ (1,0) [0|0] "" X
 SG_ UI_driverProfileRecallStop: 3|1@1+ (1,0) [0|0] "" X
 SG_ UI_frontSeatRecallActive m1: 4|1@1+ (1,0) [0|0] "" X
 SG_ UI_frontSeatTrackPos m1: 5|10@1- (4,0) [0|0] "mm" X
 SG_ UI_frontSeatBackPos m1: 16|12@1- (0.1,0) [0|0] "deg" X
 SG_ UI_frontSeatLiftPos m1: 32|10@1- (4,0) [0|0] "mm" X
 SG_ UI_frontSeatTiltPos m1: 48|12@1- (0.1,0) [0|0] "deg" X
 SG_ UI_columnAndLumbarRecallActive m2: 4|1@1+ (1,0) [0|0] "" X
 SG_ UI_steeringColumnUpDownPos m2: 8|8@1- (12,1284) [0|0] "ticks" X
 SG_ UI_lumbarAPressureHpa m2: 16|16@1+ (1,0) [0|0] "" X
 SG_ UI_lumbarBPressureHpa m2: 32|16@1+ (1,0) [0|0] "" X
 SG_ UI_steeringColumnInOutPos m2: 48|8@1- (12,1284) [0|0] "ticks" X
 SG_ UI_mirrorRecallActive m3: 4|1@1+ (1,0) [0|0] "" X
 SG_ UI_leftMirrorTiltXPosition m3: 8|8@1+ (0.02,0) [0|0] "V" X
 SG_ UI_leftMirrorTiltYPosition m3: 16|8@1+ (0.02,0) [0|0] "V" X
 SG_ UI_rightMirrorTiltXPosition m3: 24|8@1+ (0.02,0) [0|0] "V" X
 SG_ UI_rightMirrorTiltYPosition m3: 32|8@1+ (0.02,0) [0|0] "V" X
 SG_ UI_leftMirrorDipXPosition m4: 8|8@1+ (0.02,0) [0|0] "V" X
 SG_ UI_leftMirrorDipYPosition m4: 16|8@1+ (0.02,0) [0|0] "V" X
 SG_ UI_rightMirrorDipXPosition m4: 24|8@1+ (0.02,0) [0|0] "V" X
 SG_ UI_rightMirrorDipYPosition m4: 32|8@1+ (0.02,0) [0|0] "V" X
 SG_ UI_leftBackrestSwitchUp m5: 4|2@1+ (1,0) [0|0] "" X
 SG_ UI_leftBackrestSwitchDown m5: 6|2@1+ (1,0) [0|0] "" X
 SG_ UI_leftLiftSwitchUp m5: 8|2@1+ (1,0) [0|0] "" X
 SG_ UI_leftLiftSwitchDown m5: 10|2@1+ (1,0) [0|0] "" X
 SG_ UI_rightBackrestSwitchUp m5: 12|2@1+ (1,0) [0|0] "" X
 SG_ UI_rightBackrestSwitchDown m5: 14|2@1+ (1,0) [0|0] "" X
 SG_ UI_rightLiftSwitchUp m5: 16|2@1+ (1,0) [0|0] "" X
 SG_ UI_rightLiftSwitchDown m5: 18|2@1+ (1,0) [0|0] "" X

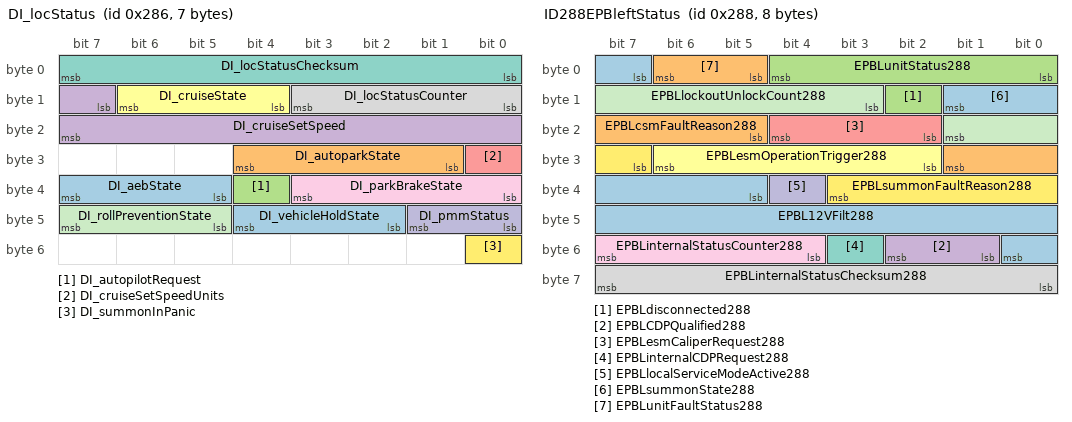
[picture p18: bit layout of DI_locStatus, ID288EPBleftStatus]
BO_ 646 DI_locStatus: 7 VEH
 SG_ DI_aebState: 37|3@1+ (1,0) [0|0] "" X
 SG_ DI_autoparkState: 25|4@1+ (1,0) [0|0] "" X
 SG_ DI_autopilotRequest: 36|1@1+ (1,0) [0|0] "" X
 SG_ DI_cruiseSetSpeed: 15|9@1+ (0.5,0) [0|0] "speed" X
 SG_ DI_cruiseSetSpeedUnits: 24|1@1+ (1,0) [0|0] "" X
 SG_ DI_cruiseState: 12|3@1+ (1,0) [0|0] "" X
 SG_ DI_locStatusChecksum: 0|8@1+ (1,0) [0|0] "" X
 SG_ DI_locStatusCounter: 8|4@1+ (1,0) [0|0] "" X
 SG_ DI_parkBrakeState: 32|4@1+ (1,0) [0|0] "" X
 SG_ DI_pmmStatus: 40|2@1+ (1,0) [0|0] "" X
 SG_ DI_rollPreventionState: 45|3@1+ (1,0) [0|0] "" X
 SG_ DI_summonInPanic: 48|1@1+ (1,0) [0|0] "" X
 SG_ DI_vehicleHoldState: 42|3@1+ (1,0) [0|0] "" X

BO_ 647 ID287PTCcabinHeatSensorStatus: 8 VehicleBus
 SG_ PTC_leftCurrentHV : 48|8@1+ (0.2,0) [0|50] "A"  Receiver
 SG_ PTC_leftTempIGBT : 0|8@1+ (1,-40) [-40|200] "C"  Receiver
 SG_ PTC_rightCurrentHV : 56|8@1+ (0.2,0) [0|50] "A"  Receiver
 SG_ PTC_rightTempIGBT : 16|8@1+ (1,-40) [-40|200] "C"  Receiver
 SG_ PTC_tempOCP : 8|8@1+ (1,-40) [-40|200] "C"  Receiver
 SG_ PTC_tempPCB : 24|8@1+ (1,-40) [-40|200] "C"  Receiver
 SG_ PTC_voltageHV : 32|10@1+ (0.5,0) [0|511.5] "V"  Receiver

BO_ 648 ID288EPBleftStatus: 8 VehicleBus
 SG_ EPBL12VFilt288 : 37|12@1+ (0.00544368,0) [0|0] "V"  Receiver
 SG_ EPBLcsmFaultReason288 : 21|5@1+ (1,0) [0|0] ""  Receiver
 SG_ EPBLdisconnected288 : 10|1@1+ (1,0) [0|0] ""  Receiver
 SG_ EPBLCDPQualified288 : 49|2@1+ (1,0) [0|0] ""  Receiver
 SG_ EPBLesmCaliperRequest288 : 18|3@1+ (1,0) [0|0] ""  Receiver
 SG_ EPBLesmOperationTrigger288 : 26|5@1+ (1,0) [0|0] ""  Receiver
 SG_ EPBLinternalCDPRequest288 : 51|1@1+ (1,0) [0|0] ""  Receiver
 SG_ EPBLinternalStatusChecksum288 : 56|8@1+ (1,0) [0|0] ""  Receiver
 SG_ EPBLinternalStatusCounter288 : 52|4@1+ (1,0) [0|0] ""  Receiver
 SG_ EPBLlocalServiceModeActive288 : 36|1@1+ (1,0) [0|0] ""  Receiver
 SG_ EPBLlockoutUnlockCount288 : 11|7@1+ (1,0) [0|0] ""  Receiver
 SG_ EPBLsummonFaultReason288 : 31|5@1+ (1,0) [0|0] ""  Receiver
 SG_ EPBLsummonState288 : 7|3@1+ (1,0) [0|0] ""  Receiver
 SG_ EPBLunitFaultStatus288 : 5|2@1+ (1,0) [0|0] ""  Receiver
 SG_ EPBLunitStatus288 : 0|5@1+ (1,0) [0|0] ""  Receiver

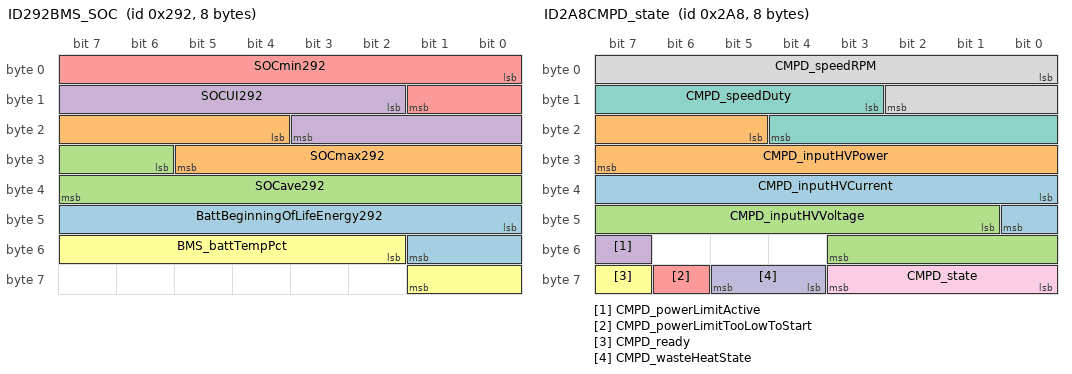
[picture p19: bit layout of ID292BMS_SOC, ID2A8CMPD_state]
BO_ 658 ID292BMS_SOC: 8 VehicleBus
 SG_ BattBeginningOfLifeEnergy292 : 40|10@1+ (0.1,0) [0|102.3] "kWh"  Receiver
 SG_ SOCmax292 : 20|10@1+ (0.1,0) [0|102.3] "%"  Receiver
 SG_ SOCave292 : 30|10@1+ (0.1,0) [0|102.3] "%"  Receiver
 SG_ SOCUI292 : 10|10@1+ (0.1,0) [0|102.3] "%"  Receiver
 SG_ SOCmin292 : 0|10@1+ (0.1,0) [0|102.3] "%"  Receiver
 SG_ BMS_battTempPct : 50|8@1+ (0.4,0) [0|100] "%"  Receiver

BO_ 659 ID293UI_chassisControl: 8 VehicleBus
 SG_ UI_accOvertakeEnable : 16|2@1+ (1,0) [0|3] ""  Receiver
 SG_ UI_aebEnable : 18|2@1+ (1,0) [0|3] ""  Receiver
 SG_ UI_aesEnable : 20|2@1+ (1,0) [0|3] ""  Receiver
 SG_ UI_ahlbEnable : 22|2@1+ (1,0) [0|3] ""  Receiver
 SG_ UI_autoLaneChangeEnable : 24|2@1+ (1,0) [0|3] ""  Receiver
 SG_ UI_autoParkRequest : 28|4@1+ (1,0) [0|15] ""  Receiver
 SG_ UI_bsdEnable : 32|2@1+ (1,0) [0|3] ""  Receiver
 SG_ UI_chassisControlChecksum : 56|8@1+ (1,0) [0|255] ""  Receiver
 SG_ UI_chassisControlCounter : 52|4@1+ (1,0) [0|15] ""  Receiver
 SG_ UI_dasDebugEnable : 14|1@1+ (1,0) [0|1] ""  Receiver
 SG_ UI_distanceUnits : 13|1@1+ (1,0) [0|1] ""  Receiver
 SG_ UI_fcwEnable : 34|2@1+ (1,0) [0|3] ""  Receiver
 SG_ UI_fcwSensitivity : 36|2@1+ (1,0) [0|3] ""  Receiver
 SG_ UI_latControlEnable : 38|2@1+ (1,0) [0|3] ""  Receiver
 SG_ UI_ldwEnable : 40|2@1+ (1,0) [0|3] ""  Receiver
 SG_ UI_narrowGarages : 7|1@1+ (1,0) [0|1] ""  Receiver
 SG_ UI_parkBrakeRequest : 5|2@1+ (1,0) [0|3] ""  Receiver
 SG_ UI_pedalSafetyEnable : 42|2@1+ (1,0) [0|3] ""  Receiver
 SG_ UI_rebootAutopilot : 27|1@1+ (1,0) [0|1] ""  Receiver
 SG_ UI_redLightStopSignEnable : 46|2@1+ (1,0) [0|3] ""  Receiver
 SG_ UI_selfParkTune : 48|4@1+ (1,0) [0|15] ""  Receiver
 SG_ UI_steeringTuneRequest : 0|2@1+ (1,0) [0|2] ""  Receiver
 SG_ UI_tractionControlMode : 2|3@1+ (1,0) [0|6] ""  Receiver
 SG_ UI_trailerMode : 12|1@1+ (1,0) [0|1] ""  Receiver
 SG_ UI_winchModeRequest : 8|2@1+ (1,0) [0|2] ""  Receiver
 SG_ UI_zeroSpeedConfirmed : 10|2@1+ (1,0) [0|3] ""  Receiver

BO_ 664 UI_csaOfframpCurvature: 8 VEH
 SG_ UI_csaOfframpCurvC2: 0|16@1- (1e-06,0) [0|0] "1/m" X
 SG_ UI_csaOfframpCurvC3: 16|16@1- (4e-09,0) [0|0] "1/m2" X
 SG_ UI_csaOfframpCurvChecksum: 56|8@1+ (1,0) [0|0] "" X
 SG_ UI_csaOfframpCurvCounter: 40|8@1+ (1,0) [0|0] "" X
 SG_ UI_csaOfframpCurvRange: 32|8@1+ (2,0) [0|0] "m" X
 SG_ UI_csaOfframpCurvReserved: 49|7@1+ (1,0) [0|0] "" X
 SG_ UI_csaOfframpCurvUsingTspline: 48|1@1+ (1,0) [0|0] "" X

BO_ 669 ID29DCP_dcChargeStatus: 4 VehicleBus
 SG_ CP_evseOutputDcCurrent : 0|15@1- (0.0732467,0) [-1200|1200] "A"  Receiver
 SG_ CP_evseOutputDcCurrentStale : 29|1@1+ (1,0) [0|1] ""  Receiver
 SG_ CP_evseOutputDcVoltage : 16|13@1+ (0.0732422,0) [0|599.927] "V"  Receiver

BO_ 676 PCS_thermalStatus: 8 VEH
 SG_ PCS_ambientTemp: 48|11@1- (0.1,40) [0|0] "C" X
 SG_ PCS_chgPhATemp: 0|11@1- (0.1,40) [0|0] "C" X
 SG_ PCS_chgPhBTemp: 11|11@1- (0.1,40) [0|0] "C" X
 SG_ PCS_chgPhCTemp: 24|11@1- (0.1,40) [0|0] "C" X
 SG_ PCS_dcdcTemp: 35|11@1- (0.1,40) [0|0] "C" X

BO_ 679 UI_csaRoadCurvature: 8 VEH
 SG_ UI_csaRoadCurvC2: 0|16@1- (1e-06,0) [0|0] "1/m" X
 SG_ UI_csaRoadCurvC3: 16|16@1- (4e-09,0) [0|0] "1/m2" X
 SG_ UI_csaRoadCurvChecksum: 56|8@1+ (1,0) [0|0] "" X
 SG_ UI_csaRoadCurvCounter: 40|8@1+ (1,0) [0|0] "" X
 SG_ UI_csaRoadCurvRange: 32|8@1+ (2,0) [0|0] "m" X
 SG_ UI_csaRoadCurvReserved: 49|7@1+ (1,0) [0|0] "" X
 SG_ UI_csaRoadCurvUsingTspline: 48|1@1+ (1,0) [0|0] "" X

BO_ 680 ID2A8CMPD_state: 8 VehicleBus
 SG_ CMPD_inputHVCurrent : 32|9@1+ (0.1,0) [0|50] "A"  Receiver
 SG_ CMPD_inputHVPower : 21|11@1+ (10,0) [0|20000] "W"  Receiver
 SG_ CMPD_inputHVVoltage : 41|11@1+ (0.5,0) [0|1000] "V"  Receiver
 SG_ CMPD_powerLimitActive : 55|1@1+ (1,0) [0|1] ""  Receiver
 SG_ CMPD_powerLimitTooLowToStart : 62|1@1+ (1,0) [0|1] ""  Receiver
 SG_ CMPD_ready : 63|1@1+ (1,0) [0|1] ""  Receiver
 SG_ CMPD_speedDuty : 11|10@1+ (0.1,0) [0|100] "%"  Receiver
 SG_ CMPD_speedRPM : 0|11@1+ (10,0) [0|20000] "RPM"  Receiver
 SG_ CMPD_state : 56|4@1+ (1,0) [0|15] ""  Receiver
 SG_ CMPD_wasteHeatState : 60|2@1+ (1,0) [0|3] ""  Receiver

BO_ 681 EPBL_status: 8 GTW
 SG_ EPBL_systemStatus : 0|4@1+ (1,0) [0|8] "" ODIN,SUI,UI,VITALS

BO_ 690 BMS_chargerRequest: 3 VEH
 SG_ BMS_acChargeEnable: 17|1@1+ (1,0) [0|0] "" X
 SG_ BMS_acChargePowerRequest: 0|16@1+ (0.001,0) [0|0] "kW" X
 SG_ BMS_pcsClearFaultRequest: 16|1@1+ (1,0) [0|0] "" X

BO_ 691 VCRIGHT_logging1Hz: 8 VEH
 SG_ VCRIGHT_logging1HzIndex M : 0|4@1+ (1,0) [0|11] "" X
 SG_ VCRIGHT_LHPanelAirflowBlocked m3 : 54|1@1+ (1,0) [0|1] "" X
 SG_ VCRIGHT_RHPanelAirflowBlocked m3 : 55|1@1+ (1,0) [0|1] "" X
 SG_ VCRIGHT_cabinTempBreathLevel m1 : 56|8@1+ (0.5,-40) [-40|80] "C" X
 SG_ VCRIGHT_cabinTempFanCurrent m9 : 15|6@1- (0.001,0) [-0.01|0.05] "A" X
 SG_ VCRIGHT_cabinTempFanOutput m9 : 14|1@1+ (1,0) [0|1] "" X
 SG_ VCRIGHT_cabinTempGlassRoof m1 : 8|8@1+ (0.5,-40) [-40|80] "C" X
 SG_ VCRIGHT_cabinTempInterior m1 : 24|8@1+ (0.5,-40) [-40|80] "C" X
 SG_ VCRIGHT_cabinTempInteriorL2 m0 : 24|8@1+ (0.5,-40) [-40|80] "C" X
 SG_ VCRIGHT_cabinTempInteriorL3 m9 : 40|8@1+ (0.5,-40) [-40|80] "C" X
 SG_ VCRIGHT_cabinTempInteriorSunny m1 : 32|8@1+ (0.6,-40) [-40|100] "C" X
 SG_ VCRIGHT_cabinTempInteriorSunnyL2 m0 : 40|8@1+ (0.6,-40) [-40|100] "C" X
 SG_ VCRIGHT_cabinTempInteriorSunnyL3 m9 : 48|8@1+ (0.6,-40) [-40|100] "C" X
 SG_ VCRIGHT_cabinTempSideGlassLeft m1 : 40|8@1+ (0.5,-40) [-40|80] "C" X
 SG_ VCRIGHT_cabinTempSideGlassRight m1 : 48|8@1+ (0.5,-40) [-40|80] "C" X
 SG_ VCRIGHT_cabinTempTopPadAir m9 : 56|8@1+ (0.6,-40) [-40|100] "C" X
 SG_ VCRIGHT_cabinTempWindshield m1 : 16|8@1+ (0.5,-40) [-40|80] "C" X
 SG_ VCRIGHT_cloudinessProbability m9 : 33|7@1+ (1,0) [0|100] "%" X
 SG_ VCRIGHT_convectionDeliveredLeft m4 : 24|8@1+ (2,-254) [-254|256] "W/m2" X
 SG_ VCRIGHT_convectionDeliveredRight m4 : 32|8@1+ (2,-254) [-254|256] "W/m2" X
 SG_ VCRIGHT_convectionTargetLeft m4 : 8|8@1+ (2,-254) [-254|256] "W/m2" X
 SG_ VCRIGHT_convectionTargetRight m4 : 16|8@1+ (2,-254) [-254|256] "W/m2" X
 SG_ VCRIGHT_defrostAirflowBlocked m3 : 57|1@1+ (1,0) [0|1] "" X
 SG_ VCRIGHT_evapCondensationRate m10 : 47|9@1- (0.007,0) [-1|1] "g/s" X
 SG_ VCRIGHT_evapDryingRoutineRuntime m10 : 56|5@1+ (2,0) [0|60] "" X
 SG_ VCRIGHT_evapLoadInFresh m5 : 32|8@1+ (35,0) [0|8000] "W" X
 SG_ VCRIGHT_evapLoadInRecirc m5 : 40|8@1+ (35,0) [0|8000] "W" X
 SG_ VCRIGHT_evapWaterMass m10 : 40|7@1+ (6,0) [0|380] "Grams" X
 SG_ VCRIGHT_filterLifeBlowerTorque m9 : 4|10@1+ (0.006,-1.5) [-1.5|4.5] "Nm" X
 SG_ VCRIGHT_floorAirflowBlocked m3 : 56|1@1+ (1,0) [0|1] "" X
 SG_ VCRIGHT_hvacAirFlowModeRow1 m3 : 29|3@1+ (1,0) [0|7] "" X
 SG_ VCRIGHT_hvacAirFlowModeRow2 m3 : 32|3@1+ (1,0) [0|7] "" X
 SG_ VCRIGHT_hvacAirflowReason m3 : 48|4@1+ (1,0) [0|14] "" X
 SG_ VCRIGHT_hvacAutoTransitionReason m3 : 24|5@1+ (1,0) [0|19] "" X
 SG_ VCRIGHT_hvacCabOvrheatProtActive m9 : 30|1@1+ (1,0) [0|1] "" X
 SG_ VCRIGHT_hvacCabOvrheatProtAllowe m9 : 32|1@1+ (1,0) [0|1] "" X
 SG_ VCRIGHT_hvacCabinPurgeActive m9 : 29|1@1+ (1,0) [0|1] "" X
 SG_ VCRIGHT_hvacCabinPurgeAllowed m9 : 31|1@1+ (1,0) [0|1] "" X
 SG_ VCRIGHT_hvacIntakeEndStop m7 : 56|8@1+ (0.02,0) [0|5] "V" X
 SG_ VCRIGHT_hvacIntakeVoltage m6 : 56|8@1+ (0.02,0) [0|5] "V" X
 SG_ VCRIGHT_hvacIntakeZeroStop m8 : 56|8@1+ (0.02,0) [0|5] "V" X
 SG_ VCRIGHT_hvacLHBleedEndStop m7 : 8|8@1+ (0.02,0) [0|5] "V" X
 SG_ VCRIGHT_hvacLHBleedVoltage m6 : 8|8@1+ (0.02,0) [0|5] "V" X
 SG_ VCRIGHT_hvacLHBleedZeroStop m8 : 8|8@1+ (0.02,0) [0|5] "V" X
 SG_ VCRIGHT_hvacLHVaneEndStop m7 : 24|8@1+ (0.02,0) [0|5] "V" X
 SG_ VCRIGHT_hvacLHVaneVoltage m6 : 24|8@1+ (0.02,0) [0|5] "V" X
 SG_ VCRIGHT_hvacLHVaneZeroStop m8 : 24|8@1+ (0.02,0) [0|5] "V" X
 SG_ VCRIGHT_hvacLowerModeEndStop m7 : 48|8@1+ (0.02,0) [0|5] "V" X
 SG_ VCRIGHT_hvacLowerModeVoltage m6 : 48|8@1+ (0.02,0) [0|5] "V" X
 SG_ VCRIGHT_hvacLowerModeZeroStop m8 : 48|8@1+ (0.02,0) [0|5] "V" X
 SG_ VCRIGHT_hvacMassflowTarget m3 : 40|8@1+ (1,0) [0|200] "g/s" X
 SG_ VCRIGHT_hvacQdotFeedforward m5 : 16|16@1+ (1,-32767) [-32767|32767] "W" X
 SG_ VCRIGHT_hvacQdotLimitedLeft m3 : 52|1@1+ (1,0) [0|1] "" X
 SG_ VCRIGHT_hvacQdotLimitedRight m3 : 53|1@1+ (1,0) [0|1] "" X
 SG_ VCRIGHT_hvacRHBleedEndStop m7 : 16|8@1+ (0.02,0) [0|5] "V" X
 SG_ VCRIGHT_hvacRHBleedVoltage m6 : 16|8@1+ (0.02,0) [0|5] "V" X
 SG_ VCRIGHT_hvacRHBleedZeroStop m8 : 16|8@1+ (0.02,0) [0|5] "V" X
 SG_ VCRIGHT_hvacRHVaneEndStop m7 : 32|8@1+ (0.02,0) [0|5] "V" X
 SG_ VCRIGHT_hvacRHVaneVoltage m6 : 32|8@1+ (0.02,0) [0|5] "V" X
 SG_ VCRIGHT_hvacRHVaneZeroStop m8 : 32|8@1+ (0.02,0) [0|5] "V" X
 SG_ VCRIGHT_hvacSetTempActualLeft m3 : 8|8@1+ (0.1,15) [15|28] "C" X
 SG_ VCRIGHT_hvacSetTempActualRight m3 : 16|8@1+ (0.1,15) [15|28] "C" X
 SG_ VCRIGHT_hvacUpperModeEndStop m7 : 40|8@1+ (0.02,0) [0|5] "V" X
 SG_ VCRIGHT_hvacUpperModeVoltage m6 : 40|8@1+ (0.02,0) [0|5] "V" X
 SG_ VCRIGHT_hvacUpperModeZeroStop m8 : 40|8@1+ (0.02,0) [0|5] "V" X
 SG_ VCRIGHT_leftHeatOvertempProtect m10 : 61|1@1+ (1,0) [0|1] "" X
 SG_ VCRIGHT_pcbaTemperature m2 : 4|11@1+ (0.125,-40) [-40|150] "C" X
 SG_ VCRIGHT_ptcHeaterHvacActNotReady m5 : 7|1@1+ (1,0) [0|1] "" X
 SG_ VCRIGHT_ptcHeaterLAirPathBlocked m5 : 10|1@1+ (1,0) [0|1] "" X
 SG_ VCRIGHT_ptcHeaterNoAirflow m5 : 6|1@1+ (1,0) [0|1] "" X
 SG_ VCRIGHT_ptcHeaterNoHighVoltage m5 : 9|1@1+ (1,0) [0|1] "" X
 SG_ VCRIGHT_ptcHeaterNoUiRequest m5 : 8|1@1+ (1,0) [0|1] "" X
 SG_ VCRIGHT_ptcHeaterPwrDemandLeft m2 : 40|8@1+ (20,0) [0|5000] "W" X
 SG_ VCRIGHT_ptcHeaterPwrDemandRight m2 : 48|8@1+ (20,0) [0|5000] "W" X
 SG_ VCRIGHT_ptcHeaterRAirPathBlocked m5 : 11|1@1+ (1,0) [0|1] "" X
 SG_ VCRIGHT_ptcHeaterReqAirpathBlock m5 : 12|1@1+ (1,0) [0|1] "" X
 SG_ VCRIGHT_ptcHeaterTempDuctFault m5 : 5|1@1+ (1,0) [0|1] "" X
 SG_ VCRIGHT_ptcHeaterTempDuctHigh m5 : 4|1@1+ (1,0) [0|1] "" X
 SG_ VCRIGHT_rightHeatOvertempProtect m10 : 62|1@1+ (1,0) [0|1] "" X
 SG_ VCRIGHT_solarLoadLeftOccupant m4 : 48|7@1+ (2,0) [0|254] "W/m2" X
 SG_ VCRIGHT_solarLoadOnVehFiltered m9 : 21|8@1+ (4,0) [0|1020] "W/m2" X
 SG_ VCRIGHT_solarLoadOnVehicle m4 : 56|8@1+ (4,0) [0|1020] "W/m2" X
 SG_ VCRIGHT_solarLoadRightOccupant m4 : 40|7@1+ (2,0) [0|254] "W/m2" X
 SG_ VCRIGHT_tempDuctModeledLeft m10 : 4|9@1+ (0.3,-40) [-40|105] "C" X
 SG_ VCRIGHT_tempDuctModeledRight m10 : 13|9@1+ (0.3,-40) [-40|105] "C" X
 SG_ VCRIGHT_tempHtrSurfaceModeledL m10 : 22|9@1+ (0.3,-40) [-40|105] "C" X
 SG_ VCRIGHT_tempHtrSurfaceModeledR m10 : 31|9@1+ (0.3,-40) [-40|105] "C" X
 SG_ VCRIGHT_tempIncarCabinDeep m0 : 16|8@1+ (0.5,-40) [-40|85] "C" X
 SG_ VCRIGHT_tempIncarCabinMid m0 : 32|8@1+ (0.5,-40) [-40|85] "C" X
 SG_ VCRIGHT_tempIncarCabinProbe m0 : 8|8@1+ (0.5,-40) [-40|85] "C" X
 SG_ VCRIGHT_wattsHeaterLeftTotal m2 : 16|10@1+ (5,0) [0|4000] "W" X
 SG_ VCRIGHT_wattsHeaterRightTotal m2 : 26|10@1+ (5,0) [0|4000] "W" X

VAL_ 12 UI_autopilotTrial 3 "ACTIVE" 0 "NONE" 1 "START" 2 "STOP" ;
VAL_ 12 UI_cellNetworkTechnology 9 "CELL_NETWORK_CDMA" 2 "CELL_NETWORK_EDGE" 1 "CELL_NETWORK_GPRS" 8 "CELL_NETWORK_GSM" 4 "CELL_NETWORK_HSDPA" 6 "CELL_NETWORK_HSPA" 5 "CELL_NETWORK_HSUPA" 7 "CELL_NETWORK_LTE" 0 "CELL_NETWORK_NONE" 15 "CELL_NETWORK_SNA" 3 "CELL_NETWORK_UMTS" 10 "CELL_NETWORK_WCDMA" ;
VAL_ 12 UI_cellSignalBars 5 "FIVE" 4 "FOUR" 1 "ONE" 7 "SNA" 3 "THREE" 2 "TWO" 0 "ZERO" ;
VAL_ 12 UI_factoryReset 3 "CUSTOMER" 1 "DEVELOPER" 2 "DIAGNOSTIC" 0 "NONE_SNA" ;
VAL_ 17 RCM_collisionFront 0 "INACTIVE" 1 "ACTIVE" 3 "SNA";
VAL_ 17 RCM_collisionLeft 0 "INACTIVE" 1 "ACTIVE" 3 "SNA";
VAL_ 17 RCM_collisionRear 0 "INACTIVE" 1 "ACTIVE" 3 "SNA";
VAL_ 17 RCM_collisionRight 0 "INACTIVE" 1 "ACTIVE" 3 "SNA";
VAL_ 17 RCM_collisionRollover 0 "INACTIVE" 1 "ACTIVE" 3 "SNA";
VAL_ 17 RCM_collisionSeverity 0 "PRETENSIONER" 1 "FIRST_STAGE" 2 "SECOND_STAGE" 3 "PEDPRO_EVENT";
VAL_ 60 GTW_infoIndex 0 "DEPRECATED_0" 1 "DEPRECATED_1" 2 "DEPRECATED_2" 3 "DEPRECATED_3" 4 "DEPRECATED_4" 5 "DEPRECATED_5" 6 "DEPRECATED_6" 7 "DEPRECATED_7" 8 "DEPRECATED_8" 9 "DEPRECATED_9" 10 "BUILD_HWID_COMPONENTID" 11 "PCBAID_ASSYID_USAGEID" 13 "APP_CRC" 14 "BOOTLOADER_SVN" 15 "BOOTLOADER_CRC" 16 "SUBCOMPONENT" 17 "APP_GITHASH" 18 "BOOTLOADER_GITHASH" 19 "VERSION_DEPRECATED" 20 "UDS_PROTOCOL_BOOTCRC" 22 "VARIANTCRC" 25 "PACKAGE_PN_1_7" 26 "PACKAGE_PN_8_14" 27 "PACKAGE_PN_15_20" 29 "PACKAGE_SN_1_7" 30 "PACKAGE_SN_8_14" 31 "SUBCOMPONENT_GITHASH" 255 "END";
VAL_ 60 GTW_buildType 0 "UNKNOWN_BUILD" 1 "PLATFORM_BUILD" 2 "LOCAL_BUILD" 3 "TRACEABLE_CI_BUILD" 4 "MFG_BUILD";
VAL_ 60 GTW_platformType 0 "UNKNOWN" 3 "MODEL3" 255 "END";
VAL_ 62 GTW_matrixIndex 0 "AlertMatrix0" 1 "AlertMatrix1";
VAL_ 130 UI_energyAtDestination 32768 "SNA" 32767 "TRIP_TOO_LONG" ;
VAL_ 130 UI_hindsightEnergy 32768 "SNA" 32767 "TRIP_TOO_LONG" ;
VAL_ 130 UI_predictedEnergy 32768 "SNA" 32767 "TRIP_TOO_LONG" ;
VAL_ 257 RCM_pitchRate 16384 "SNA" ;
VAL_ 257 RCM_pitchRateQF 3 "FAULTED" 0 "INIT" 2 "TEMP_INVALID" 1 "VALID" ;
VAL_ 257 RCM_rollRate 16384 "SNA" ;
VAL_ 257 RCM_rollRateQF 3 "FAULTED" 0 "INIT" 2 "TEMP_INVALID" 1 "VALID" ;
VAL_ 257 RCM_yawRate 32768 "SNA" ;
VAL_ 257 RCM_yawRateQF 0 "FAULTED" 1 "NOT_FAULTED" ;
VAL_ 258 VCLEFT_frontLatchStatus 5 "LATCH_AJAR" 2 "LATCH_CLOSED" 3 "LATCH_CLOSING" 7 "LATCH_DEFAULT" 8 "LATCH_FAULT" 1 "LATCH_OPENED" 4 "LATCH_OPENING" 0 "LATCH_SNA" 6 "LATCH_TIMEOUT" ;
VAL_ 258 VCLEFT_mirrorFoldState 1 "MIRROR_FOLD_STATE_FOLDED" 3 "MIRROR_FOLD_STATE_FOLDING" 2 "MIRROR_FOLD_STATE_UNFOLDED" 4 "MIRROR_FOLD_STATE_UNFOLDING" 0 "MIRROR_FOLD_STATE_UNKNOWN" ;
VAL_ 258 VCLEFT_mirrorHeatState 4 "HEATER_STATE_FAULT" 2 "HEATER_STATE_OFF" 3 "HEATER_STATE_OFF_UNAVAILABLE" 1 "HEATER_STATE_ON" 0 "HEATER_STATE_SNA" ;
VAL_ 258 VCLEFT_mirrorRecallState 0 "MIRROR_RECALL_STATE_INIT" 1 "MIRROR_RECALL_STATE_RECALLING_AXIS_1" 2 "MIRROR_RECALL_STATE_RECALLING_AXIS_2" 3 "MIRROR_RECALL_STATE_RECALLING_COMPLETE" 4 "MIRROR_RECALL_STATE_RECALLING_FAILED" 5 "MIRROR_RECALL_STATE_RECALLING_STOPPED" ;
VAL_ 258 VCLEFT_mirrorState 3 "MIRROR_STATE_FOLD_UNFOLD" 0 "MIRROR_STATE_IDLE" 4 "MIRROR_STATE_RECALL" 1 "MIRROR_STATE_TILT_X" 2 "MIRROR_STATE_TILT_Y" ;
VAL_ 258 VCLEFT_rearLatchStatus 5 "LATCH_AJAR" 2 "LATCH_CLOSED" 3 "LATCH_CLOSING" 7 "LATCH_DEFAULT" 8 "LATCH_FAULT" 1 "LATCH_OPENED" 4 "LATCH_OPENING" 0 "LATCH_SNA" 6 "LATCH_TIMEOUT" ;
VAL_ 259 VCRIGHT_frontLatchStatus 5 "LATCH_AJAR" 2 "LATCH_CLOSED" 3 "LATCH_CLOSING" 7 "LATCH_DEFAULT" 8 "LATCH_FAULT" 1 "LATCH_OPENED" 4 "LATCH_OPENING" 0 "LATCH_SNA" 6 "LATCH_TIMEOUT" ;
VAL_ 259 VCRIGHT_mirrorFoldState 1 "MIRROR_FOLD_STATE_FOLDED" 3 "MIRROR_FOLD_STATE_FOLDING" 2 "MIRROR_FOLD_STATE_UNFOLDED" 4 "MIRROR_FOLD_STATE_UNFOLDING" 0 "MIRROR_FOLD_STATE_UNKNOWN" ;
VAL_ 259 VCRIGHT_mirrorRecallState 0 "MIRROR_RECALL_STATE_INIT" 1 "MIRROR_RECALL_STATE_RECALLING_AXIS_1" 2 "MIRROR_RECALL_STATE_RECALLING_AXIS_2" 3 "MIRROR_RECALL_STATE_RECALLING_COMPLETE" 4 "MIRROR_RECALL_STATE_RECALLING_FAILED" 5 "MIRROR_RECALL_STATE_RECALLING_STOPPED" ;
VAL_ 259 VCRIGHT_mirrorState 3 "MIRROR_STATE_FOLD_UNFOLD" 0 "MIRROR_STATE_IDLE" 4 "MIRROR_STATE_RECALL" 1 "MIRROR_STATE_TILT_X" 2 "MIRROR_STATE_TILT_Y" ;
VAL_ 259 VCRIGHT_rearLatchStatus 5 "LATCH_AJAR" 2 "LATCH_CLOSED" 3 "LATCH_CLOSING" 7 "LATCH_DEFAULT" 8 "LATCH_FAULT" 1 "LATCH_OPENED" 4 "LATCH_OPENING" 0 "LATCH_SNA" 6 "LATCH_TIMEOUT" ;
VAL_ 259 VCRIGHT_trunkLatchStatus 5 "LATCH_AJAR" 2 "LATCH_CLOSED" 3 "LATCH_CLOSING" 7 "LATCH_DEFAULT" 8 "LATCH_FAULT" 1 "LATCH_OPENED" 4 "LATCH_OPENING" 0 "LATCH_SNA" 6 "LATCH_TIMEOUT" ;
VAL_ 264 DIR_axleSpeed 32768 "SNA" ;
VAL_ 264 DIR_slavePedalPos 255 "SNA" ;
VAL_ 264 DIR_torqueActual 4096 "SNA" ;
VAL_ 264 DIR_torqueCommand 4096 "SNA" ;
VAL_ 273 RCM_lateralAccel 32768 "SNA" ;
VAL_ 273 RCM_lateralAccelQF 0 "FAULTED" 1 "NOT_FAULTED" ;
VAL_ 273 RCM_longitudinalAccel 32768 "SNA" ;
VAL_ 273 RCM_longitudinalAccelQF 0 "FAULTED" 1 "NOT_FAULTED" ;
VAL_ 273 RCM_verticalAccel 32768 "SNA" ;
VAL_ 273 RCM_verticalAccelQF 0 "FAULTED" 1 "NOT_FAULTED" ;
VAL_ 274 GTW_1V1_VEH 4095 "SNA";
VAL_ 274 GTW_1V5_VEH 4095 "SNA";
VAL_ 274 GTW_3V3_VEH 4095 "SNA";
VAL_ 274 GTW_3V3_SW 4095 "SNA";
VAL_ 274 GTW_5V0_SW 4095 "SNA";
VAL_ 275 GTW_bmpState 2 "BMP_STATE_ASLEEP" 3 "BMP_STATE_MIA" 0 "BMP_STATE_OFF" 1 "BMP_STATE_ON" 5 "BMP_STATE_POWER_CYCLE" 4 "BMP_STATE_RESET" 255 "DUMMY" ;
VAL_ 276 GTW_1V2_CSI 4095 "SNA";
VAL_ 276 GTW_1V8_VID 4095 "SNA";
VAL_ 276 GTW_1V8_VIO 4095 "SNA";
VAL_ 276 GTW_3V3_BMP 4095 "SNA";
VAL_ 276 GTW_GSM_BRD_REV 4095 "SNA";
VAL_ 280 DI_accelPedalPos 255 "SNA" ;
VAL_ 280 DI_brakePedalState 2 "INVALID" 0 "OFF" 1 "ON" ;
VAL_ 280 DI_driveBlocked 1 "DRIVE_BLOCKED_FRUNK" 0 "DRIVE_BLOCKED_NONE" 2 "DRIVE_BLOCKED_PROX" ;
VAL_ 280 DI_epbRequest 0 "DI_EPBREQUEST_NO_REQUEST" 1 "DI_EPBREQUEST_PARK" 2 "DI_EPBREQUEST_UNPARK" ;
VAL_ 280 DI_gear 4 "DI_GEAR_D" 0 "DI_GEAR_INVALID" 3 "DI_GEAR_N" 1 "DI_GEAR_P" 2 "DI_GEAR_R" 7 "DI_GEAR_SNA" ;
VAL_ 280 DI_immobilizerState 2 "DI_IMM_STATE_AUTHENTICATING" 3 "DI_IMM_STATE_DISARMED" 6 "DI_IMM_STATE_FAULT" 4 "DI_IMM_STATE_IDLE" 0 "DI_IMM_STATE_INIT_SNA" 1 "DI_IMM_STATE_REQUEST" 5 "DI_IMM_STATE_RESET" ;
VAL_ 280 DI_keepDrivePowerStateRequest 1 "KEEP_ALIVE" 0 "NO_REQUEST" ;
VAL_ 280 DI_systemState 4 "DI_SYS_ABORT" 5 "DI_SYS_ENABLE" 3 "DI_SYS_FAULT" 1 "DI_SYS_IDLE" 2 "DI_SYS_STANDBY" 0 "DI_SYS_UNAVAILABLE" ;
VAL_ 280 DI_trackModeState 1 "TRACK_MODE_AVAILABLE" 2 "TRACK_MODE_ON" 0 "TRACK_MODE_UNAVAILABLE" ;
VAL_ 280 DI_tractionControlMode 6 "Offroad Assist" 5 "Dyno Mode" 4 "Rolls Mode" 3 "Dev2" 2 "Dev1" 1 "Slip Start" 0 "Standard" ;
VAL_ 281 VCSEC_windowRequestPercent 127 "SNA" ;
VAL_ 281 VCSEC_windowRequestType 3 "WINDOW_REQUEST_GOTO_CLOSED" 2 "WINDOW_REQUEST_GOTO_CRACKED" 1 "WINDOW_REQUEST_GOTO_PERCENT" 0 "WINDOW_REQUEST_IDLE" ;
VAL_ 289 RCM_crashAlgoWakeup 0 "INACTIVE" 1 "ACTIVE" 3 "SNA";
VAL_ 289 RCM_nearDeployFront 0 "INACTIVE" 1 "ACTIVE" 3 "SNA";
VAL_ 289 RCM_nearDeployLeft 0 "INACTIVE" 1 "ACTIVE" 3 "SNA";
VAL_ 289 RCM_nearDeployRear 0 "INACTIVE" 1 "ACTIVE" 3 "SNA";
VAL_ 289 RCM_nearDeployRight 0 "INACTIVE" 1 "ACTIVE" 3 "SNA";
VAL_ 289 RCM_nearDeployRollover 0 "INACTIVE" 1 "ACTIVE" 3 "SNA";
VAL_ 290 VCLEFT_frontDoorState 1 "DOOR_STATE_CLOSED" 4 "DOOR_STATE_OPEN_OR_AJAR" 3 "DOOR_STATE_RELEASING_LATCH" 0 "DOOR_STATE_UNKNOWN" 2 "DOOR_STATE_WAIT_FOR_SHORT_DROP" ;
VAL_ 290 VCLEFT_frontHandleDebounceStatus 3 "EXTERIOR_HANDLE_STATUS_ACTIVE" 4 "EXTERIOR_HANDLE_STATUS_DISCONNECTED" 5 "EXTERIOR_HANDLE_STATUS_FAULT" 1 "EXTERIOR_HANDLE_STATUS_INDETERMINATE" 2 "EXTERIOR_HANDLE_STATUS_NOT_ACTIVE" 0 "EXTERIOR_HANDLE_STATUS_SNA" ;
VAL_ 290 VCLEFT_frontHandleRawStatus 3 "EXTERIOR_HANDLE_STATUS_ACTIVE" 4 "EXTERIOR_HANDLE_STATUS_DISCONNECTED" 5 "EXTERIOR_HANDLE_STATUS_FAULT" 1 "EXTERIOR_HANDLE_STATUS_INDETERMINATE" 2 "EXTERIOR_HANDLE_STATUS_NOT_ACTIVE" 0 "EXTERIOR_HANDLE_STATUS_SNA" ;
VAL_ 290 VCLEFT_rearDoorState 1 "DOOR_STATE_CLOSED" 4 "DOOR_STATE_OPEN_OR_AJAR" 3 "DOOR_STATE_RELEASING_LATCH" 0 "DOOR_STATE_UNKNOWN" 2 "DOOR_STATE_WAIT_FOR_SHORT_DROP" ;
VAL_ 290 VCLEFT_rearHandleDebounceStatus 3 "EXTERIOR_HANDLE_STATUS_ACTIVE" 4 "EXTERIOR_HANDLE_STATUS_DISCONNECTED" 5 "EXTERIOR_HANDLE_STATUS_FAULT" 1 "EXTERIOR_HANDLE_STATUS_INDETERMINATE" 2 "EXTERIOR_HANDLE_STATUS_NOT_ACTIVE" 0 "EXTERIOR_HANDLE_STATUS_SNA" ;
VAL_ 290 VCLEFT_rearHandleRawStatus 3 "EXTERIOR_HANDLE_STATUS_ACTIVE" 4 "EXTERIOR_HANDLE_STATUS_DISCONNECTED" 5 "EXTERIOR_HANDLE_STATUS_FAULT" 1 "EXTERIOR_HANDLE_STATUS_INDETERMINATE" 2 "EXTERIOR_HANDLE_STATUS_NOT_ACTIVE" 0 "EXTERIOR_HANDLE_STATUS_SNA" ;
VAL_ 294 DIR_vBatQF 0 "NOT_QUALIFIED" 1 "QUALIFIED" ;
VAL_ 317 CP_chargeShutdownRequest 2 "EMERGENCY_SHUTDOWN_REQUESTED" 1 "GRACEFUL_SHUTDOWN_REQUESTED" 0 "NO_SHUTDOWN_REQUESTED" ;
VAL_ 317 CP_evseChargeType 2 "AC_CHARGER_PRESENT" 1 "DC_CHARGER_PRESENT" 0 "NO_CHARGER_PRESENT" ;
VAL_ 317 CP_hvChargeStatus 1 "CP_CHARGE_CONNECTED" 5 "CP_CHARGE_ENABLED" 6 "CP_CHARGE_FAULTED" 0 "CP_CHARGE_INACTIVE" 2 "CP_CHARGE_STANDBY" 4 "CP_EVSE_TEST_PASSED" 3 "CP_EXT_EVSE_TEST_ACTIVE" ;
VAL_ 322 VCLEFT_liftgateStatusIndex 0 "LIFTGATE_STATUS_INDEX_0" 1 "LIFTGATE_STATUS_INDEX_1" 2 "LIFTGATE_STATUS_INDEX_INVALID" ;
VAL_ 322 VCLEFT_liftgateLatchRequest 1 "LATCH_REQUEST_CINCH" 3 "LATCH_REQUEST_FORCE_RELEASE" 0 "LATCH_REQUEST_NONE" 2 "LATCH_REQUEST_RELEASE" 4 "LATCH_REQUEST_RESET" ;
VAL_ 322 VCLEFT_liftgateMvmntNotAllowedCo 4 "PLG_MVMT_NOT_ALLOWED_EXTERIOR_PRESS_AT_MAX_OPEN" 5 "PLG_MVMT_NOT_ALLOWED_LOCKED" 1 "PLG_MVMT_NOT_ALLOWED_LOW_12V" 0 "PLG_MVMT_NOT_ALLOWED_NONE" 3 "PLG_MVMT_NOT_ALLOWED_UNCALIBRATED" 2 "PLG_MVMT_NOT_ALLOWED_VEHICLE_AT_SPEED" ;
VAL_ 322 VCLEFT_liftgatePhysicalChimeRequ 0 "LIFTGATE_CHIME_REQUEST_NONE" 4 "LIFTGATE_CHIME_REQUEST_ONE_LONG" 1 "LIFTGATE_CHIME_REQUEST_ONE_SHORT" 3 "LIFTGATE_CHIME_REQUEST_THREE_SHORT" 2 "LIFTGATE_CHIME_REQUEST_TWO_SHORT" ;
VAL_ 322 VCLEFT_liftgateRequestSource 5 "PLG_REQUEST_SOURCE_CLOSE_ALL" 2 "PLG_REQUEST_SOURCE_EXTERIOR" 4 "PLG_REQUEST_SOURCE_KEY_TRUNK_BUTTON" 6 "PLG_REQUEST_SOURCE_MCU_CLOSE" 1 "PLG_REQUEST_SOURCE_MCU_SWITCH" 0 "PLG_REQUEST_SOURCE_NONE" 3 "PLG_REQUEST_SOURCE_SHUTFACE" 7 "PLG_REQUEST_SOURCE_UDS" ;
VAL_ 322 VCLEFT_liftgateState 2 "PLG_STATE_BACKOFF" 5 "PLG_STATE_CLOSED" 4 "PLG_STATE_CLOSING" 11 "PLG_STATE_END_OF_TRAVEL" 0 "PLG_STATE_INIT" 7 "PLG_STATE_LATCH_CLOSING" 12 "PLG_STATE_LATCH_ENTRY" 10 "PLG_STATE_LATCH_EXIT" 6 "PLG_STATE_LATCH_OPENING" 8 "PLG_STATE_NOT_INSTALLED" 1 "PLG_STATE_OFF" 3 "PLG_STATE_OPENING" 9 "PLG_STATE_UNKNOWN" ;
VAL_ 322 VCLEFT_liftgateStoppingCondition 11 "PLG_STOPPING_CONDITION_COUNT" 10 "PLG_STOPPING_CONDITION_LATCH_FAULT" 3 "PLG_STOPPING_CONDITION_LOW_12V" 0 "PLG_STOPPING_CONDITION_NONE" 6 "PLG_STOPPING_CONDITION_OBSTACLE_CURRENT" 2 "PLG_STOPPING_CONDITION_OBSTACLE_STALL" 7 "PLG_STOPPING_CONDITION_OBSTACLE_TRAJ_POS" 8 "PLG_STOPPING_CONDITION_OBSTACLE_TRAJ_VEL" 1 "PLG_STOPPING_CONDITION_PINCH" 4 "PLG_STOPPING_CONDITION_STATE_TIMEOUT" 9 "PLG_STOPPING_CONDITION_UNCALIBRATED" 5 "PLG_STOPPING_CONDITION_VEHICLE_AT_SPEED" ;
VAL_ 322 VCLEFT_liftgateUIChimeRequest 0 "LIFTGATE_CHIME_REQUEST_NONE" 4 "LIFTGATE_CHIME_REQUEST_ONE_LONG" 1 "LIFTGATE_CHIME_REQUEST_ONE_SHORT" 3 "LIFTGATE_CHIME_REQUEST_THREE_SHORT" 2 "LIFTGATE_CHIME_REQUEST_TWO_SHORT" ;
VAL_ 325 ESP_absBrakeEvent2 2 "ABS_EVENT_ACTIVE_FRONT" 1 "ABS_EVENT_ACTIVE_FRONT_REAR" 3 "ABS_EVENT_ACTIVE_REAR" 0 "ABS_EVENT_NOT_ACTIVE" ;
VAL_ 325 ESP_absFaultLamp 0 "ABS_FAULT_LAMP_OFF" 1 "ABS_FAULT_LAMP_ON" ;
VAL_ 325 ESP_brakeApply 1 "BLS_ACTIVE" 0 "BLS_INACTIVE" ;
VAL_ 325 ESP_brakeDiscWipingActive 1 "BDW_ACTIVE" 0 "BDW_INACTIVE" ;
VAL_ 325 ESP_brakeLamp 0 "LAMP_OFF" 1 "LAMP_ON" ;
VAL_ 325 ESP_brakeTorqueTarget 8191 "SNA" ;
VAL_ 325 ESP_btcTargetState 1 "BACKUP" 0 "OFF" 2 "ON" 3 "SNA" ;
VAL_ 325 ESP_cdpStatus 2 "ACTUATING_EPB_CDP" 3 "CDP_COMMAND_INVALID" 1 "CDP_IS_AVAILABLE" 0 "CDP_IS_NOT_AVAILABLE" ;
VAL_ 325 ESP_driverBrakeApply 2 "Driver_applying_brakes" 3 "Faulty_SNA" 0 "NotInit_orOff" 1 "Not_Applied" ;
VAL_ 325 ESP_ebdFaultLamp 0 "EBD_FAULT_LAMP_OFF" 1 "EBD_FAULT_LAMP_ON" ;
VAL_ 325 ESP_ebrStandstillSkid 0 "NO_STANDSTILL_SKID" 1 "STANDSTILL_SKID_DETECTED" ;
VAL_ 325 ESP_ebrStatus 2 "ACTUATING_DI_EBR" 3 "EBR_COMMAND_INVALID" 1 "EBR_IS_AVAILABLE" 0 "EBR_IS_NOT_AVAILABLE" ;
VAL_ 325 ESP_espFaultLamp 0 "ESP_FAULT_LAMP_OFF" 1 "ESP_FAULT_LAMP_ON" ;
VAL_ 325 ESP_espLampFlash 1 "ESP_LAMP_FLASH" 0 "ESP_LAMP_OFF" ;
VAL_ 325 ESP_espModeActive 0 "ESP_MODE_00_NORMAL" 1 "ESP_MODE_01" 2 "ESP_MODE_02" 3 "ESP_MODE_03" ;
VAL_ 325 ESP_lateralAccelQF 1 "IN_SPEC" 0 "UNDEFINABLE_ACCURACY" ;
VAL_ 325 ESP_longitudinalAccelQF 1 "IN_SPEC" 0 "UNDEFINABLE_ACCURACY" ;
VAL_ 325 ESP_ptcTargetState 1 "BACKUP" 0 "FAULT" 2 "ON" 3 "SNA" ;
VAL_ 325 ESP_stabilityControlSts2 2 "ENGAGED" 3 "FAULTED" 0 "INIT" 1 "ON" ;
VAL_ 325 ESP_steeringAngleQF 1 "IN_SPEC" 0 "UNDEFINABLE_ACCURACY" ;
VAL_ 325 ESP_yawRateQF 1 "IN_SPEC" 0 "UNDEFINABLE_ACCURACY" ;
VAL_ 341 ESP_WheelRotationReR 3 "WR_NOT_DEFINABLE" 2 "WR_STANDSTILL" 1 "WR_BACKWARD" 0 "WR_FORWARD" ;
VAL_ 341 ESP_WheelRotationReL 3 "WR_NOT_DEFINABLE" 2 "WR_STANDSTILL" 1 "WR_BACKWARD" 0 "WR_FORWARD" ;
VAL_ 341 ESP_WheelRotationFrR 3 "WR_NOT_DEFINABLE" 2 "WR_STANDSTILL" 1 "WR_BACKWARD" 0 "WR_FORWARD" ;
VAL_ 341 ESP_WheelRotationFrL 3 "WR_NOT_DEFINABLE" 2 "WR_STANDSTILL" 1 "WR_BACKWARD" 0 "WR_FORWARD" ;
VAL_ 341 ESP_wheelSpeedsQF 1 "ALL_WSS_VALID" 0 "ONE_OR_MORE_WSS_INVALID" ;
VAL_ 341 ESP_vehicleStandstillSts 1 "STANDSTILL" 0 "NOT_STANDSTILL" ;
VAL_ 341 ESP_vehicleSpeed 1023 "ESP_VEHICLE_SPEED_SNA" ;
VAL_ 373 WheelSpeedRR175 8191 "SNA" ;
VAL_ 373 WheelSpeedRL175 8191 "SNA" ;
VAL_ 373 WheelSpeedFR175 8191 "SNA" ;
VAL_ 373 WheelSpeedFL175 8191 "SNA" ;
VAL_ 389 ESP_brakeTorqueFrL 4095 "SNA" ;
VAL_ 389 ESP_brakeTorqueFrR 4095 "SNA" ;
VAL_ 389 ESP_brakeTorqueReL 4095 "SNA" ;
VAL_ 389 ESP_brakeTorqueReR 4095 "SNA" ;
VAL_ 389 ESP_brakeTorqueQF 1 "IN_SPEC" 0 "UNDEFINABLE_ACCURACY" ;
VAL_ 390 DIF_axleSpeed 32768 "SNA" ;
VAL_ 390 DIF_slavePedalPos 255 "SNA" ;
VAL_ 390 DIF_torqueActual 4096 "SNA" ;
VAL_ 390 DIF_torqueCommand 4096 "SNA" ;
VAL_ 421 DIF_vBatQF 0 "NOT_QUALIFIED" 1 "QUALIFIED" ;
VAL_ 463 PM_hvilSystemStatus 2 "CLOSED" 0 "DISABLED" 1 "OPEN" 3 "SNA" ;
VAL_ 505 VCSEC_chargePortRequest 0 "NONE" 1 "OPEN" 2 "CLOSE" 3 "SNA";
VAL_ 513 VCFRONT_loggingAndVitals10HzInde 7 "END" 3 "EXV_FLOW" 5 "EXV_FLOW_TARGET" 6 "EXV_STATE" 4 "HP_STATE" 2 "STATES_AND_SENSORS" 0 "TARGETS_AND_ACTUALS_0" 1 "TARGETS_SENSORS_AND_ACTUALS_1" ;
VAL_ 513 VCFRONT_cclExvState 8 "CALIB_CLOSE" 9 "CALIB_CLOSE_OVERDRIVE" 4 "FAULTED" 2 "INIT_CLOSE" 1 "INIT_OPEN" 6 "OVERDRIVING_SHUT" 3 "READY" 7 "READY_SHUT" 0 "UNINIT" 5 "WAIT" ;
VAL_ 513 VCFRONT_ccrExvState 8 "CALIB_CLOSE" 9 "CALIB_CLOSE_OVERDRIVE" 4 "FAULTED" 2 "INIT_CLOSE" 1 "INIT_OPEN" 6 "OVERDRIVING_SHUT" 3 "READY" 7 "READY_SHUT" 0 "UNINIT" 5 "WAIT" ;
VAL_ 513 VCFRONT_chillerExvState 8 "CALIB_CLOSE" 9 "CALIB_CLOSE_OVERDRIVE" 4 "FAULTED" 2 "INIT_CLOSE" 1 "INIT_OPEN" 6 "OVERDRIVING_SHUT" 3 "READY" 7 "READY_SHUT" 0 "UNINIT" 5 "WAIT" ;
VAL_ 513 VCFRONT_compressorState 3 "FAULT" 1 "READY" 2 "RUNNING" 0 "STANDBY" ;
VAL_ 513 VCFRONT_coolantValveMode 3 "AMBIENT_SOURCE" 2 "BLEND" 1 "PARALLEL" 0 "SERIES" ;
VAL_ 513 VCFRONT_evapExvState 8 "CALIB_CLOSE" 9 "CALIB_CLOSE_OVERDRIVE" 4 "FAULTED" 2 "INIT_CLOSE" 1 "INIT_OPEN" 6 "OVERDRIVING_SHUT" 3 "READY" 7 "READY_SHUT" 0 "UNINIT" 5 "WAIT" ;
VAL_ 513 VCFRONT_exvState 8 "CALIB_CLOSE" 9 "CALIB_CLOSE_OVERDRIVE" 4 "FAULTED" 2 "INIT_CLOSE" 1 "INIT_OPEN" 6 "OVERDRIVING_SHUT" 3 "READY" 7 "READY_SHUT" 0 "UNINIT" 5 "WAIT" ;
VAL_ 513 VCFRONT_hpBatteryLoadType 2 "BATT_COOL" 1 "BATT_HEAT" 0 "NONE" ;
VAL_ 513 VCFRONT_hpBlendType 2 "HP_FULL" 0 "HP_NONE" 1 "HP_PARTIAL" ;
VAL_ 513 VCFRONT_hpCabinLoadType 1 "CC" 3 "EVAP" 0 "NONE" 2 "REHEAT" ;
VAL_ 513 VCFRONT_hpDominantLoad 5 "CC" 2 "CHILLER" 1 "EVAP" 6 "HIGH_BOTH" 4 "LCC" 3 "LOW_BOTH" 0 "NONE" ;
VAL_ 513 VCFRONT_hpHighSideHX 3 "BOTH" 2 "CC" 1 "LCC" 0 "NONE" ;
VAL_ 513 VCFRONT_hpLowSideHX 3 "BOTH" 1 "CHILLER" 2 "EVAP" 0 "NONE" ;
VAL_ 513 VCFRONT_hpReqCoolantMode 4 "AMBIENT_SOURCE" 0 "ANY" 3 "PARALLEL" 2 "SERIES_BYPASS" 1 "SERIES_NO_BYPASS" ;
VAL_ 513 VCFRONT_lccExvState 8 "CALIB_CLOSE" 9 "CALIB_CLOSE_OVERDRIVE" 4 "FAULTED" 2 "INIT_CLOSE" 1 "INIT_OPEN" 6 "OVERDRIVING_SHUT" 3 "READY" 7 "READY_SHUT" 0 "UNINIT" 5 "WAIT" ;
VAL_ 513 VCFRONT_pressureRefrigDischargeV 255 "SNA" ;
VAL_ 513 VCFRONT_pressureRefrigLiquid 255 "SNA" ;
VAL_ 513 VCFRONT_pressureRefrigSuctionVit 127 "SNA" ;
VAL_ 513 VCFRONT_pumpBatteryRPMActual 1023 "SNA" ;
VAL_ 513 VCFRONT_pumpPowertrainRPMActual 1023 "SNA" ;
VAL_ 513 VCFRONT_radiatorFanRPMActual 1023 "SNA" ;
VAL_ 513 VCFRONT_recircExvState 8 "CALIB_CLOSE" 9 "CALIB_CLOSE_OVERDRIVE" 4 "FAULTED" 2 "INIT_CLOSE" 1 "INIT_OPEN" 6 "OVERDRIVING_SHUT" 3 "READY" 7 "READY_SHUT" 0 "UNINIT" 5 "WAIT" ;
VAL_ 513 VCFRONT_solenoidEvapState 2 "CLOSED" 3 "FAULTED" 1 "OPENED" 0 "UNDEFINED" ;
VAL_ 513 VCFRONT_tempRefrigDischarge 2047 "SNA" ;
VAL_ 513 VCFRONT_tempRefrigLiquid 2047 "SNA" ;
VAL_ 513 VCFRONT_tempSuperheatActual 1023 "SNA" ;
VAL_ 516 PCS_chargeShutdownRequest 2 "EMERGENCY_SHUTDOWN_REQUESTED" 1 "GRACEFUL_SHUTDOWN_REQUESTED" 0 "NO_SHUTDOWN_REQUESTED" ;
VAL_ 516 PCS_chgMainState 9 "PCS_CHG_STATE_CLEAR_FAULTS" 6 "PCS_CHG_STATE_ENABLE" 8 "PCS_CHG_STATE_FAULTED" 1 "PCS_CHG_STATE_IDLE" 0 "PCS_CHG_STATE_INIT" 4 "PCS_CHG_STATE_QUALIFY_LINE_CONFIG" 7 "PCS_CHG_STATE_SHUTDOWN" 2 "PCS_CHG_STATE_STARTUP" 5 "PCS_CHG_STATE_SYSTEM_CONFIG" 3 "PCS_CHG_STATE_WAIT_FOR_LINE_VOLTAGE" ;
VAL_ 516 PCS_gridConfig 1 "GRID_CONFIG_SINGLE_PHASE" 0 "GRID_CONFIG_SNA" 2 "GRID_CONFIG_THREE_PHASE" 3 "GRID_CONFIG_THREE_PHASE_DELTA" ;
VAL_ 516 PCS_hvChargeStatus 1 "PCS_CHARGE_BLOCKED" 2 "PCS_CHARGE_ENABLED" 3 "PCS_CHARGE_FAULTED" 0 "PCS_CHARGE_STANDBY" ;
VAL_ 516 PCS_hwVariantType 1 "PCS_32A_SINGLE_PHASE_VARIANT" 0 "PCS_48A_SINGLE_PHASE_VARIANT" 3 "PCS_HW_VARIANT_TYPE_SNA" 2 "PCS_THREE_PHASES_VARIANT" ;
VAL_ 522 HVP_fcContNegativeState 3 "CONTACTOR_STATE_BLOCKED" 6 "CONTACTOR_STATE_ECONOMIZED" 1 "CONTACTOR_STATE_OPEN" 5 "CONTACTOR_STATE_OPENING" 2 "CONTACTOR_STATE_PRECHARGE" 4 "CONTACTOR_STATE_PULLED_IN" 0 "CONTACTOR_STATE_SNA" 7 "CONTACTOR_STATE_WELDED" ;
VAL_ 522 HVP_fcContPositiveState 3 "CONTACTOR_STATE_BLOCKED" 6 "CONTACTOR_STATE_ECONOMIZED" 1 "CONTACTOR_STATE_OPEN" 5 "CONTACTOR_STATE_OPENING" 2 "CONTACTOR_STATE_PRECHARGE" 4 "CONTACTOR_STATE_PULLED_IN" 0 "CONTACTOR_STATE_SNA" 7 "CONTACTOR_STATE_WELDED" ;
VAL_ 522 HVP_fcContactorSetState 3 "CONTACTOR_SET_STATE_BLOCKED" 5 "CONTACTOR_SET_STATE_CLOSED" 2 "CONTACTOR_SET_STATE_CLOSING" 9 "CONTACTOR_SET_STATE_NEGATIVE_CLOSED" 1 "CONTACTOR_SET_STATE_OPEN" 4 "CONTACTOR_SET_STATE_OPENING" 6 "CONTACTOR_SET_STATE_PARTIAL_WELD" 8 "CONTACTOR_SET_STATE_POSITIVE_CLOSED" 0 "CONTACTOR_SET_STATE_SNA" 7 "CONTACTOR_SET_STATE_WELDED" ;
VAL_ 522 HVP_fcCtrsRequestStatus 1 "REQUEST_ACTIVE" 2 "REQUEST_COMPLETED" 0 "REQUEST_NOT_ACTIVE" ;
VAL_ 522 HVP_fcLinkAllowedToEnergize 1 "FC_LINK_ENERGY_AC" 2 "FC_LINK_ENERGY_DC" 0 "FC_LINK_ENERGY_NONE" ;
VAL_ 522 HVP_hvilStatus 2 "CURRENT_SOURCE_FAULT" 3 "INTERNAL_OPEN_FAULT" 8 "NO_12V_SUPPLY" 5 "PENTHOUSE_LID_OPEN_FAULT" 1 "STATUS_OK" 0 "UNKNOWN" 6 "UNKNOWN_LOCATION_OPEN_FAULT" 7 "VEHICLE_NODE_FAULT" 4 "VEHICLE_OPEN_FAULT" 9 "VEHICLE_OR_PENTHOUSE_LID_OPEN_FAULT" ;
VAL_ 522 HVP_packContNegativeState 3 "CONTACTOR_STATE_BLOCKED" 6 "CONTACTOR_STATE_ECONOMIZED" 1 "CONTACTOR_STATE_OPEN" 5 "CONTACTOR_STATE_OPENING" 2 "CONTACTOR_STATE_PRECHARGE" 4 "CONTACTOR_STATE_PULLED_IN" 0 "CONTACTOR_STATE_SNA" 7 "CONTACTOR_STATE_WELDED" ;
VAL_ 522 HVP_packContPositiveState 3 "CONTACTOR_STATE_BLOCKED" 6 "CONTACTOR_STATE_ECONOMIZED" 1 "CONTACTOR_STATE_OPEN" 5 "CONTACTOR_STATE_OPENING" 2 "CONTACTOR_STATE_PRECHARGE" 4 "CONTACTOR_STATE_PULLED_IN" 0 "CONTACTOR_STATE_SNA" 7 "CONTACTOR_STATE_WELDED" ;
VAL_ 522 HVP_packContactorSetState 3 "CONTACTOR_SET_STATE_BLOCKED" 5 "CONTACTOR_SET_STATE_CLOSED" 2 "CONTACTOR_SET_STATE_CLOSING" 9 "CONTACTOR_SET_STATE_NEGATIVE_CLOSED" 1 "CONTACTOR_SET_STATE_OPEN" 4 "CONTACTOR_SET_STATE_OPENING" 6 "CONTACTOR_SET_STATE_PARTIAL_WELD" 8 "CONTACTOR_SET_STATE_POSITIVE_CLOSED" 0 "CONTACTOR_SET_STATE_SNA" 7 "CONTACTOR_SET_STATE_WELDED" ;
VAL_ 522 HVP_packCtrsRequestStatus 1 "REQUEST_ACTIVE" 2 "REQUEST_COMPLETED" 0 "REQUEST_NOT_ACTIVE" ;
VAL_ 524 VCRIGHT_hvacPerfTestState 2 "BLOWING" 0 "STOPPED" 1 "WAITING" ;
VAL_ 524 VCRIGHT_tempAmbientRaw 0 "SNA" ;
VAL_ 524 VCRIGHT_tempEvaporator 2047 "SNA" ;
VAL_ 524 VCRIGHT_tempEvaporatorTarget 255 "SNA" ;
VAL_ 525 TAS_currentLevel 0 "VERY_HIGH" 1 "HIGH" 2 "STANDARD" 3 "LOW" 4 "VERY_LOW";
VAL_ 525 TAS_filterMode 0 "NONE" 1 "INIT" 2 "CALIBRATE" 3 "TEST" 4 "READY" 5 "LOADING" 6 "DRIVE" 7 "STOPPING";
VAL_ 525 TAS_levelingState 0 "IDLE" 1 "READ_P_RESERVOIR" 2 "MANUAL_SPRING_CONTROL" 3 "EXHAUST_GALLERY" 4 "COMPRESSOR_RAMPUP" 5 "COMPRESSOR_PREFILL_GALLERY" 6 "FILL_RESERVOIR_FROM_COMPRESSOR" 7 "FILL_SPRING_FROM_COMPRESSOR" 8 "FILL_SPRING_FROM_BOOST" 9 "FILL_SPRING_FROM_RESERVOIR" 10 "FILL_SPRING_RESERVOIR_FROM_COMPRESSOR" 11 "LOWER_SPRING" 12 "EMPTY_RESERVOIR";
VAL_ 525 TAS_limpHomeMode 0 "0" 1 "10" 2 "20" 3 "30" 4 "40";
VAL_ 525 TAS_runMode 0 "INIT" 1 "SYSTEM_CHECK" 2 "SERVICE" 3 "ASSEMBLY" 4 "DAN" 5 "NORMAL" 6 "LOW_POWER";
VAL_ 525 TAS_targetLevel 0 "VERY_HIGH" 1 "HIGH" 2 "STANDARD" 3 "LOW" 4 "VERY_LOW";
VAL_ 526 PARK_sdiSensor1RawDistData 0 "BLOCKED" 1 "NEAR_DETECTION" 500 "NO_OBJECT_DETECTED" 511 "SNA" ;
VAL_ 526 PARK_sdiSensor2RawDistData 0 "BLOCKED" 1 "NEAR_DETECTION" 500 "NO_OBJECT_DETECTED" 511 "SNA" ;
VAL_ 526 PARK_sdiSensor3RawDistData 0 "BLOCKED" 1 "NEAR_DETECTION" 500 "NO_OBJECT_DETECTED" 511 "SNA" ;
VAL_ 526 PARK_sdiSensor4RawDistData 0 "BLOCKED" 1 "NEAR_DETECTION" 500 "NO_OBJECT_DETECTED" 511 "SNA" ;
VAL_ 526 PARK_sdiSensor5RawDistData 0 "BLOCKED" 1 "NEAR_DETECTION" 500 "NO_OBJECT_DETECTED" 511 "SNA" ;
VAL_ 526 PARK_sdiSensor6RawDistData 0 "BLOCKED" 1 "NEAR_DETECTION" 500 "NO_OBJECT_DETECTED" 511 "SNA" ;
VAL_ 528 CP_chargeCableState 2 "CHARGE_CABLE_CONNECTED" 1 "CHARGE_CABLE_NOT_CONNECTED" 0 "CHARGE_CABLE_UNKNOWN_SNA" ;
VAL_ 529 RCM_armStatus 2 "ARMED_WITH_NOFIRE_CAL" 1 "RCM_ARMED" 0 "RCM_UNARMED" 3 "SNA" ;
VAL_ 530 BMS_chgPowerAvailable 2047 "SNA" ;
VAL_ 530 BMS_contactorState 6 "BMS_CTRSET_BLOCKED" 4 "BMS_CTRSET_CLOSED" 3 "BMS_CTRSET_CLOSING" 1 "BMS_CTRSET_OPEN" 2 "BMS_CTRSET_OPENING" 0 "BMS_CTRSET_SNA" 5 "BMS_CTRSET_WELDED" ;
VAL_ 530 BMS_diLimpRequest 0 "LIMP_REQUEST_NONE" 1 "LIMP_REQUEST_WELDED" ;
VAL_ 530 BMS_ecuLogUploadRequest 1 "REQUEST_PRIORITY_1" 2 "REQUEST_PRIORITY_2" 3 "REQUEST_PRIORITY_3" 0 "REQUEST_PRIORITY_NONE" ;
VAL_ 530 BMS_hvState 1 "HV_COMING_UP" 0 "HV_DOWN" 2 "HV_GOING_DOWN" 6 "HV_UP" 4 "HV_UP_FOR_CHARGE" 5 "HV_UP_FOR_DC_CHARGE" 3 "HV_UP_FOR_DRIVE" ;
VAL_ 530 BMS_isolationResistance 1023 "SNA" ;
VAL_ 530 BMS_smStateRequest 3 "BMS_CHARGE" 5 "BMS_CLEAR_FAULT" 10 "BMS_DIAG" 1 "BMS_DRIVE" 6 "BMS_FAULT" 4 "BMS_FEIM" 9 "BMS_SNA" 0 "BMS_STANDBY" 2 "BMS_SUPPORT" 8 "BMS_TEST" 7 "BMS_WELD" ;
VAL_ 530 BMS_state 3 "BMS_CHARGE" 5 "BMS_CLEAR_FAULT" 10 "BMS_DIAG" 1 "BMS_DRIVE" 6 "BMS_FAULT" 4 "BMS_FEIM" 9 "BMS_SNA" 0 "BMS_STANDBY" 2 "BMS_SUPPORT" 8 "BMS_TEST" 7 "BMS_WELD" ;
VAL_ 530 BMS_uiChargeStatus 2 "BMS_ABOUT_TO_CHARGE" 4 "BMS_CHARGE_COMPLETE" 5 "BMS_CHARGE_STOPPED" 3 "BMS_CHARGING" 0 "BMS_DISCONNECTED" 1 "BMS_NO_POWER" ;
VAL_ 531 UI_cruiseSpeedCommand 0 "IDLE" 1 "INC_SHORT" 2 "INC_LONG" 3 "DEC_SHORT" 4 "DEC_LONG" 5 "SNAP";
VAL_ 531 UI_speedLimitTick 255 "SNA";
VAL_ 532 FC_postID 2 "FC_POST_ID_2" 3 "FC_POST_ID_SNA" 0 "FC_POST_MASTER" 1 "FC_POST_SLAVE" ;
VAL_ 532 FC_statusCode 3 "FC_STATUS_DEPRECATED_3" 4 "FC_STATUS_DEPRECATED_4" 6 "FC_STATUS_EXT_ISOACTIVE" 5 "FC_STATUS_INT_ISOACTIVE" 14 "FC_STATUS_MALFUNCTION" 15 "FC_STATUS_NODATA" 13 "FC_STATUS_NOTCOMPATIBLE" 0 "FC_STATUS_NOTREADY_SNA" 7 "FC_STATUS_POST_OUT_OF_SERVICE" 1 "FC_STATUS_READY" 2 "FC_STATUS_UPDATE_IN_PROGRESS" ;
VAL_ 532 FC_type 3 "FC_TYPE_CC_EVSE" 1 "FC_TYPE_CHADEMO" 4 "FC_TYPE_COMBO" 2 "FC_TYPE_GB" 5 "FC_TYPE_MC_EVSE" 6 "FC_TYPE_OTHER" 7 "FC_TYPE_SNA" 0 "FC_TYPE_SUPERCHARGER" ;
VAL_ 535 FC_status3DataSelect 0 "Mux0" 1 "Mux1" ;
VAL_ 535 FC_brand 0 "FC_BRAND_SNA" 1 "FC_BRAND_TESLA" ;
VAL_ 535 FC_class 0 "FC_CLASS_SNA" 1 "FC_CLASS_SUPERCHARGER" 2 "FC_CLASS_URBANCHARGER" ;
VAL_ 535 FC_coolingType 2 "FC_COOLING_TYPE_CONVECTION" 1 "FC_COOLING_TYPE_LIQUID" 0 "FC_COOLING_TYPE_SNA" ;
VAL_ 535 FC_generation 0 "GENERATION_SNA" ;
VAL_ 535 FC_uiStopType 2 "FC_UI_STOP_TYPE_MOMENTARY" 0 "FC_UI_STOP_TYPE_SNA" 1 "FC_UI_STOP_TYPE_TOGGLE" ;
VAL_ 536 UI_roadSign 0 "NONE" 1 "STOP_SIGN" 2 "TRAFFIC_LIGHT" 3 "SPEED_LIMIT" 4 "SPEED_SPLINE" 5 "SPLINE_ID_FULL" 255 "SNA";
VAL_ 536 UI_splineLocConfidence 0 "SNA";
VAL_ 536 UI_stopSignStopLineDist 1023 "SNA";
VAL_ 536 UI_stopSignStopLineConf 0 "SNA";
VAL_ 536 UI_trafficLightStopLineDist 1023 "SNA";
VAL_ 536 UI_trafficLightStopLineConf 0 "SNA";
VAL_ 536 UI_baseMapSpeedLimitMPS 255 "SNA";
VAL_ 536 UI_bottomQrtlFleetSpeedMPS 255 "SNA";
VAL_ 536 UI_topQrtlFleetSpeedMPS 255 "SNA";
VAL_ 536 UI_meanFleetSplineSpeedMPS 255 "SNA";
VAL_ 536 UI_medianFleetSpeedMPS 255 "SNA";
VAL_ 536 UI_meanFleetSplineAccelMPS2 255 "SNA";
VAL_ 536 UI_rampType 0 "NONE_SNA" 1 "ENTRANCE" 2 "EXIT" 3 "INTERCHANGE_ENTRANCE" 4 "INTERCHANGE_EXIT";
VAL_ 536 UI_currSplineIdFull 0 "SNA";
VAL_ 537 VCSEC_TPMSDataIndex 0 "TPMS_DATA_SENSOR_0" 1 "TPMS_DATA_SENSOR_1" 2 "TPMS_DATA_SENSOR_2" 3 "TPMS_DATA_SENSOR_3" ;
VAL_ 537 VCSEC_TPMSBatVoltage0 255 "SNA" ;
VAL_ 537 VCSEC_TPMSBatVoltage1 255 "SNA" ;
VAL_ 537 VCSEC_TPMSBatVoltage2 255 "SNA" ;
VAL_ 537 VCSEC_TPMSBatVoltage3 255 "SNA" ;
VAL_ 537 VCSEC_TPMSLocation0 0 "LOCATION_FL" 1 "LOCATION_FR" 2 "LOCATION_RL" 3 "LOCATION_RR" 4 "LOCATION_UNKNOWN" ;
VAL_ 537 VCSEC_TPMSLocation1 0 "LOCATION_FL" 1 "LOCATION_FR" 2 "LOCATION_RL" 3 "LOCATION_RR" 4 "LOCATION_UNKNOWN" ;
VAL_ 537 VCSEC_TPMSLocation2 0 "LOCATION_FL" 1 "LOCATION_FR" 2 "LOCATION_RL" 3 "LOCATION_RR" 4 "LOCATION_UNKNOWN" ;
VAL_ 537 VCSEC_TPMSLocation3 0 "LOCATION_FL" 1 "LOCATION_FR" 2 "LOCATION_RL" 3 "LOCATION_RR" 4 "LOCATION_UNKNOWN" ;
VAL_ 537 VCSEC_TPMSPressure0 255 "SNA" ;
VAL_ 537 VCSEC_TPMSPressure1 255 "SNA" ;
VAL_ 537 VCSEC_TPMSPressure2 255 "SNA" ;
VAL_ 537 VCSEC_TPMSPressure3 255 "SNA" ;
VAL_ 537 VCSEC_TPMSTemperature0 255 "SNA" ;
VAL_ 537 VCSEC_TPMSTemperature1 255 "SNA" ;
VAL_ 537 VCSEC_TPMSTemperature2 255 "SNA" ;
VAL_ 537 VCSEC_TPMSTemperature3 255 "SNA" ;
VAL_ 541 CP_acChargeState 1 "AC_CHARGE_CONNECTED_CHARGE_BLOCKED" 3 "AC_CHARGE_ENABLED" 6 "AC_CHARGE_FAULT" 0 "AC_CHARGE_INACTIVE" 4 "AC_CHARGE_ONBOARD_CHARGER_SHUTDOWN" 2 "AC_CHARGE_STANDBY" 5 "AC_CHARGE_VEH_SHUTDOWN" ;
VAL_ 541 CP_cableType 2 "CHG_CABLE_TYPE_GB_AC" 3 "CHG_CABLE_TYPE_GB_DC" 0 "CHG_CABLE_TYPE_IEC" 1 "CHG_CABLE_TYPE_SAE" 4 "CHG_CABLE_TYPE_SNA" ;
VAL_ 541 CP_evseChargeType_UI 2 "AC_CHARGER_PRESENT" 1 "DC_CHARGER_PRESENT" 0 "NO_CHARGER_PRESENT" ;
VAL_ 541 CP_gbState 10 "GBDC_CHARGE_DISABLING" 5 "GBDC_CHARGE_PARAM_CONFIG" 8 "GBDC_CHARGING" 2 "GBDC_COMMS_RECEIVED" 11 "GBDC_END_OF_CHARGE" 12 "GBDC_ERROR_HANDLING" 14 "GBDC_FAULTED" 3 "GBDC_HANDSHAKING_EXT_ISO" 0 "GBDC_INACTIVE" 7 "GBDC_READY_TO_CHARGE" 4 "GBDC_RECOGNITION" 13 "GBDC_RETRY_CHARGE" 9 "GBDC_STOP_CHARGE_REQUESTED" 15 "GBDC_TESTER_PRESENT" 6 "GBDC_VEH_PACK_PRECHARGE" 1 "GBDC_WAIT_FOR_COMMS" ;
VAL_ 541 CP_gbdcFailureReason 1 "GBDC_ATTEMPTS_EXPIRED" 3 "GBDC_CRITICAL_FAILURE" 0 "GBDC_FAILURE_NONE" 2 "GBDC_SHUTDOWN_FAILURE" ;
VAL_ 541 CP_gbdcStopChargeReason 3 "GBDC_COMMS_TIMEOUT" 5 "GBDC_EVSE_CRITICAL_FAULT" 4 "GBDC_EVSE_FAULT" 2 "GBDC_EVSE_REQUESTED" 6 "GBDC_LIVE_DISCONNECT" 0 "GBDC_STOP_REASON_NONE" 7 "GBDC_SUPERCHARGER_COMMS_TIMEOUT" 1 "GBDC_VEH_REQUESTED" ;
VAL_ 541 CP_iecComboState 6 "IEC_COMBO_CABLE_CHECK" 5 "IEC_COMBO_CHARGE_PARAM_DISCOVERY" 1 "IEC_COMBO_CONNECTED" 8 "IEC_COMBO_ENABLED" 10 "IEC_COMBO_END_OF_CHARGE" 11 "IEC_COMBO_FAULT" 0 "IEC_COMBO_INACTIVE" 4 "IEC_COMBO_PAYMENT_SELECTION" 7 "IEC_COMBO_PRECHARGE" 3 "IEC_COMBO_SERVICE_DISCOVERY" 9 "IEC_COMBO_SHUTDOWN" 2 "IEC_COMBO_V2G_SESSION_SETUP" 12 "IEC_COMBO_WAIT_RESTART" ;
VAL_ 541 CP_pilot 3 "CHG_PILOT_FAST_CHARGE" 1 "CHG_PILOT_FAULTED" 4 "CHG_PILOT_IDLE" 5 "CHG_PILOT_INVALID" 2 "CHG_PILOT_LINE_CHARGE" 0 "CHG_PILOT_NONE" 7 "CHG_PILOT_SNA" 6 "CHG_PILOT_UNUSED_6" ;
VAL_ 541 CP_proximity 1 "CHG_PROXIMITY_DISCONNECTED" 3 "CHG_PROXIMITY_LATCHED" 0 "CHG_PROXIMITY_SNA" 2 "CHG_PROXIMITY_UNLATCHED" ;
VAL_ 541 CP_teslaDcState 1 "TESLA_DC_CONNECTED_CHARGE_BLOCKED" 9 "TESLA_DC_EMERGENCY_SHUTDOWN" 6 "TESLA_DC_ENABLED" 7 "TESLA_DC_EVSE_SHUTDOWN" 5 "TESLA_DC_EXT_PRECHARGE_ACTIVE" 3 "TESLA_DC_EXT_TESTS_ENABLED" 4 "TESLA_DC_EXT_TEST_ACTIVE" 10 "TESLA_DC_FAULT" 0 "TESLA_DC_INACTIVE" 2 "TESLA_DC_STANDBY" 8 "TESLA_DC_VEH_SHUTDOWN" ;
VAL_ 541 CP_teslaSwcanState 1 "TESLA_SWCAN_ACCEPT" 3 "TESLA_SWCAN_ESTABLISHED" 4 "TESLA_SWCAN_FAULT" 5 "TESLA_SWCAN_GO_TO_SLEEP" 0 "TESLA_SWCAN_INACTIVE" 6 "TESLA_SWCAN_OFFBOARD_UPDATE_IN_PROGRESS" 2 "TESLA_SWCAN_RECEIVE" ;
VAL_ 542 PARK_pscAngleActive 0 "INACTIVE" 1 "REQUEST_CONTROL";
VAL_ 542 PARK_pscCrossLeftParkable 0 "NONE" 1 "PARKING_SLOT_OK" 2 "PARKING_SLOT_OK_POSITION_OK" 3 "SNA";
VAL_ 542 PARK_pscCrossRightParkable 0 "NONE" 1 "PARKING_SLOT_OK" 2 "PARKING_SLOT_OK_POSITION_OK" 3 "SNA";
VAL_ 542 PARK_pscCrossSpace 0 "NONE_AVAILABLE" 1 "RIGHT_AVAILABLE" 2 "LEFT_AVAILABLE" 3 "BOTH_AVAILABLE";
VAL_ 542 PARK_pscManeuverDistance 2047 "SNA";
VAL_ 542 PARK_pscMaxVelocity 63 "SNA";
VAL_ 542 PARK_pscParallelLeftParkable 0 "NONE" 1 "PARKING_SLOT_OK" 2 "PARKING_SLOT_OK_POSITION_OK" 3 "SNA";
VAL_ 542 PARK_pscParallelRightParkable 0 "NONE" 1 "PARKING_SLOT_OK" 2 "PARKING_SLOT_OK_POSITION_OK" 3 "SNA";
VAL_ 542 PARK_pscParallelSpace 0 "NONE_AVAILABLE" 1 "RIGHT_AVAILABLE" 2 "LEFT_AVAILABLE" 3 "BOTH_AVAILABLE";
VAL_ 542 PARK_pscParkAbortReason 0 "NONE" 1 "VELOCITY_TOO_HIGH" 2 "MAX_NUM_OF_MOVES" 3 "NO_VALID_PATH" 4 "UNCONTROLLED_TRAVEL_DIST_REACHED" 5 "OFF_TRACK" 6 "MAX_SWA_DEV_EXCEEDED" 7 "MAX_YAW_ANGLE_REACHED" 8 "OBSTACLE_ON_PATH" 9 "PARK_SPACE_TOO_SMALL" 10 "FULL_WARNING_ON_BOTH_SIDES" 11 "HANDS_ON_DETECTED" 12 "VEHICLE_DYNAMICS_INTERVENTION" 13 "EPAS_FAULT" 14 "DAS_ABORT" 15 "ECU_INTERNAL_FAULT" 16 "SYSTEM_FAULT" 17 "SYSTEM_SERVICE" 18 "ERROR" 31 "SNA";
VAL_ 542 PARK_pscParkInstruction 0 "NO_MESSAGE" 1 "STOP" 2 "DRIVE_FORWARD" 3 "DRIVE_BACKWARD" 4 "ABORTED" 5 "EXPLORATION" 7 "SNA";
VAL_ 542 PARK_pscParkStatus 0 "NOT_AVAILABLE" 1 "SEARCHING" 2 "GUIDANCE_LEFT" 3 "GUIDANCE_RIGHT" 4 "PRE_GUIDANCE" 5 "GUIDANCE_FINISHED" 6 "FAULT" 7 "SNA";
VAL_ 545 VCFRONT_LVPowerStateIndex 0 "Mux0" 1 "Mux1" ;
VAL_ 545 VCFRONT_CMPDLVState 3 "LV_FAULT" 2 "LV_GOING_DOWN" 0 "LV_OFF" 1 "LV_ON" ;
VAL_ 545 VCFRONT_amplifierLVRequest 3 "LV_FAULT" 2 "LV_GOING_DOWN" 0 "LV_OFF" 1 "LV_ON" ;
VAL_ 545 VCFRONT_cpLVRequest 3 "LV_FAULT" 2 "LV_GOING_DOWN" 0 "LV_OFF" 1 "LV_ON" ;
VAL_ 545 VCFRONT_das1HighCurrentLVState 3 "LV_FAULT" 2 "LV_GOING_DOWN" 0 "LV_OFF" 1 "LV_ON" ;
VAL_ 545 VCFRONT_das2HighCurrentLVState 3 "LV_FAULT" 2 "LV_GOING_DOWN" 0 "LV_OFF" 1 "LV_ON" ;
VAL_ 545 VCFRONT_difLVState 3 "LV_FAULT" 2 "LV_GOING_DOWN" 0 "LV_OFF" 1 "LV_ON" ;
VAL_ 545 VCFRONT_dirLVRequest 3 "LV_FAULT" 2 "LV_GOING_DOWN" 0 "LV_OFF" 1 "LV_ON" ;
VAL_ 545 VCFRONT_epasLVState 3 "LV_FAULT" 2 "LV_GOING_DOWN" 0 "LV_OFF" 1 "LV_ON" ;
VAL_ 545 VCFRONT_espLVState 3 "LV_FAULT" 2 "LV_GOING_DOWN" 0 "LV_OFF" 1 "LV_ON" ;
VAL_ 545 VCFRONT_hvacCompLVState 3 "LV_FAULT" 2 "LV_GOING_DOWN" 0 "LV_OFF" 1 "LV_ON" ;
VAL_ 545 VCFRONT_hvcLVRequest 3 "LV_FAULT" 2 "LV_GOING_DOWN" 0 "LV_OFF" 1 "LV_ON" ;
VAL_ 545 VCFRONT_iBoosterLVState 3 "LV_FAULT" 2 "LV_GOING_DOWN" 0 "LV_OFF" 1 "LV_ON" ;
VAL_ 545 VCFRONT_ocsLVRequest 3 "LV_FAULT" 2 "LV_GOING_DOWN" 0 "LV_OFF" 1 "LV_ON" ;
VAL_ 545 VCFRONT_oilPumpFrontLVState 3 "LV_FAULT" 2 "LV_GOING_DOWN" 0 "LV_OFF" 1 "LV_ON" ;
VAL_ 545 VCFRONT_oilPumpRearLVRequest 3 "LV_FAULT" 2 "LV_GOING_DOWN" 0 "LV_OFF" 1 "LV_ON" ;
VAL_ 545 VCFRONT_parkLVState 3 "LV_FAULT" 2 "LV_GOING_DOWN" 0 "LV_OFF" 1 "LV_ON" ;
VAL_ 545 VCFRONT_pcsLVState 3 "LV_FAULT" 2 "LV_GOING_DOWN" 0 "LV_OFF" 1 "LV_ON" ;
VAL_ 545 VCFRONT_ptcLVRequest 3 "LV_FAULT" 2 "LV_GOING_DOWN" 0 "LV_OFF" 1 "LV_ON" ;
VAL_ 545 VCFRONT_radcLVState 3 "LV_FAULT" 2 "LV_GOING_DOWN" 0 "LV_OFF" 1 "LV_ON" ;
VAL_ 545 VCFRONT_rcmLVRequest 3 "LV_FAULT" 2 "LV_GOING_DOWN" 0 "LV_OFF" 1 "LV_ON" ;
VAL_ 545 VCFRONT_sccmLVRequest 3 "LV_FAULT" 2 "LV_GOING_DOWN" 0 "LV_OFF" 1 "LV_ON" ;
VAL_ 545 VCFRONT_tasLVState 3 "LV_FAULT" 2 "LV_GOING_DOWN" 0 "LV_OFF" 1 "LV_ON" ;
VAL_ 545 VCFRONT_tpmsLVRequest 3 "LV_FAULT" 2 "LV_GOING_DOWN" 0 "LV_OFF" 1 "LV_ON" ;
VAL_ 545 VCFRONT_tunerLVRequest 3 "LV_FAULT" 2 "LV_GOING_DOWN" 0 "LV_OFF" 1 "LV_ON" ;
VAL_ 545 VCFRONT_uiHiCurrentLVState 3 "LV_FAULT" 2 "LV_GOING_DOWN" 0 "LV_OFF" 1 "LV_ON" ;
VAL_ 545 VCFRONT_vcleftHiCurrentLVState 3 "LV_FAULT" 2 "LV_GOING_DOWN" 0 "LV_OFF" 1 "LV_ON" ;
VAL_ 545 VCFRONT_vcrightHiCurrentLVState 3 "LV_FAULT" 2 "LV_GOING_DOWN" 0 "LV_OFF" 1 "LV_ON" ;
VAL_ 548 DCDCstate224 6 "Error" 5 "Shutdown" 4 "HVactive" 3 "Precharge" 2 "PrechargeStart" 1 "12vChg" 0 "Idle" ;
VAL_ 548 DCDCSubState224 0 "PWR_UP_INIT" 1 "STANDBY" 2 "12V_SUPPORT_ACTIVE" 3 "DIS_HVBUS" 4 "PCHG_FAST_DIS_HVBUS" 5 "PCHG_SLOW_DIS_HVBUS" 6 "PCHG_DWELL_CHARGE" 7 "PCHG_DWELL_WAIT" 8 "PCHG_DI_RECOVERY_WAIT" 9 "PCHG_ACTIVE" 10 "PCHG_FLT_FAST_DIS_HVBUS" 11 "SHUTDOWN" 12 "12V_SUPPORT_FAULTED" 13 "DIS_HVBUS_FAULTED" 14 "PCHG_FAULTED" 15 "CLEAR_FAULTS" 16 "FAULTED" 17 "NUM" ;
VAL_ 549 VCRIGHT_amplifierLVState 3 "LV_FAULT" 2 "LV_GOING_DOWN" 0 "LV_OFF" 1 "LV_ON" ;
VAL_ 549 VCRIGHT_eFuseLockoutStatus 2 "EFUSE_LOCKOUT_STATUS_ACTIVE" 0 "EFUSE_LOCKOUT_STATUS_IDLE" 1 "EFUSE_LOCKOUT_STATUS_PENDING" ;
VAL_ 549 VCRIGHT_hvcLVState 3 "LV_FAULT" 2 "LV_GOING_DOWN" 0 "LV_OFF" 1 "LV_ON" ;
VAL_ 549 VCRIGHT_lumbarLVState 3 "LV_FAULT" 2 "LV_GOING_DOWN" 0 "LV_OFF" 1 "LV_ON" ;
VAL_ 549 VCRIGHT_ocsLVState 3 "LV_FAULT" 2 "LV_GOING_DOWN" 0 "LV_OFF" 1 "LV_ON" ;
VAL_ 549 VCRIGHT_ptcLVState 3 "LV_FAULT" 2 "LV_GOING_DOWN" 0 "LV_OFF" 1 "LV_ON" ;
VAL_ 549 VCRIGHT_rcmLVState 3 "LV_FAULT" 2 "LV_GOING_DOWN" 0 "LV_OFF" 1 "LV_ON" ;
VAL_ 549 VCRIGHT_rearOilPumpLVState 3 "LV_FAULT" 2 "LV_GOING_DOWN" 0 "LV_OFF" 1 "LV_ON" ;
VAL_ 549 VCRIGHT_tunerLVState 3 "LV_FAULT" 2 "LV_GOING_DOWN" 0 "LV_OFF" 1 "LV_ON" ;
VAL_ 549 VCRIGHT_vehiclePowerStateDBG 2 "VEHICLE_POWER_STATE_ACCESSORY" 1 "VEHICLE_POWER_STATE_CONDITIONING" 3 "VEHICLE_POWER_STATE_DRIVE" 0 "VEHICLE_POWER_STATE_OFF" ;
VAL_ 551 CMP_state 3 "CMP_STATE_FAULT" 0 "CMP_STATE_NONE" 1 "CMP_STATE_NORMAL" 15 "CMP_STATE_SNA" 5 "CMP_STATE_SOFT_SHUTDOWN" 4 "CMP_STATE_SOFT_START" 2 "CMP_STATE_WAIT" ;
VAL_ 552 EPBResmCaliperRequest228 3 "disengaging" 2 "engaging" 1 "idle" ;
VAL_ 552 EPBResmOperationTrigger228 22 "SuperPark" 6 "Released" 1 "ParkEngaged" ;
VAL_ 552 EPBRunitStatus228 10 "Disengaging" 8 "Engaging" 3 "ParkEngaged" 1 "DriveReleased" ;
VAL_ 553 GearLeverPosition229 4 "Full Up" 3 "Half Up" 2 "Full Down" 1 "Half Down" 0 "Center" ;
VAL_ 554 HVP_dcLinkVoltageFiltered 550 "SNA" ;
VAL_ 554 HVP_pcsControlRequest 3 "DISCHARGE" 2 "PRECHARGE" 0 "SHUTDOWN" 1 "SUPPORT" ;
VAL_ 558 PARK_sdiSensor10RawDistData 0 "BLOCKED" 1 "NEAR_DETECTION" 500 "NO_OBJECT_DETECTED" 511 "SNA" ;
VAL_ 558 PARK_sdiSensor11RawDistData 0 "BLOCKED" 1 "NEAR_DETECTION" 500 "NO_OBJECT_DETECTED" 511 "SNA" ;
VAL_ 558 PARK_sdiSensor12RawDistData 0 "BLOCKED" 1 "NEAR_DETECTION" 500 "NO_OBJECT_DETECTED" 511 "SNA" ;
VAL_ 558 PARK_sdiSensor7RawDistData 0 "BLOCKED" 1 "NEAR_DETECTION" 500 "NO_OBJECT_DETECTED" 511 "SNA" ;
VAL_ 558 PARK_sdiSensor8RawDistData 0 "BLOCKED" 1 "NEAR_DETECTION" 500 "NO_OBJECT_DETECTED" 511 "SNA" ;
VAL_ 558 PARK_sdiSensor9RawDistData 0 "BLOCKED" 1 "NEAR_DETECTION" 500 "NO_OBJECT_DETECTED" 511 "SNA" ;
VAL_ 562 BMS_fcContactorRequest 1 "SET_REQUEST_CLOSE" 4 "SET_REQUEST_CLOSE_NEGATIVE_ONLY" 5 "SET_REQUEST_CLOSE_POSITIVE_ONLY" 2 "SET_REQUEST_OPEN" 3 "SET_REQUEST_OPEN_IMMEDIATELY" 0 "SET_REQUEST_SNA" ;
VAL_ 562 BMS_fcLinkOkToEnergizeRequest 1 "FC_LINK_ENERGY_AC" 2 "FC_LINK_ENERGY_DC" 0 "FC_LINK_ENERGY_NONE" ;
VAL_ 562 BMS_internalHvilSenseV 65535 "SNA" ;
VAL_ 562 BMS_packContactorRequest 1 "SET_REQUEST_CLOSE" 4 "SET_REQUEST_CLOSE_NEGATIVE_ONLY" 5 "SET_REQUEST_CLOSE_POSITIVE_ONLY" 2 "SET_REQUEST_OPEN" 3 "SET_REQUEST_OPEN_IMMEDIATELY" 0 "SET_REQUEST_SNA" ;
VAL_ 568 UI_countryCode 1023 "SNA" 0 "UNKNOWN" ;
VAL_ 568 UI_mapSpeedLimit 3 "LESS_OR_EQ_10" 21 "LESS_OR_EQ_100" 22 "LESS_OR_EQ_105" 23 "LESS_OR_EQ_110" 24 "LESS_OR_EQ_115" 25 "LESS_OR_EQ_120" 26 "LESS_OR_EQ_130" 27 "LESS_OR_EQ_140" 4 "LESS_OR_EQ_15" 28 "LESS_OR_EQ_150" 29 "LESS_OR_EQ_160" 5 "LESS_OR_EQ_20" 6 "LESS_OR_EQ_25" 7 "LESS_OR_EQ_30" 8 "LESS_OR_EQ_35" 9 "LESS_OR_EQ_40" 10 "LESS_OR_EQ_45" 1 "LESS_OR_EQ_5" 11 "LESS_OR_EQ_50" 12 "LESS_OR_EQ_55" 13 "LESS_OR_EQ_60" 14 "LESS_OR_EQ_65" 2 "LESS_OR_EQ_7" 15 "LESS_OR_EQ_70" 16 "LESS_OR_EQ_75" 17 "LESS_OR_EQ_80" 18 "LESS_OR_EQ_85" 19 "LESS_OR_EQ_90" 20 "LESS_OR_EQ_95" 31 "SNA" 0 "UNKNOWN" 30 "UNLIMITED" ;
VAL_ 568 UI_mapSpeedLimitDependency 6 "LANE" 0 "NONE" 2 "RAIN" 1 "SCHOOL" 5 "SEASON" 7 "SNA" 3 "SNOW" 4 "TIME" ;
VAL_ 568 UI_mapSpeedLimitType 2 "ADVISORY" 4 "BUMPS" 3 "DEPENDENT" 1 "REGULAR" 7 "UNKNOWN_SNA" ;
VAL_ 568 UI_mapSpeedUnits 1 "KPH" 0 "MPH" ;
VAL_ 568 UI_nextBranchDist 31 "SNA" ;
VAL_ 568 UI_roadClass 1 "CLASS_1_MAJOR" 2 "CLASS_2" 3 "CLASS_3" 4 "CLASS_4" 5 "CLASS_5" 6 "CLASS_6_MINOR" 0 "UNKNOWN_INVALID_SNA" ;
VAL_ 569 DAS_leftFork 1 "LEFT_FORK_AVAILABLE" 0 "LEFT_FORK_NONE" 2 "LEFT_FORK_SELECTED" 3 "LEFT_FORK_UNAVAILABLE" ;
VAL_ 569 DAS_leftLineUsage 1 "AVAILABLE" 3 "BLACKLISTED" 2 "FUSED" 0 "REJECTED_UNAVAILABLE" ;
VAL_ 569 DAS_rightFork 1 "RIGHT_FORK_AVAILABLE" 0 "RIGHT_FORK_NONE" 2 "RIGHT_FORK_SELECTED" 3 "RIGHT_FORK_UNAVAILABLE" ;
VAL_ 569 DAS_rightLineUsage 1 "AVAILABLE" 3 "BLACKLISTED" 2 "FUSED" 0 "REJECTED_UNAVAILABLE" ;
VAL_ 570 VCSEC_TPMSStatusIndex 12 "CPUTimeSensor0" 13 "CPUTimeSensor1" 14 "CPUTimeSensor2" 15 "CPUTimeSensor3" 8 "CRCSensor0" 9 "CRCSensor1" 10 "CRCSensor2" 11 "CRCSensor3" 4 "ConnMetricsSensor0" 5 "ConnMetricsSensor1" 6 "ConnMetricsSensor2" 7 "ConnMetricsSensor3" 0 "MACAddressSensor0" 1 "MACAddressSensor1" 2 "MACAddressSensor2" 3 "MACAddressSensor3" 16 "SleepStatsSensor0" 17 "SleepStatsSensor1" 18 "SleepStatsSensor2" 19 "SleepStatsSensor3" ;
VAL_ 573 CP_chargeShutdownRequest 2 "EMERGENCY_SHUTDOWN_REQUESTED" 1 "GRACEFUL_SHUTDOWN_REQUESTED" 0 "NO_SHUTDOWN_REQUESTED" ;
VAL_ 573 CP_hvChargeStatus 1 "CP_CHARGE_CONNECTED" 5 "CP_CHARGE_ENABLED" 6 "CP_CHARGE_FAULTED" 0 "CP_CHARGE_INACTIVE" 2 "CP_CHARGE_STANDBY" 4 "CP_EVSE_TEST_PASSED" 3 "CP_EXT_EVSE_TEST_ACTIVE" ;
VAL_ 577 VCFRONT_coolantAirPurgeBatState 1 "AIR_PURGE_STATE_ACTIVE" 2 "AIR_PURGE_STATE_COMPLETE" 0 "AIR_PURGE_STATE_INACTIVE" 3 "AIR_PURGE_STATE_INTERRUPTED" 4 "AIR_PURGE_STATE_PENDING" ;
VAL_ 577 VCFRONT_coolantFlowBatReason 4 "ACTIVE_MANAGER_BATT" 9 "ACTIVE_MANAGER_PT" 6 "BMS_FLOW_REQ" 1 "COOLANT_AIR_PURGE" 7 "DAS_FLOW_REQ" 13 "DIS_FLOW_REQ" 12 "DI_FLOW_REQ" 14 "HP_FLOW_REQ" 0 "NONE" 2 "NO_FLOW_REQ" 3 "OVERRIDE_BATT" 8 "OVERRIDE_PT" 5 "PASSIVE_MANAGER_BATT" 10 "PASSIVE_MANAGER_PT" 11 "PCS_FLOW_REQ" ;
VAL_ 577 VCFRONT_coolantFlowPTReason 4 "ACTIVE_MANAGER_BATT" 9 "ACTIVE_MANAGER_PT" 6 "BMS_FLOW_REQ" 1 "COOLANT_AIR_PURGE" 7 "DAS_FLOW_REQ" 13 "DIS_FLOW_REQ" 12 "DI_FLOW_REQ" 14 "HP_FLOW_REQ" 0 "NONE" 2 "NO_FLOW_REQ" 3 "OVERRIDE_BATT" 8 "OVERRIDE_PT" 5 "PASSIVE_MANAGER_BATT" 10 "PASSIVE_MANAGER_PT" 11 "PCS_FLOW_REQ" ;
VAL_ 577 VCFRONT_wasteHeatRequestType 2 "WASTE_TYPE_FULL" 0 "WASTE_TYPE_NONE" 1 "WASTE_TYPE_PARTIAL" ;
VAL_ 578 VCLEFT_cpLVState 3 "LV_FAULT" 2 "LV_GOING_DOWN" 0 "LV_OFF" 1 "LV_ON" ;
VAL_ 578 VCLEFT_diLVState 3 "LV_FAULT" 2 "LV_GOING_DOWN" 0 "LV_OFF" 1 "LV_ON" ;
VAL_ 578 VCLEFT_lumbarLVState 3 "LV_FAULT" 2 "LV_GOING_DOWN" 0 "LV_OFF" 1 "LV_ON" ;
VAL_ 578 VCLEFT_rcmLVState 3 "LV_FAULT" 2 "LV_GOING_DOWN" 0 "LV_OFF" 1 "LV_ON" ;
VAL_ 578 VCLEFT_sccmLVState 3 "LV_FAULT" 2 "LV_GOING_DOWN" 0 "LV_OFF" 1 "LV_ON" ;
VAL_ 578 VCLEFT_swcLVState 3 "LV_FAULT" 2 "LV_GOING_DOWN" 0 "LV_OFF" 1 "LV_ON" ;
VAL_ 578 VCLEFT_tpmsLVState 3 "LV_FAULT" 2 "LV_GOING_DOWN" 0 "LV_OFF" 1 "LV_ON" ;
VAL_ 578 VCLEFT_vehiclePowerStateDBG 2 "VEHICLE_POWER_STATE_ACCESSORY" 1 "VEHICLE_POWER_STATE_CONDITIONING" 3 "VEHICLE_POWER_STATE_DRIVE" 0 "VEHICLE_POWER_STATE_OFF" ;
VAL_ 579 VCRIGHT_hvacStatusIndex 3 "END" 0 "STATUS_UI" 1 "STATUS_VCFRONT" 2 "STATUS_VCFRONT2" ;
VAL_ 579 VCRIGHT_hvacACRunning 0 "OFF" 1 "ON" ;
VAL_ 579 VCRIGHT_hvacAirDistributionMode 4 "DEFROST" 5 "DEFROST_FLOOR" 6 "DEFROST_PANEL" 7 "DEFROST_PANEL_FLOOR" 1 "FLOOR" 0 "NONE" 2 "PANEL" 3 "PANEL_FLOOR" ;
VAL_ 579 VCRIGHT_hvacBlowerSegment 1 "1" 10 "10" 11 "11" 2 "2" 3 "3" 4 "4" 5 "5" 6 "6" 7 "7" 8 "8" 9 "9" 0 "OFF" ;
VAL_ 579 VCRIGHT_hvacDuctTargetLeft 255 "SNA" ;
VAL_ 579 VCRIGHT_hvacDuctTargetRight 255 "SNA" ;
VAL_ 579 VCRIGHT_hvacEvapInletTempEstimat 1023 "SNA" ;
VAL_ 579 VCRIGHT_hvacModelInitStatus 4 "INIT_FORWARD_CALC" 2 "INIT_FROM_SENSORS" 3 "INIT_FROM_SENSORS_PREDICTION_ERROR" 5 "INIT_WAITING_FOR_SENSORS" 1 "NOT_INIT_WAIT_FOR_GTW" 0 "NOT_INIT_WAIT_FOR_SENSORS" ;
VAL_ 579 VCRIGHT_hvacPowerState 0 "OFF" 1 "ON" 4 "OVERHEAT_PROTECT" 3 "OVERHEAT_PROTECT_FANONLY" 2 "PRECONDITION" ;
VAL_ 579 VCRIGHT_hvacRecirc 0 "AUTO" 2 "FRESH" 1 "RECIRC" ;
VAL_ 579 VCRIGHT_hvacSecondRowState 0 "AUTO" 4 "HIGH" 2 "LOW" 3 "MED" 1 "OFF" ;
VAL_ 579 VCRIGHT_hvacVentStatus 0 "BOTH" 1 "LEFT" 2 "RIGHT" ;
VAL_ 579 VCRIGHT_tempDuctLeft 255 "SNA" ;
VAL_ 579 VCRIGHT_tempDuctLeftLower 255 "SNA" ;
VAL_ 579 VCRIGHT_tempDuctLeftUpper 255 "SNA" ;
VAL_ 579 VCRIGHT_tempDuctRight 255 "SNA" ;
VAL_ 579 VCRIGHT_tempDuctRightLower 255 "SNA" ;
VAL_ 579 VCRIGHT_tempDuctRightUpper 255 "SNA" ;
VAL_ 583 DAS_autopilotAbortReason 0 "NONE" 1 "WATCHDOG_HEALTH" 2 "DI_MIA" 3 "ESP_MIA" 4 "EPAS_MIA" 5 "GTW_MIA" 6 "SCCM_MIA" 7 "RADAR_MIA" 8 "VCFRONT_MIA" 9 "VCRIGHT_MIA" 10 "CRUISE_FAULT" 11 "CRUISE_NOT_ACTIVE" 12 "USER_DISABLED" 13 "TRAILER_MODE_ACTIVE" 14 "VEHICLE_SPEED_ABOVE_MAX" 15 "EPAS_EAC_NOT_ACTIVE" 16 "EPAS_EAC_ERROR" 17 "CAMERA_FAILSAFES" 18 "CAMERA_CALIBRATION" 19 "RADAR_BLIND" 20 "RADAR_FAULT" 21 "ACC_CANCEL_GENERIC" 22 "ACC_CANCEL_SILENT" 23 "ACC_FAULT" 24 "ROAD_ESTIMATOR_HEALTH" 25 "CONTROLLER_REFERENCE" 26 "CONTROLLER_SOLVER" 27 "CONTROLLER_NOT_ALLOWED" 28 "THERMAL_ISSUE" 29 "MAP_HEALTH" 30 "CONTROLLER_STALE_REFERENCE" 31 "CONTROLLER_STALE_LOCALIZATION" 32 "CONTROLLER_BAD_REF_UPDATE" 33 "AEB" 34 "CONTROLLER_REF_TOO_SHORT" 35 "MISSION_PLANNER_NO_VISION_LANES_FOUND" 36 "GORE_INCURSION" 37 "REACHED_END_OF_NAV_STOP" 63 "REASON_MAX";
VAL_ 583 DAS_behaviorReport 0 "MISSION_PLANNER" 1 "VIEW_RANGE" 2 "CURVE_SPEED_ADAPTATION" 3 "RADAR_ONLY_BRAKING" 4 "KEEP_CALM" 5 "FLEET_SPEEDS" 6 "TRAFFIC_CONTROL_STOPPED_STATE" 7 "UNDERTAKE_ASSIST_KEEP_CALM" 8 "IN_LANE_VEHICLE" 9 "TARGET_LANE_VEHICLE" 10 "UNDERTAKE_VEHICLE" 11 "TRAFFIC_CONTROL" 12 "VISION_LANE_GEOMETRY" 13 "MAP_LANE_GEOMETRY" 14 "DRIVABLE_SPACE_VIOLATION" 15 "SLOWING_FOR_TARGET_LANE" 16 "VISION_SPEEDS" 17 "NAV_FLEET_SPEEDS" 18 "NAV_PATH_CSA" 19 "MERGE_VEHICLE_LEFT" 20 "MERGE_VEHICLE_RIGHT" 21 "CUTIN_VEHICLE_LEFT" 22 "CUTIN_VEHICLE_RIGHT";
VAL_ 583 DAS_cameraContext 0 "SURROUND" 1 "LEFT_LANE_CHANGE" 2 "RIGHT_LANE_CHANGE" 3 "FORWARD_FACING";
VAL_ 583 DAS_controllerHealth 0 "HEALTHY" 1 "DEGRADED" 2 "CRITICAL" 3 "SOLVER_FAILURE";
VAL_ 583 DAS_controllerRef 0 "HEALTHY" 1 "UNHEALTHY" 2 "STALE_REFERENCE" 3 "STALE_LOCALIZATION" 4 "BAD_REF_UPDATE" 5 "REF_TOO_SHORT" 6 "INDETERMINATE";
VAL_ 583 DAS_forkState 0 "INVALID" 1 "UNAVAILABLE_DISABLED" 2 "UNAVAILABLE_AP_INACTIVE" 3 "UNAVAILABLE_CONSTRUCTION" 4 "UNAVAILABLE_CONTROLLED_ACCESS_TOO_FAR" 5 "UNAVAILABLE_DON_INACTIVE" 6 "UNAVAILABLE_TOLL_BOOTH" 7 "UNAVAILABLE_OTHER" 8 "IDLE_BOTH_FORKS_AVAILABLE" 9 "IDLE_LEFT_FORK_AVAILABLE" 10 "IDLE_RIGHT_FORK_AVAILABLE" 11 "IDLE_NO_FORKS_AVAILABLE" 12 "ACTIVE_LEFT_NAV" 13 "ACTIVE_LEFT_USER" 14 "ACTIVE_RIGHT_NAV" 15 "ACTIVE_RIGHT_USER" 16 "FORK_COMPLETE" 17 "ABORT_CONTROL_INACTIVE" 18 "ABORT_BLINKER_CHANGE" 19 "ABORT_NOT_LEFT_LANE" 20 "ABORT_NOT_RIGHT_LANE" 21 "ABORT_DISALLOW" 22 "ABORT_OTHER" 23 "UNAVAILABLE_TIGHT_TURN_RADIUS" 24 "UNAVAILABLE_WEATHER";
VAL_ 583 DAS_laneChangeState 19 "LANE_CHANGE_ABORTING_ACC_AUTOSTEER_ACTIVATED" 26 "LANE_CHANGE_ABORTING_ALC_REQUEST_BEFORE_ULC_CONFIRM" 23 "LANE_CHANGE_ABORTING_BEHAVIOR_CHANGED" 22 "LANE_CHANGE_ABORTING_BELOW_MIN_SPEED" 14 "LANE_CHANGE_ABORTING_BLIND_SPOT_OCCUPIED" 12 "LANE_CHANGE_ABORTING_BLINKER" 32 "LANE_CHANGE_ABORTING_CONSTRUCTION_DETECTED" 43 "LANE_CHANGE_ABORTING_DESTINATION_LANE_UNSTABLE" 17 "LANE_CHANGE_ABORTING_FORK_AVAILABLE" 31 "LANE_CHANGE_ABORTING_GORE_POINT" 24 "LANE_CHANGE_ABORTING_HIGH_ALC_PROGRESS_ERROR" 11 "LANE_CHANGE_ABORTING_INACTIVE" 21 "LANE_CHANGE_ABORTING_INVALID_BEHAVIOR" 15 "LANE_CHANGE_ABORTING_INVALID_MODE" 16 "LANE_CHANGE_ABORTING_LINE_TYPE" 18 "LANE_CHANGE_ABORTING_LOST_VISION_POSE" 37 "LANE_CHANGE_ABORTING_NO_HANDS_ON" 40 "LANE_CHANGE_ABORTING_SNOOZED" 39 "LANE_CHANGE_ABORTING_SOURCE_AND_TARGET_LANES_MERGED" 34 "LANE_CHANGE_ABORTING_TIGHT_TURN_RADIUS" 13 "LANE_CHANGE_ABORTING_TIMEOUT" 33 "LANE_CHANGE_ABORTING_TOLL_BOOTH_DETECTED" 20 "LANE_CHANGE_ABORTING_ULC_BLINKER_TIMEOUT" 25 "LANE_CHANGE_ABORTING_ULC_CONFIRMATION_TIMEOUT" 35 "LANE_CHANGE_ABORTING_WEATHER" 10 "LANE_CHANGE_AVAILABLE_BOTH" 8 "LANE_CHANGE_AVAILABLE_LEFT_ONLY" 9 "LANE_CHANGE_AVAILABLE_RIGHT_ONLY" 29 "LANE_CHANGE_BLOCKED_LEFT" 30 "LANE_CHANGE_BLOCKED_RIGHT" 27 "LANE_CHANGE_IN_PROGRESS_LEFT" 28 "LANE_CHANGE_IN_PROGRESS_RIGHT" 42 "LANE_CHANGE_UNAVAILABLE_AUTOPILOT_ABORTING" 36 "LANE_CHANGE_UNAVAILABLE_BLINDSPOT_RESTRICTED" 41 "LANE_CHANGE_UNAVAILABLE_BLINKER_LATCHED" 0 "LANE_CHANGE_UNAVAILABLE_DISABLED" 5 "LANE_CHANGE_UNAVAILABLE_FORK_MODE" 4 "LANE_CHANGE_UNAVAILABLE_INACTIVE" 7 "LANE_CHANGE_UNAVAILABLE_INVALID_MODE" 3 "LANE_CHANGE_UNAVAILABLE_NO_LANES" 38 "LANE_CHANGE_UNAVAILABLE_NO_REAR_OBJECT" 1 "LANE_CHANGE_UNAVAILABLE_ROAD_NOT_APPROPRIATE" 2 "LANE_CHANGE_UNAVAILABLE_SPEED" 6 "LANE_CHANGE_UNAVAILABLE_ULTRASONICS_NOT_READY" 63 "LANE_CHANGE_UNKNOWN" ;
VAL_ 583 DAS_lastWatchdogCode 68 "ACTIVE_SAFETY_FAILED" 51 "AP_STATE_MACHINE_FAILED" 50 "ARBITER_FAILED" 57 "ATLAS_FAILED" 79 "BEV_GRAPH_FAILED" 77 "BRIDGE_FAILED" 67 "CAMERA_FAILED" 45 "CAN_RX_FAILED" 46 "CAN_TX_FAILED" 78 "CITY_STREETS_BEHAVIOR_FAILED" 74 "CLIP_LOGGER_FAILED" 52 "CONTROLLER_FAILED" 75 "DRIVABLE_SPACE_TRACKER_FAILED" 65 "DRIVER_MONITOR_FAILED" 70 "DYNAMICS_FAILED" 71 "FIELD_CALIBRATION_FAILED" 49 "GPS_FAILED" 73 "HW_MONITOR_FAILED" 61 "IMU_FAILED" 48 "INERTIATOR_FAILED" 63 "LANE_CHANGE_BEHAVIOR_FAILED" 43 "LEGACY_FAILED" 53 "LOCALIZER_FAILED" 66 "MAP_MANAGER_FAILED" 54 "MISSION_PLANNER_FAILED" 0 "NO_TASK_FAILED" 72 "PARKING_BEHAVIOR_FAILED" 55 "PERCEPTION_FAILED" 60 "RAIN_LIGHT_SENSING_FAILED" 56 "ROAD_ESTIMATOR_FAILED" 76 "SCHEDULER_FAILED" 41 "SNAPSHOT_FAILED" 59 "SNAPSHOT_TRIGGER_CLIENT_FAILED" 58 "STAY_IN_LANE_BEHAVIOR_FAILED" 40 "TELEMETRY_FAILED" 39 "TELEMETRY_PACKAGER_FAILED" 47 "TEMPERATURE_MONITOR_FAILED" 62 "UBX_LOG_FAILED" 69 "UI_SERVER_FAILED" 80 "ULTRASONICS_FAILED" 30 "UNKNOWN_TASK_FAILED" 42 "VISION_FAILED" 44 "WATCHDOG_FAILED" ;
VAL_ 583 DAS_mapAvailability 0 "NOT_AVAILABLE" 1 "AVAILABLE";
VAL_ 583 DAS_roadEstimator 0 "HEALTHY" 1 "UNSTABLE_MEASUREMENTS" 2 "DEGRADED" 3 "CRITICAL";
VAL_ 583 DAS_rqstedBehaviorStatus 0 "VALID" 1 "NO_SRC_POLYLANE" 2 "NO_DEST_POLYLANE" 3 "MAP_NOT_INITIALIZED" 4 "NO_SOURCE_LANE_ON_MAP" 5 "NO_TARGET_LANE_ON_MAP" 6 "BUILD_ARGUMENT_FAIL" 7 "BLOCKED_BY_ULTRASOUND_L" 8 "BLOCKED_BY_BLINDSPOT_CAMERA_L" 9 "BLOCKED_BY_BLINDSPOT_CAMERA_INVALID_L" 10 "BLOCKED_BY_ULTRASOUND_AND_CAMERA_L" 11 "BLOCKED_BY_LANE_TYPE_L" 12 "BLOCKED_BY_ULTRASOUND_R" 13 "BLOCKED_BY_BLINDSPOT_CAMERA_R" 14 "BLOCKED_BY_BLINDSPOT_CAMERA_INVALID_R" 15 "BLOCKED_BY_ULTRASOUND_AND_CAMERA_R" 16 "BLOCKED_BY_LANE_TYPE_R" 17 "ROAD_NOT_APPROPRIATE" 18 "OUT_OF_DATE" 19 "BAD_ORIGIN_UPDATE" 20 "BLOCKED_BY_SLOW_TARGET_L" 21 "BLOCKED_BY_SLOW_TARGET_R" 22 "INVALID_PLAN";
VAL_ 585 SCCM_highBeamStalkStatus 0 "IDLE" 1 "PULL" 2 "PUSH" 3 "SNA" ;
VAL_ 585 SCCM_turnIndicatorStalkStatus 5 "DOWN_0_5" 6 "DOWN_1" 7 "DOWN_1_5" 8 "DOWN_2" 0 "IDLE" 9 "SNA" 1 "UP_0_5" 2 "UP_1" 3 "UP_1_5" 4 "UP_2" ;
VAL_ 585 SCCM_washWipeButtonStatus 1 "1ST_DETENT" 2 "2ND_DETENT" 0 "NOT_PRESSED" 3 "SNA" ;
VAL_ 586 DAS_accSmartSpeedState 2 "ACTIVE_INTEGRATING" 1 "ACTIVE_OFFRAMP" 3 "ACTIVE_ONRAMP" 0 "NOT_ACTIVE" 5 "OFFRAMP_DELAY" 4 "SET_SPEED_SET_REQUESTED" 7 "SNA" ;
VAL_ 586 DAS_autosteerBottsDotsUsage 1 "AVAILABLE" 3 "BLACKLISTED" 2 "FUSED" 0 "REJECTED_UNAVAILABLE" ;
VAL_ 586 DAS_autosteerHPPUsage 1 "AVAILABLE" 3 "BLACKLISTED" 2 "FUSED" 0 "REJECTED_UNAVAILABLE" ;
VAL_ 586 DAS_autosteerHealthState 4 "HEALTH_ABORTING" 2 "HEALTH_DEGRADED" 5 "HEALTH_FAULT" 1 "HEALTH_NOMINAL" 3 "HEALTH_SEVERELY_DEGRADED" 0 "HEALTH_UNAVAILABLE" ;
VAL_ 586 DAS_autosteerModelUsage 1 "AVAILABLE" 3 "BLACKLISTED" 2 "FUSED" 0 "REJECTED_UNAVAILABLE" ;
VAL_ 586 DAS_autosteerNavigationUsage 1 "AVAILABLE" 3 "BLACKLISTED" 2 "FUSED" 0 "REJECTED_UNAVAILABLE" ;
VAL_ 586 DAS_autosteerVehiclesUsage 1 "AVAILABLE" 3 "BLACKLISTED" 2 "FUSED" 0 "REJECTED_UNAVAILABLE" ;
VAL_ 586 DAS_behaviorType 0 "DAS_BEHAVIOR_INVALID" 1 "DAS_BEHAVIOR_IN_LANE" 2 "DAS_BEHAVIOR_LANE_CHANGE_LEFT" 3 "DAS_BEHAVIOR_LANE_CHANGE_RIGHT" ;
VAL_ 586 DAS_lastAutosteerAbortReason 29 "UI_ABORT_REASON_ACC_CANCEL" 32 "UI_ABORT_REASON_AEB" 14 "UI_ABORT_REASON_APP_ME_STATE_NOT_VISION" 30 "UI_ABORT_REASON_CAMERA_FAILSAFES" 16 "UI_ABORT_REASON_CAM_MSG_MIA" 17 "UI_ABORT_REASON_CAM_WATCHDOG" 23 "UI_ABORT_REASON_CID_SWITCH_DISABLED" 21 "UI_ABORT_REASON_COMPONENT_MIA" 22 "UI_ABORT_REASON_CRUISE_FAULT" 24 "UI_ABORT_REASON_DRIVING_OFF_NAV" 20 "UI_ABORT_REASON_EPAS_EAC_DENIED" 28 "UI_ABORT_REASON_EPAS_ERROR_CODE" 26 "UI_ABORT_REASON_FOLLOWER_OUTPUT_INVALID" 0 "UI_ABORT_REASON_HM_LANE_VIEW_RANGE" 2 "UI_ABORT_REASON_HM_STEERING_ERROR" 1 "UI_ABORT_REASON_HM_VIRTUAL_LANE_NO_INPUTS" 15 "UI_ABORT_REASON_ME_MAIN_STATE_NOT_VISION" 31 "UI_ABORT_REASON_NO_ABORT" 27 "UI_ABORT_REASON_PLANNER_OUTPUT_INVALID" 33 "UI_ABORT_REASON_SEATBELT_UNBUCKLED" 19 "UI_ABORT_REASON_SIDE_COLLISION_IMMINENT" 18 "UI_ABORT_REASON_TRAILER_MODE" 34 "UI_ABORT_REASON_USER_OVERRIDE_STRIKEOUT" 25 "UI_ABORT_REASON_VEHICLE_SPEED_ABOVE_MAX" ;
VAL_ 586 DAS_lastLinePreferenceReason 1 "AGREEMENT_WITH_NEIGHBOR_LANES" 4 "AVOID_ONCOMING_LANES" 5 "COUNTRY_DRIVING_SIDE" 3 "NAVIGATION_BRANCH" 2 "NEIGHBOR_LANE_PROBABILIY" 15 "NONE" 0 "OTHER_LANE_DISAGREES_WITH_MODEL" ;
VAL_ 586 DAS_navAvailable 1 "DAS_NAV_AVAILABLE" 0 "DAS_NAV_UNAVAILABLE" ;
VAL_ 586 DAS_offsetSide 0 "NO_OFFSET" 3 "OFFSET_BOTH_OBJECTS" 2 "OFFSET_LEFT_OBJECT" 1 "OFFSET_RIGHT_OBJECT" ;
VAL_ 586 DAS_plannerState 0 "TP_EXTSTATE_DISABLED" 2 "TP_EXTSTATE_FOLLOW" 7 "TP_EXTSTATE_LANECHANGE_ABORT" 4 "TP_EXTSTATE_LANECHANGE_IN_PROGRESS" 3 "TP_EXTSTATE_LANECHANGE_REQUESTED" 6 "TP_EXTSTATE_LANECHANGE_WAIT_FOR_FWD_OBSTACLE" 5 "TP_EXTSTATE_LANECHANGE_WAIT_FOR_SIDE_OBSTACLE" 1 "TP_EXTSTATE_VL" ;
VAL_ 586 DAS_rearLeftVehDetectedCurrent 1 "VEHICLE_DETECTED" 0 "VEHICLE_NOT_DETECTED" ;
VAL_ 586 DAS_rearLeftVehDetectedTrip 1 "VEHICLE_DETECTED" 0 "VEHICLE_NOT_DETECTED" ;
VAL_ 586 DAS_rearRightVehDetectedTrip 1 "VEHICLE_DETECTED" 0 "VEHICLE_NOT_DETECTED" ;
VAL_ 586 DAS_rearVehDetectedThisCycle 1 "VEHICLE_DETECTED" 0 "VEHICLE_NOT_DETECTED" ;
VAL_ 586 DAS_roadSurfaceType 2 "ROAD_SURFACE_ENHANCED" 1 "ROAD_SURFACE_NORMAL" 0 "ROAD_SURFACE_SNA" ;
VAL_ 586 DAS_ulcInProgress 1 "ULC_ACTIVE" 0 "ULC_INACTIVE" ;
VAL_ 586 DAS_ulcType 1 "ULC_TYPE_NAV" 0 "ULC_TYPE_NONE" 2 "ULC_TYPE_SPEED" ;
VAL_ 590 PARK_pscVehSlotType 0 "LEFT_PARALLEL" 1 "LEFT_CROSS" 2 "RIGHT_PARALLEL" 3 "RIGHT_CROSS";
VAL_ 590 PARK_pscLeftParallelVehX 2046 "NO_SPACE" 2047 "SNA";
VAL_ 590 PARK_pscLeftParallelVehY 2046 "NO_SPACE" 2047 "SNA";
VAL_ 590 PARK_pscLeftParallelPsi 8190 "NO_SPACE" 8191 "SNA";
VAL_ 590 PARK_pscLeftParallelSizeX 254 "NO_SPACE" 255 "SNA";
VAL_ 590 PARK_pscLeftParallelSizeY 254 "NO_SPACE" 255 "SNA";
VAL_ 590 PARK_pscLeftCrossVehX 2046 "NO_SPACE" 2047 "SNA";
VAL_ 590 PARK_pscLeftCrossVehY 2046 "NO_SPACE" 2047 "SNA";
VAL_ 590 PARK_pscLeftCrossPsi 8190 "NO_SPACE" 8191 "SNA";
VAL_ 590 PARK_pscLeftCrossSizeX 254 "NO_SPACE" 255 "SNA";
VAL_ 590 PARK_pscLeftCrossSizeY 254 "NO_SPACE" 255 "SNA";
VAL_ 590 PARK_pscRightParallelVehX 2046 "NO_SPACE" 2047 "SNA";
VAL_ 590 PARK_pscRightParallelVehY 2046 "NO_SPACE" 2047 "SNA";
VAL_ 590 PARK_pscRightParallelPsi 8190 "NO_SPACE" 8191 "SNA";
VAL_ 590 PARK_pscRightParallelSizeX 254 "NO_SPACE" 255 "SNA";
VAL_ 590 PARK_pscRightParallelSizeY 254 "NO_SPACE" 255 "SNA";
VAL_ 590 PARK_pscRightCrossVehX 2046 "NO_SPACE" 2047 "SNA";
VAL_ 590 PARK_pscRightCrossVehY 2046 "NO_SPACE" 2047 "SNA";
VAL_ 590 PARK_pscRightCrossPsi 8190 "NO_SPACE" 8191 "SNA";
VAL_ 590 PARK_pscRightCrossSizeX 254 "NO_SPACE" 255 "SNA";
VAL_ 590 PARK_pscRightCrossSizeY 254 "NO_SPACE" 255 "SNA";
VAL_ 594 BMS_powerLimitsState 1 "POWER_CALCULATED_FOR_DRIVE" 0 "POWER_NOT_CALCULATED_FOR_DRIVE" ;
VAL_ 595 UI_ventPanelLeftLateralMode 0 "SINGLE" 1 "SPLIT";
VAL_ 595 UI_ventPanelRightLateralMode 0 "SINGLE" 1 "SPLIT";
VAL_ 598 DIR_state 3 "DI_STATE_ABORT" 4 "DI_STATE_ENABLE" 2 "DI_STATE_FAULT" 1 "DI_STATE_STANDBY" 0 "DI_STATE_UNAVAILABLE" ;
VAL_ 598 DIR_wasteState 1 "DI_WASTE_AVAILABLE" 2 "DI_WASTE_ON" 3 "DI_WASTE_STATIONARY" 0 "DI_WASTE_UNAVAILABLE" ;
VAL_ 599 DI_uiSpeed 511 "DI_UI_SPEED_SNA" ;
VAL_ 599 DI_uiSpeedHighSpeed 511 "DI_UI_HIGH_SPEED_SNA" ;
VAL_ 599 DI_uiSpeedUnits 1 "DI_SPEED_KPH" 0 "DI_SPEED_MPH" ;
VAL_ 599 DI_vehicleSpeed 4095 "SNA" ;
VAL_ 600 APB_watchdogState 0 "UNKNOWN" 1 "DEGRADED" 2 "CRITICAL" 3 "HEALTHY" 7 "SNA";
VAL_ 601 APP_watchdogState 0 "UNKNOWN" 1 "DEGRADED" 2 "CRITICAL" 3 "HEALTHY" 7 "SNA";
VAL_ 605 CP_UHF_controlState 3 "CP_UHF_CALIBRATE" 6 "CP_UHF_CHECK_RX" 1 "CP_UHF_CONFIG" 10 "CP_UHF_FAULT" 8 "CP_UHF_HANDLE_FOUND" 2 "CP_UHF_IDLE" 0 "CP_UHF_INIT" 4 "CP_UHF_PREPARE_RX" 7 "CP_UHF_READ_RXFIFO" 5 "CP_UHF_RX" 9 "CP_UHF_SLEEP" ;
VAL_ 605 CP_chargeCablePresent 0 "CABLE_NOT_PRESENT" 1 "CABLE_PRESENT" ;
VAL_ 605 CP_chargeCableState 2 "CHARGE_CABLE_CONNECTED" 1 "CHARGE_CABLE_NOT_CONNECTED" 0 "CHARGE_CABLE_UNKNOWN_SNA" ;
VAL_ 605 CP_coldWeatherMode 1 "CP_COLD_WEATHER_LATCH_MITIGATION" 0 "CP_COLD_WEATHER_NONE" ;
VAL_ 605 CP_doorControlState 5 "CP_doorClosing" 1 "CP_doorIdle" 0 "CP_doorInit" 2 "CP_doorOpenRequested" 3 "CP_doorOpening" 6 "CP_doorSenseClosed" 4 "CP_doorSenseOpen" ;
VAL_ 605 CP_faultLineSensed 0 "FAULT_LINE_CLEARED" 1 "FAULT_LINE_SET" ;
VAL_ 605 CP_inductiveDoorState 7 "CP_INDUCTIVE_DOOR_FAULT" 0 "CP_INDUCTIVE_DOOR_INIT" 1 "CP_INDUCTIVE_DOOR_INIT_FROM_CHARGE" 2 "CP_INDUCTIVE_DOOR_INIT_FROM_DRIVE" 4 "CP_INDUCTIVE_DOOR_NOT_PRESENT" 6 "CP_INDUCTIVE_DOOR_OFF_CHARGE" 5 "CP_INDUCTIVE_DOOR_OFF_DRIVE" 3 "CP_INDUCTIVE_DOOR_PRESENT" ;
VAL_ 605 CP_inductiveSensorState 7 "CP_INDUCTIVE_SENSOR_CONFIG" 5 "CP_INDUCTIVE_SENSOR_FAULT" 0 "CP_INDUCTIVE_SENSOR_INIT" 3 "CP_INDUCTIVE_SENSOR_PAUSE" 1 "CP_INDUCTIVE_SENSOR_POLL" 6 "CP_INDUCTIVE_SENSOR_RESET" 2 "CP_INDUCTIVE_SENSOR_SHUTDOWN" 4 "CP_INDUCTIVE_SENSOR_WAIT_FOR_INIT" ;
VAL_ 605 CP_latch2ControlState 2 "CP_latchDisengageRequested" 4 "CP_latchDisengaged" 3 "CP_latchDisengaging" 5 "CP_latchEngaging" 1 "CP_latchIdle" 0 "CP_latchInit" ;
VAL_ 605 CP_latch2State 3 "CP_LATCH_BLOCKING" 1 "CP_LATCH_DISENGAGED" 2 "CP_LATCH_ENGAGED" 0 "CP_LATCH_SNA" ;
VAL_ 605 CP_latchControlState 2 "CP_latchDisengageRequested" 4 "CP_latchDisengaged" 3 "CP_latchDisengaging" 5 "CP_latchEngaging" 1 "CP_latchIdle" 0 "CP_latchInit" ;
VAL_ 605 CP_latchState 3 "CP_LATCH_BLOCKING" 1 "CP_LATCH_DISENGAGED" 2 "CP_LATCH_ENGAGED" 0 "CP_LATCH_SNA" ;
VAL_ 605 CP_ledColor 7 "CP_LEDS_AMBER" 3 "CP_LEDS_BLUE" 9 "CP_LEDS_DEBUG" 6 "CP_LEDS_FLASHING_AMBER" 10 "CP_LEDS_FLASHING_BLUE" 5 "CP_LEDS_FLASHING_GREEN" 2 "CP_LEDS_GREEN" 0 "CP_LEDS_OFF" 8 "CP_LEDS_RAVE" 1 "CP_LEDS_RED" 4 "CP_LEDS_WHITE" ;
VAL_ 605 CP_type 1 "CP_TYPE_EURO_IEC" 2 "CP_TYPE_GB" 3 "CP_TYPE_IEC_CCS" 0 "CP_TYPE_US_TESLA" ;
VAL_ 606 PARK_pscEnvSlotType 0 "LEFT_PARALLEL" 1 "LEFT_CROSS" 2 "RIGHT_PARALLEL" 3 "RIGHT_CROSS";
VAL_ 606 PARK_pscLeftParallelObj1X 2046 "NO_SPACE" 2047 "SNA";
VAL_ 606 PARK_pscLeftParallelObj1Y 2046 "NO_SPACE" 2047 "SNA";
VAL_ 606 PARK_pscLeftParallelObj1Alpha 126 "NO_SPACE" 127 "SNA";
VAL_ 606 PARK_pscLeftParallelObj2Y 2046 "NO_SPACE" 2047 "SNA";
VAL_ 606 PARK_pscLeftParallelObj2X 2046 "NO_SPACE" 2047 "SNA";
VAL_ 606 PARK_pscLeftParallelObj2Alpha 126 "NO_SPACE" 127 "SNA";
VAL_ 606 PARK_pscLeftCrossObj1X 2046 "NO_SPACE" 2047 "SNA";
VAL_ 606 PARK_pscLeftCrossObj1Y 2046 "NO_SPACE" 2047 "SNA";
VAL_ 606 PARK_pscLeftCrossObj1Alpha 126 "NO_SPACE" 127 "SNA";
VAL_ 606 PARK_pscLeftCrossObj2Y 2046 "NO_SPACE" 2047 "SNA";
VAL_ 606 PARK_pscLeftCrossObj2X 2046 "NO_SPACE" 2047 "SNA";
VAL_ 606 PARK_pscLeftCrossObj2Alpha 126 "NO_SPACE" 127 "SNA";
VAL_ 606 PARK_pscRightParallelObj1X 2046 "NO_SPACE" 2047 "SNA";
VAL_ 606 PARK_pscRightParallelObj1Y 2046 "NO_SPACE" 2047 "SNA";
VAL_ 606 PARK_pscRightParallelObj1Alpha 126 "NO_SPACE" 127 "SNA";
VAL_ 606 PARK_pscRightParallelObj2Y 2046 "NO_SPACE" 2047 "SNA";
VAL_ 606 PARK_pscRightParallelObj2X 2046 "NO_SPACE" 2047 "SNA";
VAL_ 606 PARK_pscRightParallelObj2Alpha 126 "NO_SPACE" 127 "SNA";
VAL_ 606 PARK_pscRightCrossObj1X 2046 "NO_SPACE" 2047 "SNA";
VAL_ 606 PARK_pscRightCrossObj1Y 2046 "NO_SPACE" 2047 "SNA";
VAL_ 606 PARK_pscRightCrossObj1Alpha 126 "NO_SPACE" 127 "SNA";
VAL_ 606 PARK_pscRightCrossObj2Y 2046 "NO_SPACE" 2047 "SNA";
VAL_ 606 PARK_pscRightCrossObj2X 2046 "NO_SPACE" 2047 "SNA";
VAL_ 606 PARK_pscRightCrossObj2Alpha 126 "NO_SPACE" 127 "SNA";
VAL_ 609 VCFRONT_batterySMState 0 "INIT" 1 "CHARGE" 2 "DISCHARGE" 3 "STANDBY" 4 "RESISTANCE_ESTIMATION" 5 "OTA_STANDBY" 6 "DISCONNECTED_BATTERY_TEST" 7 "SHORTED_CELL_TEST" 8 "FAULT" 9 "RECOVERY" ;
VAL_ 609 VCFRONT_voltageProfile 0 "CHARGE" 1 "FLOAT" 2 "REDUCED_FLOAT" 3 "ALWAYS_CLOSED_CONTACTORS" ;
VAL_ 610 VCLEFT_steeringColumnLastRequest 0 "SNA" 1 "NONE" 2 "UP" 3 "DOWN" 4 "IN" 5 "OUT";
VAL_ 610 VCLEFT_steeringColumnSMState 0 "SNA" 1 "RECALL" 2 "CALIBRATE" 3 "MANUAL_CONTROL";
VAL_ 611 VCRIGHT_logging10HzIndex 0 "HVAC_ACTUATOR_TARGETS" 1 "HVAC_ACTUATOR_POSITIONS" 2 "HVAC_ACTUATOR_STATE" 3 "END";
VAL_ 611 VCRIGHT_evapPulldownBias 255 "SNA" ;
VAL_ 611 VCRIGHT_hvacLHBleedOperationMode 0 "NORMAL" 1 "CALIBRATION";
VAL_ 611 VCRIGHT_hvacRHBleedOperationMode 0 "NORMAL" 1 "CALIBRATION";
VAL_ 611 VCRIGHT_hvacLHVaneOperationMode 0 "NORMAL" 1 "CALIBRATION";
VAL_ 611 VCRIGHT_hvacRHVaneOperationMode 0 "NORMAL" 1 "CALIBRATION";
VAL_ 611 VCRIGHT_hvacUpperModeOpMode 0 "NORMAL" 1 "CALIBRATION";
VAL_ 611 VCRIGHT_hvacLowerModeOpMode 0 "NORMAL" 1 "CALIBRATION";
VAL_ 611 VCRIGHT_hvacIntakeOperationMode 0 "NORMAL" 1 "CALIBRATION";
VAL_ 611 VCRIGHT_hvacLHBleedActuatorState 0 "BRAKING" 1 "RUNNING" 2 "COASTING";
VAL_ 611 VCRIGHT_hvacRHBleedActuatorState 0 "BRAKING" 1 "RUNNING" 2 "COASTING";
VAL_ 611 VCRIGHT_hvacLHVaneActuatorState 0 "BRAKING" 1 "RUNNING" 2 "COASTING";
VAL_ 611 VCRIGHT_hvacRHVaneActuatorState 0 "BRAKING" 1 "RUNNING" 2 "COASTING";
VAL_ 611 VCRIGHT_hvacUpperModeActState 0 "BRAKING" 1 "RUNNING" 2 "COASTING";
VAL_ 611 VCRIGHT_hvacLowerModeActState 0 "BRAKING" 1 "RUNNING" 2 "COASTING";
VAL_ 611 VCRIGHT_hvacIntakeActuatorState 0 "BRAKING" 1 "RUNNING" 2 "COASTING";
VAL_ 615 DI_massConfidence 1 "MASS_CONFIDED" 0 "MASS_NOT_CONFIDED" ;
VAL_ 615 DI_relativeTireTreadDepth 32 "SNA" ;
VAL_ 615 DI_tireFitment 3 "FITMENT_SNA" 0 "FITMENT_SQUARE" 1 "FITMENT_STAGGERED" ;
VAL_ 615 DI_trailerDetected 1 "TRAILER_DETECTED" 0 "TRAILER_NOT_DETECTED" ;
VAL_ 616 DI_primaryUnitSiliconType 1 "IGBT" 0 "MOSFET" ;
VAL_ 626 VCLEFT_epbmDebugIndex 0 "STATES" 1 "TRANSITIONS";
VAL_ 626 VCLEFT_epbmCaliperState 0 "UNSAVED" 1 "UNKNOWN" 2 "REAPPLY" 3 "PARK" 4 "OPEN" 5 "SERVICE";
VAL_ 626 VCLEFT_summonFaultReason 0 "NONE" 1 "DI_MIA" 2 "DAS_MIA" 3 "ESP_MIA" 4 "EPBM_MIA" 5 "DI_FAULT" 6 "DI_APC_FAULT" 7 "DAS_FAULT" 8 "ESP_FAULT" 9 "VEH_CAN_FAULT" 10 "EAC_NOT_ALLOWED" 11 "EPBM_REQUEST" 12 "SPEED" 13 "EXTERNAL" 14 "PARK_MIA" 15 "PM_MIA" 16 "PM_REQUEST" 17 "OOC" 18 "MISMATCH" 19 "EPB_FAULT" 20 "DI_STATE_INVALID" 21 "PASSIVE_REQUEST" 22 "EPBREMOTE_MIA" 23 "REMOTE_SUMMON_FAULTED" 24 "LOCAL_UNIT_FAULTED" 25 "REMOTE_UNIT_FAULTED" 26 "START_IN_UNAVAILABLE" 27 "INVALID_REMOTE_STATE" 28 "REMOTE_DID_NOT_START";
VAL_ 626 VCLEFT_epbSummonState 0 "INIT" 1 "IDLE" 2 "ARMED" 3 "ACTIVE" 4 "COMPLETE" 5 "FAULT" 6 "UNAVAILABLE";
VAL_ 626 VCLEFT_epbmSummonState 0 "INIT" 1 "IDLE" 2 "ARMED" 3 "ACTIVE" 4 "COMPLETE" 5 "FAULT" 6 "UNAVAILABLE";
VAL_ 626 VCLEFT_epbmUnitStatus 0 "UNKNOWN" 1 "OPEN" 2 "DYNAMIC" 3 "PARK" 4 "START" 5 "SERVICE" 6 "WINCHMODE" 7 "WINCHMODE_RELEASING" 8 "PARKING" 9 "DYNAMIC_APPLYING" 10 "RELEASING" 11 "SERVICE_RELEASING" 12 "PARK_PENDING" 13 "WINCHMODE_PENDING" 14 "SUMMON" 15 "SUMMON_RELEASING" 16 "SUMMON_PARKING" 17 "EXTERNAL_DYNAMIC" 18 "RELEASING_FOR_EXTERNAL_PARK" 19 "EXTERNAL_PARKING" 20 "DYNAMIC_PARKING" 21 "COUNT";
VAL_ 626 VCLEFT_epbUnitStatus 0 "UNKNOWN" 1 "OPEN" 2 "DYNAMIC" 3 "PARK" 4 "START" 5 "SERVICE" 6 "WINCHMODE" 7 "WINCHMODE_RELEASING" 8 "PARKING" 9 "DYNAMIC_APPLYING" 10 "RELEASING" 11 "SERVICE_RELEASING" 12 "PARK_PENDING" 13 "WINCHMODE_PENDING" 14 "SUMMON" 15 "SUMMON_RELEASING" 16 "SUMMON_PARKING" 17 "EXTERNAL_DYNAMIC" 18 "RELEASING_FOR_EXTERNAL_PARK" 19 "EXTERNAL_PARKING" 20 "DYNAMIC_PARKING" 21 "COUNT";
VAL_ 626 VCLEFT_epbmFaultStatus 0 "NOMINAL" 1 "RETRY" 2 "FAULT" 3 "FAULT_IDLE";
VAL_ 626 VCLEFT_epbFaultStatus 0 "NOMINAL" 1 "RETRY" 2 "FAULT" 3 "FAULT_IDLE";
VAL_ 626 VCLEFT_cdpEnumDummy 0 "IDLE" 1 "VALID" 2 "INVALID";
VAL_ 627 UI_displayBrightnessLevel 255 "SNA" ;
VAL_ 627 UI_domeLightSwitch 2 "DOME_LIGHT_SWITCH_AUTO" 0 "DOME_LIGHT_SWITCH_OFF" 1 "DOME_LIGHT_SWITCH_ON" ;
VAL_ 627 UI_driveStateRequest 0 "DRIVE_STATE_REQ_IDLE" 1 "DRIVE_STATE_REQ_START" ;
VAL_ 627 UI_frontLeftSeatHeatReq 1 "HEATER_REQUEST_LEVEL1" 2 "HEATER_REQUEST_LEVEL2" 3 "HEATER_REQUEST_LEVEL3" 0 "HEATER_REQUEST_OFF" ;
VAL_ 627 UI_frontRightSeatHeatReq 1 "HEATER_REQUEST_LEVEL1" 2 "HEATER_REQUEST_LEVEL2" 3 "HEATER_REQUEST_LEVEL3" 0 "HEATER_REQUEST_OFF" ;
VAL_ 627 UI_lockRequest 0 "UI_LOCK_REQUEST_IDLE" 1 "UI_LOCK_REQUEST_LOCK" 4 "UI_LOCK_REQUEST_REMOTE_LOCK" 3 "UI_LOCK_REQUEST_REMOTE_UNLOCK" 7 "UI_LOCK_REQUEST_SNA" 2 "UI_LOCK_REQUEST_UNLOCK" ;
VAL_ 627 UI_mirrorFoldRequest 0 "MIRROR_FOLD_REQUEST_IDLE" 2 "MIRROR_FOLD_REQUEST_PRESENT" 1 "MIRROR_FOLD_REQUEST_RETRACT" 3 "MIRROR_FOLD_REQUEST_SNA" ;
VAL_ 627 UI_rearCenterSeatHeatReq 1 "HEATER_REQUEST_LEVEL1" 2 "HEATER_REQUEST_LEVEL2" 3 "HEATER_REQUEST_LEVEL3" 0 "HEATER_REQUEST_OFF" ;
VAL_ 627 UI_rearLeftSeatHeatReq 1 "HEATER_REQUEST_LEVEL1" 2 "HEATER_REQUEST_LEVEL2" 3 "HEATER_REQUEST_LEVEL3" 0 "HEATER_REQUEST_OFF" ;
VAL_ 627 UI_rearRightSeatHeatReq 1 "HEATER_REQUEST_LEVEL1" 2 "HEATER_REQUEST_LEVEL2" 3 "HEATER_REQUEST_LEVEL3" 0 "HEATER_REQUEST_OFF" ;
VAL_ 627 UI_remoteClosureRequest 2 "UI_REMOTE_CLOSURE_REQUEST_FRONT_TRUNK_MOVE" 0 "UI_REMOTE_CLOSURE_REQUEST_IDLE" 1 "UI_REMOTE_CLOSURE_REQUEST_REAR_TRUNK_MOVE" 3 "UI_REMOTE_CLOSURE_REQUEST_SNA" ;
VAL_ 627 UI_remoteStartRequest 0 "UI_REMOTE_START_REQUEST_IDLE" 4 "UI_REMOTE_START_REQUEST_SNA" 1 "UI_REMOTE_START_REQUEST_START" ;
VAL_ 627 UI_steeringBacklightEnabled 0 "STEERING_BACKLIGHT_DISABLED" 1 "STEERING_BACKLIGHT_ENABLED" ;
VAL_ 627 UI_steeringButtonMode 4 "STEERING_BUTTON_MODE_HEADLIGHT_LEFT" 5 "STEERING_BUTTON_MODE_HEADLIGHT_RIGHT" 2 "STEERING_BUTTON_MODE_MIRROR_LEFT" 3 "STEERING_BUTTON_MODE_MIRROR_RIGHT" 0 "STEERING_BUTTON_MODE_OFF" 1 "STEERING_BUTTON_MODE_STEERING_COLUMN_ADJ" ;
VAL_ 627 UI_wiperMode 2 "WIPER_MODE_NORMAL" 3 "WIPER_MODE_PARK" 1 "WIPER_MODE_SERVICE" 0 "WIPER_MODE_SNA" ;
VAL_ 627 UI_wiperRequest 2 "WIPER_REQUEST_AUTO" 6 "WIPER_REQUEST_FAST_CONTINUOUS" 4 "WIPER_REQUEST_FAST_INTERMITTENT" 1 "WIPER_REQUEST_OFF" 5 "WIPER_REQUEST_SLOW_CONTINUOUS" 3 "WIPER_REQUEST_SLOW_INTERMITTENT" 0 "WIPER_REQUEST_SNA" ;
VAL_ 632 UI_roadCurvHealth 0 "UNAVAILABLE" 1 "DEGRADED" 2 "AVAILABLE" 3 "DATABASE";
VAL_ 633 DIR_hvilStatus 2 "CLOSED" 0 "DISABLED" 1 "OPEN" 3 "SNA" ;
VAL_ 634 DIF_hvilStatus 2 "CLOSED" 0 "DISABLED" 1 "OPEN" 3 "SNA" ;
VAL_ 642 VCLEFT_blowerIndex 0 "HVAC_FEEDBACK_SIGNALS" 1 "HVAC_VARS" ;
VAL_ 642 VCLEFT_hvacBlowerCBCCtrlState 4 "COUNT" 0 "ERROR" 1 "IDLE" 2 "OFFLINE" 3 "ONLINE" ;
VAL_ 642 VCLEFT_hvacBlowerCBCEstState 14 "COUNT" 0 "ERROR" 1 "IDLE" 5 "IDRATED" 10 "INDUCTANCE_EST" 9 "LOCKROTOR" 12 "MOTOR_IDENTIFIED" 13 "ONLINE" 8 "RAMPDOWN" 4 "RAMPUP" 7 "RATEDFLUX" 6 "RATEDFLUX_OL" 11 "ROTOR_RESISTANCE" 2 "ROVERL" 3 "RS" ;
VAL_ 642 VCLEFT_hvacBlowerFETTemp 127 "SNA" ;
VAL_ 642 VCLEFT_hvacBlowerIPhase0 255 "SNA" ;
VAL_ 642 VCLEFT_hvacBlowerIPhase1 255 "SNA" ;
VAL_ 642 VCLEFT_hvacBlowerIPhase2 255 "SNA" ;
VAL_ 642 VCLEFT_hvacBlowerITerm 127 "SNA" ;
VAL_ 642 VCLEFT_hvacBlowerOutputDuty 127 "SNA" ;
VAL_ 642 VCLEFT_hvacBlowerRPMTarget 1023 "SNA" ;
VAL_ 642 VCLEFT_hvacBlowerRs 255 "SNA" ;
VAL_ 642 VCLEFT_hvacBlowerTorque 1023 "SNA" ;
VAL_ 642 VCLEFT_hvacBlower_IO_CBC_Status 0 "IDLE" 1 "RX" ;
VAL_ 645 UI_driverProfileRecallIndex 0 "SNA" 1 "1" 2 "2" 3 "3" 4 "4" 5 "5";
VAL_ 645 UI_leftBackrestSwitchUp 0 "SNA" 1 "OFF" 2 "ON" 3 "FAULT";
VAL_ 645 UI_leftBackrestSwitchDown 0 "SNA" 1 "OFF" 2 "ON" 3 "FAULT";
VAL_ 645 UI_leftLiftSwitchUp 0 "SNA" 1 "OFF" 2 "ON" 3 "FAULT";
VAL_ 645 UI_leftLiftSwitchDown 0 "SNA" 1 "OFF" 2 "ON" 3 "FAULT";
VAL_ 645 UI_rightBackrestSwitchUp 0 "SNA" 1 "OFF" 2 "ON" 3 "FAULT";
VAL_ 645 UI_rightBackrestSwitchDown 0 "SNA" 1 "OFF" 2 "ON" 3 "FAULT";
VAL_ 645 UI_rightLiftSwitchUp 0 "SNA" 1 "OFF" 2 "ON" 3 "FAULT";
VAL_ 645 UI_rightLiftSwitchDown 0 "SNA" 1 "OFF" 2 "ON" 3 "FAULT";
VAL_ 646 DI_aebState 0 "UNAVAILABLE" 1 "STANDBY" 2 "ENABLED" 3 "STANDSTILL" 4 "FAULT" 7 "SNA";
VAL_ 646 DI_autoparkState 0 "UNAVAILABLE" 1 "STANDBY" 2 "STARTED" 3 "ACTIVE" 4 "COMPLETE" 5 "PAUSED" 6 "ABORTED" 7 "RESUMED" 8 "UNPARK_COMPLETE" 9 "SELFPARK_STARTED" 15 "SNA";
VAL_ 646 DI_autopilotRequest 0 "IDLE" 1 "ACTIVATE";
VAL_ 646 DI_cruiseSetSpeedUnits 0 "MPH" 1 "KPH";
VAL_ 646 DI_cruiseState 0 "UNAVAILABLE" 1 "STANDBY" 2 "ENABLED" 3 "STANDSTILL" 4 "OVERRIDE" 5 "FAULT" 6 "PRE_FAULT" 7 "PRE_CANCEL";
VAL_ 646 DI_parkBrakeState 0 "UNAVAILABLE" 1 "RELEASED" 2 "REQUESTED" 3 "APPLIED" 4 "FAULTED" 5 "PANIC_EPB" 6 "PANIC_SKID" 7 "RELEASING" 15 "SNA";
VAL_ 646 DI_pmmStatus 0 "INACTIVE" 1 "ACTIVE" 2 "LOGGING_ACTIVE" 3 "SNA";
VAL_ 646 DI_rollPreventionState 0 "UNAVAILABLE" 1 "STANDBY" 2 "READY" 3 "BUILD" 4 "HOLD" 5 "PARK" 6 "FAULT" 7 "INIT";
VAL_ 646 DI_vehicleHoldState 0 "UNAVAILABLE" 1 "STANDBY" 2 "BLEND_IN" 3 "STANDSTILL" 4 "BLEND_OUT" 5 "PARK" 6 "FAULT" 7 "INIT";
VAL_ 648 EPBLesmCaliperRequest288 3 "disengaging" 2 "engaging" 1 "idle" ;
VAL_ 648 EPBLesmOperationTrigger288 22 "SuperPark" 6 "Released" 1 "ParkEngaged" ;
VAL_ 648 EPBLunitStatus288 10 "Disengaging" 8 "Engaging" 3 "ParkEngaged" 1 "DriveReleased" ;
VAL_ 658 BattBeginningOfLifeEnergy292 1023 "SNA" ;
VAL_ 658 BMS_battTempPct 255 "SNA" ;
VAL_ 659 UI_accOvertakeEnable 0 "ACC_OVERTAKE_OFF" 1 "ACC_OVERTAKE_ON" 3 "SNA" ;
VAL_ 659 UI_aebEnable 0 "AEB_OFF" 1 "AEB_ON" 3 "SNA" ;
VAL_ 659 UI_aesEnable 0 "AES_OFF" 1 "AES_ON" 3 "SNA" ;
VAL_ 659 UI_ahlbEnable 0 "AHLB_OFF" 1 "AHLB_ON" 3 "SNA" ;
VAL_ 659 UI_autoLaneChangeEnable 0 "OFF" 1 "ON" 3 "SNA" ;
VAL_ 659 UI_autoParkRequest 7 "ABORT" 8 "COMPLETE" 0 "NONE" 5 "PARALLEL_PULL_OUT_TO_LEFT" 6 "PARALLEL_PULL_OUT_TO_RIGHT" 2 "PARK_LEFT_CROSS" 1 "PARK_LEFT_PARALLEL" 4 "PARK_RIGHT_CROSS" 3 "PARK_RIGHT_PARALLEL" 10 "PAUSE" 11 "RESUME" 9 "SEARCH" 15 "SNA" ;
VAL_ 659 UI_bsdEnable 0 "BSD_OFF" 1 "BSD_ON" 3 "SNA" ;
VAL_ 659 UI_distanceUnits 0 "DISTANCEUNITS_KM" 1 "DISTANCEUNITS_MILES" ;
VAL_ 659 UI_fcwEnable 0 "FCW_OFF" 1 "FCW_ON" 3 "SNA" ;
VAL_ 659 UI_fcwSensitivity 1 "AEB_SENSITIVITY_AVERAGE" 0 "AEB_SENSITIVITY_EARLY" 2 "AEB_SENSITIVITY_LATE" 3 "SNA" ;
VAL_ 659 UI_latControlEnable 0 "LATERAL_CONTROL_OFF" 1 "LATERAL_CONTROL_ON" 3 "LATERAL_CONTROL_SNA" 2 "LATERAL_CONTROL_UNAVAILABLE" ;
VAL_ 659 UI_ldwEnable 1 "LDW_TRIGGERS_HAPTIC" 0 "NO_HAPTIC" 3 "SNA" ;
VAL_ 659 UI_parkBrakeRequest 0 "PARK_BRAKE_REQUEST_IDLE" 1 "PARK_BRAKE_REQUEST_PRESSED" 3 "PARK_BRAKE_REQUEST_SNA" ;
VAL_ 659 UI_pedalSafetyEnable 0 "PEDAL_SAFETY_OFF" 1 "PEDAL_SAFETY_ON" 3 "SNA" ;
VAL_ 659 UI_redLightStopSignEnable 0 "RLSSW_OFF" 1 "RLSSW_ON" 3 "SNA" ;
VAL_ 659 UI_selfParkTune 15 "SNA" ;
VAL_ 659 UI_steeringTuneRequest 0 "STEERING_TUNE_COMFORT" 2 "STEERING_TUNE_SPORT" 1 "STEERING_TUNE_STANDARD" ;
VAL_ 659 UI_tractionControlMode 2 "TC_DEV_MODE_1_SELECTED" 3 "TC_DEV_MODE_2_SELECTED" 5 "TC_DYNO_MODE_SELECTED" 0 "TC_NORMAL_SELECTED" 6 "TC_OFFROAD_ASSIST_SELECTED" 4 "TC_ROLLS_MODE_SELECTED" 1 "TC_SLIP_START_SELECTED" ;
VAL_ 659 UI_trailerMode 0 "TRAILER_MODE_OFF" 1 "TRAILER_MODE_ON" ;
VAL_ 659 UI_winchModeRequest 1 "WINCH_MODE_ENTER" 2 "WINCH_MODE_EXIT" 0 "WINCH_MODE_IDLE" ;
VAL_ 659 UI_zeroSpeedConfirmed 0 "ZERO_SPEED_CANCELED" 1 "ZERO_SPEED_CONFIRMED" 3 "ZERO_SPEED_SNA" 2 "ZERO_SPEED_UNUSED" ;
VAL_ 676 PCS_ambientTemp 1023 "TEMPERATURE_SNA";
VAL_ 676 PCS_chgPhATemp 1023 "TEMPERATURE_SNA";
VAL_ 676 PCS_chgPhBTemp 1023 "TEMPERATURE_SNA";
VAL_ 676 PCS_chgPhCTemp 1023 "TEMPERATURE_SNA";
VAL_ 676 PCS_dcdcTemp 1023 "TEMPERATURE_SNA";
VAL_ 680 CMPD_state 3 "CMPD_STATE_FAULT" 4 "CMPD_STATE_IDLE" 0 "CMPD_STATE_INIT" 1 "CMPD_STATE_RUNNING" 15 "CMPD_STATE_SNA" 2 "CMPD_STATE_STANDBY" ;
VAL_ 680 CMPD_wasteHeatState 1 "CMPD_WASTE_HEAT_STATE_ACTIVE" 2 "CMPD_WASTE_HEAT_STATE_NOT_AVAILABLE" 0 "CMPD_WASTE_HEAT_STATE_OFF" 3 "CMPD_WASTE_HEAT_STATE_UNUSED" ;
VAL_ 681 EPBL_systemStatus 3 "EPB_VEHICLE_STATUS_DYNAMIC" 6 "EPB_VEHICLE_STATUS_FAULT" 7 "EPB_VEHICLE_STATUS_FAULT_SECURE" 8 "EPB_VEHICLE_STATUS_MISMATCH" 2 "EPB_VEHICLE_STATUS_PARKED" 4 "EPB_VEHICLE_STATUS_PARKING" 1 "EPB_VEHICLE_STATUS_RELEASED" 5 "EPB_VEHICLE_STATUS_RELEASING" 0 "EPB_VEHICLE_STATUS_UNKNOWN" ;
VAL_ 691 VCRIGHT_logging1HzIndex 0 "HVAC_TEMP_SENSORS_AND_ESTIMATES_1" 1 "HVAC_TEMP_SENSORS_AND_ESTIMATES_2" 2 "HVAC_HUMIDITY_HEATER" 3 "HVAC_STATUS_AIRFLOW" 4 "HVAC_COMFORT_SOLAR" 5 "HEATER_AND_DUCT_TARGETS" 6 "HVAC_ACTUATOR_VOLTAGES" 7 "HVAC_ACTUATOR_ENDSTOP" 8 "HVAC_ACTUATOR_ZEROSTOP" 9 "HVAC_MISCELLANEOUS_1" 10 "HVAC_MISCELLANEOUS_2" 11 "END";
VAL_ 691 VCRIGHT_tempIncarCabinProbe 255 "SNA";
VAL_ 691 VCRIGHT_tempIncarCabinMid 250 "SNA";
VAL_ 691 VCRIGHT_tempIncarCabinDeep 255 "SNA";
VAL_ 691 VCRIGHT_cabinTempInteriorL2 240 "SNA";
VAL_ 691 VCRIGHT_cabinTempInteriorSunnyL2 240 "SNA";
VAL_ 691 VCRIGHT_cabinTempGlassRoof 255 "SNA";
VAL_ 691 VCRIGHT_cabinTempWindshield 255 "SNA";
VAL_ 691 VCRIGHT_cabinTempInterior 240 "SNA";
VAL_ 691 VCRIGHT_cabinTempInteriorSunny 240 "SNA";
VAL_ 691 VCRIGHT_cabinTempSideGlassLeft 255 "SNA";
VAL_ 691 VCRIGHT_cabinTempSideGlassRight 255 "SNA";
VAL_ 691 VCRIGHT_cabinTempBreathLevel 255 "SNA";
VAL_ 691 VCRIGHT_hvacAutoTransitionReason 0 "NONE" 1 "HUMIDITY_HIGH" 2 "HUMIDITY_MODERATE" 3 "HUMIDITY_LOW" 4 "TEMP_TARGET_BELOW_THRESHOLD" 5 "TEMP_TARGET_ABOVE_THRESHOLD" 6 "EXCESS_OCCUPANT_CONVECTION" 7 "OCCUPANT_CONVECTION_REQUIREMENT" 8 "TEMP_TARGET_LOW" 9 "DUCTS_COLD" 10 "BI_LEVEL_LANDING" 11 "DEFOG_OVERRIDE" 12 "SET_TEMP_LO" 13 "SET_TEMP_HI" 14 "CABIN_PURGE" 15 "EVAP_DRYING" 16 "HVAC_OFF" 17 "END";
VAL_ 691 VCRIGHT_hvacAirFlowModeRow1 0 "NONE" 1 "FLOOR" 2 "PANEL" 3 "PANEL_FLOOR" 4 "DEFROST" 5 "DEFROST_FLOOR" 6 "DEFROST_PANEL" 7 "DEFROST_PANEL_FLOOR";
VAL_ 691 VCRIGHT_hvacAirFlowModeRow2 0 "NONE" 1 "FLOOR" 2 "PANEL" 3 "PANEL_FLOOR" 4 "DEFROST" 5 "DEFROST_FLOOR" 6 "DEFROST_PANEL" 7 "DEFROST_PANEL_FLOOR";
VAL_ 691 VCRIGHT_hvacAirflowReason 0 "HVAC_OFF" 1 "MANUAL_FAN_SPEED" 2 "UI_SHORTCUT" 3 "CABIN_TEMPERATURE_CONTROL" 4 "MINIMUM_AUTO_AIRFLOW" 5 "STRATIFICATION_GLASS_ROOF" 6 "STRATIFICATION_INTERIOR_SURFACES" 7 "OCCUPANT_CONVECTION_REQUIREMENT" 8 "COLD_DUCT_LOCKOUT" 9 "CABIN_PURGE" 10 "CABIN_OVERHEAT_PROTECT" 11 "SCREEN_PROTECTION" 12 "EVAP_DRYING" 13 "NONE";
VAL_ 691 VCRIGHT_convectionTargetLeft 255 "SNA";
VAL_ 691 VCRIGHT_convectionTargetRight 255 "SNA";
VAL_ 691 VCRIGHT_convectionDeliveredLeft 255 "SNA";
VAL_ 691 VCRIGHT_convectionDeliveredRight 255 "SNA";
VAL_ 691 VCRIGHT_solarLoadRightOccupant 255 "SNA";
VAL_ 691 VCRIGHT_solarLoadLeftOccupant 255 "SNA";
VAL_ 691 VCRIGHT_solarLoadOnVehicle 255 "SNA";
VAL_ 691 VCRIGHT_solarLoadOnVehFiltered 255 "SNA";
VAL_ 691 VCRIGHT_cabinTempInteriorL3 240 "SNA";
VAL_ 691 VCRIGHT_cabinTempInteriorSunnyL3 240 "SNA";
VAL_ 691 VCRIGHT_cabinTempTopPadAir 240 "SNA";
VAL_ 691 VCRIGHT_tempDuctModeledLeft 511 "SNA";
VAL_ 691 VCRIGHT_tempDuctModeledRight 511 "SNA";
VAL_ 691 VCRIGHT_tempHtrSurfaceModeledL 511 "SNA";
VAL_ 691 VCRIGHT_tempHtrSurfaceModeledR 511 "SNA";

CM_ BO_ 12 "source: joshwardell/model3dbc (Model3CAN.dbc)";
CM_ BO_ 17 "source: onyx-m2/onyx-m2-dbc (tesla_model3.dbc)";
CM_ BO_ 22 "source: joshwardell/model3dbc (Model3CAN.dbc)";
CM_ BO_ 60 "source: onyx-m2/onyx-m2-dbc (tesla_model3.dbc)";
CM_ BO_ 62 "source: onyx-m2/onyx-m2-dbc (tesla_model3.dbc)";
CM_ BO_ 79 "source: joshwardell/model3dbc (Model3CAN.dbc)";
CM_ BO_ 130 "source: joshwardell/model3dbc (Model3CAN.dbc)";
CM_ BO_ 139 "source: onyx-m2/onyx-m2-dbc (tesla_model3.dbc)";
CM_ BO_ 257 "source: joshwardell/model3dbc (Model3CAN.dbc)";
CM_ BO_ 258 "source: joshwardell/model3dbc (Model3CAN.dbc)";
CM_ BO_ 259 "source: joshwardell/model3dbc (Model3CAN.dbc)";
CM_ BO_ 264 "source: joshwardell/model3dbc (Model3CAN.dbc)";
CM_ BO_ 273 "source: joshwardell/model3dbc (Model3CAN.dbc)";
CM_ BO_ 274 "source: onyx-m2/onyx-m2-dbc (tesla_model3.dbc)";
CM_ BO_ 275 "source: joshwardell/model3dbc (Model3CAN.dbc)";
CM_ BO_ 276 "source: onyx-m2/onyx-m2-dbc (tesla_model3.dbc)";
CM_ BO_ 278 "source: joshwardell/model3dbc (Model3CAN.dbc)";
CM_ BO_ 280 "source: joshwardell/model3dbc (Model3CAN.dbc)";
CM_ BO_ 281 "source: joshwardell/model3dbc (Model3CAN.dbc)";
CM_ BO_ 289 "source: onyx-m2/onyx-m2-dbc (tesla_model3.dbc)";
CM_ BO_ 290 "source: joshwardell/model3dbc (Model3CAN.dbc)";
CM_ BO_ 291 "source: joshwardell/model3dbc (Model3CAN.dbc)";
CM_ BO_ 294 "source: joshwardell/model3dbc (Model3CAN.dbc)";
CM_ BO_ 295 "source: joshwardell/model3dbc (Model3CAN.dbc)";
CM_ BO_ 297 "source: joshwardell/model3dbc (Model3CAN.dbc)";
CM_ BO_ 298 "source: joshwardell/model3dbc (Model3CAN.dbc)";
CM_ BO_ 306 "source: joshwardell/model3dbc (Model3CAN.dbc)";
CM_ BO_ 307 "source: onyx-m2/onyx-m2-dbc (tesla_model3.dbc)";
CM_ BO_ 317 "source: joshwardell/model3dbc (Model3CAN.dbc)";
CM_ BO_ 322 "source: joshwardell/model3dbc (Model3CAN.dbc)";
CM_ BO_ 325 "source: joshwardell/model3dbc (Model3CAN.dbc)";
CM_ BO_ 340 "source: joshwardell/model3dbc (Model3CAN.dbc)";
CM_ BO_ 341 "source: joshwardell/model3dbc (Model3CAN.dbc)";
CM_ BO_ 371 "source: onyx-m2/onyx-m2-dbc (tesla_model3.dbc)";
CM_ BO_ 373 "source: joshwardell/model3dbc (Model3CAN.dbc)";
CM_ BO_ 389 "source: joshwardell/model3dbc (Model3CAN.dbc)";
CM_ BO_ 390 "source: joshwardell/model3dbc (Model3CAN.dbc)";
CM_ BO_ 392 "source: onyx-m2/onyx-m2-dbc (tesla_model3.dbc)";
CM_ BO_ 421 "source: joshwardell/model3dbc (Model3CAN.dbc)";
CM_ BO_ 435 "source: onyx-m2/onyx-m2-dbc (tesla_model3.dbc)";
CM_ BO_ 463 "source: talas9/tesla_can_signals (ModelY_ETH.compact.json)";
CM_ BO_ 468 "source: joshwardell/model3dbc (Model3CAN.dbc)";
CM_ BO_ 469 "source: joshwardell/model3dbc (Model3CAN.dbc)";
CM_ BO_ 470 "source: joshwardell/model3dbc (Model3CAN.dbc)";
CM_ BO_ 472 "source: joshwardell/model3dbc (Model3CAN.dbc)";
CM_ BO_ 473 "source: onyx-m2/onyx-m2-dbc (tesla_model3.dbc)";
CM_ BO_ 499 "source: onyx-m2/onyx-m2-dbc (tesla_model3.dbc)";
CM_ BO_ 505 "source: onyx-m2/onyx-m2-dbc (tesla_model3.dbc)";
CM_ BO_ 513 "source: joshwardell/model3dbc (Model3CAN.dbc)";
CM_ BO_ 516 "source: joshwardell/model3dbc (Model3CAN.dbc)";
CM_ BO_ 522 "source: joshwardell/model3dbc (Model3CAN.dbc)";
CM_ BO_ 523 "source: onyx-m2/onyx-m2-dbc (tesla_model3.dbc)";
CM_ BO_ 524 "source: joshwardell/model3dbc (Model3CAN.dbc)";
CM_ BO_ 525 "source: onyx-m2/onyx-m2-dbc (tesla_model3.dbc)";
CM_ BO_ 526 "source: joshwardell/model3dbc (Model3CAN.dbc)";
CM_ BO_ 528 "source: talas9/tesla_can_signals (ModelY_ETH.compact.json)";
CM_ BO_ 529 "source: talas9/tesla_can_signals (ModelY_ETH.compact.json)";
CM_ BO_ 530 "source: joshwardell/model3dbc (Model3CAN.dbc)";
CM_ BO_ 531 "source: onyx-m2/onyx-m2-dbc (tesla_model3.dbc)";
CM_ BO_ 532 "source: joshwardell/model3dbc (Model3CAN.dbc)";
CM_ BO_ 533 "source: joshwardell/model3dbc (Model3CAN.dbc)";
CM_ BO_ 535 "source: joshwardell/model3dbc (Model3CAN.dbc)";
CM_ BO_ 536 "source: onyx-m2/onyx-m2-dbc (tesla_model3.dbc)";
CM_ BO_ 537 "source: joshwardell/model3dbc (Model3CAN.dbc)";
CM_ BO_ 541 "source: joshwardell/model3dbc (Model3CAN.dbc)";
CM_ BO_ 542 "source: onyx-m2/onyx-m2-dbc (tesla_model3.dbc)";
CM_ BO_ 545 "source: joshwardell/model3dbc (Model3CAN.dbc)";
CM_ BO_ 548 "source: joshwardell/model3dbc (Model3CAN.dbc)";
CM_ BO_ 549 "source: joshwardell/model3dbc (Model3CAN.dbc)";
CM_ BO_ 551 "source: joshwardell/model3dbc (Model3CAN.dbc)";
CM_ BO_ 552 "source: joshwardell/model3dbc (Model3CAN.dbc)";
CM_ BO_ 553 "source: joshwardell/model3dbc (Model3CAN.dbc)";
CM_ BO_ 554 "source: joshwardell/model3dbc (Model3CAN.dbc)";
CM_ BO_ 558 "source: joshwardell/model3dbc (Model3CAN.dbc)";
CM_ BO_ 562 "source: joshwardell/model3dbc (Model3CAN.dbc)";
CM_ BO_ 568 "source: joshwardell/model3dbc (Model3CAN.dbc)";
CM_ BO_ 569 "source: joshwardell/model3dbc (Model3CAN.dbc)";
CM_ BO_ 570 "source: talas9/tesla_can_signals (ModelY_ETH.compact.json)";
CM_ BO_ 573 "source: joshwardell/model3dbc (Model3CAN.dbc)";
CM_ BO_ 577 "source: joshwardell/model3dbc (Model3CAN.dbc)";
CM_ BO_ 578 "source: joshwardell/model3dbc (Model3CAN.dbc)";
CM_ BO_ 579 "source: joshwardell/model3dbc (Model3CAN.dbc)";
CM_ BO_ 580 "source: joshwardell/model3dbc (Model3CAN.dbc)";
CM_ BO_ 583 "source: onyx-m2/onyx-m2-dbc (tesla_model3.dbc)";
CM_ BO_ 585 "source: joshwardell/model3dbc (Model3CAN.dbc)";
CM_ BO_ 586 "source: joshwardell/model3dbc (Model3CAN.dbc)";
CM_ BO_ 590 "source: onyx-m2/onyx-m2-dbc (tesla_model3.dbc)";
CM_ BO_ 594 "source: joshwardell/model3dbc (Model3CAN.dbc)";
CM_ BO_ 595 "source: onyx-m2/onyx-m2-dbc (tesla_model3.dbc)";
CM_ BO_ 598 "source: talas9/tesla_can_signals (ModelY_ETH.compact.json)";
CM_ BO_ 599 "source: joshwardell/model3dbc (Model3CAN.dbc)";
CM_ BO_ 600 "source: onyx-m2/onyx-m2-dbc (tesla_model3.dbc)";
CM_ BO_ 601 "source: onyx-m2/onyx-m2-dbc (tesla_model3.dbc)";
CM_ BO_ 602 "source: onyx-m2/onyx-m2-dbc (tesla_model3.dbc)";
CM_ BO_ 603 "source: joshwardell/model3dbc (Model3CAN.dbc)";
CM_ BO_ 605 "source: joshwardell/model3dbc (Model3CAN.dbc)";
CM_ BO_ 606 "source: onyx-m2/onyx-m2-dbc (tesla_model3.dbc)";
CM_ BO_ 609 "source: joshwardell/model3dbc (Model3CAN.dbc)";
CM_ BO_ 610 "source: onyx-m2/onyx-m2-dbc (tesla_model3.dbc)";
CM_ BO_ 611 "source: onyx-m2/onyx-m2-dbc (tesla_model3.dbc)";
CM_ BO_ 612 "source: joshwardell/model3dbc (Model3CAN.dbc)";
CM_ BO_ 614 "source: joshwardell/model3dbc (Model3CAN.dbc)";
CM_ BO_ 615 "source: joshwardell/model3dbc (Model3CAN.dbc)";
CM_ BO_ 616 "source: joshwardell/model3dbc (Model3CAN.dbc)";
CM_ BO_ 617 "source: joshwardell/model3dbc (Model3CAN.dbc)";
CM_ BO_ 626 "source: onyx-m2/onyx-m2-dbc (tesla_model3.dbc)";
CM_ BO_ 627 "source: joshwardell/model3dbc (Model3CAN.dbc)";
CM_ BO_ 632 "source: onyx-m2/onyx-m2-dbc (tesla_model3.dbc)";
CM_ BO_ 633 "source: talas9/tesla_can_signals (ModelY_ETH.compact.json)";
CM_ BO_ 634 "source: talas9/tesla_can_signals (ModelY_ETH.compact.json)";
CM_ BO_ 636 "source: joshwardell/model3dbc (Model3CAN.dbc)";
CM_ BO_ 637 "source: joshwardell/model3dbc (Model3CAN.dbc)";
CM_ BO_ 641 "source: joshwardell/model3dbc (Model3CAN.dbc)";
CM_ BO_ 642 "source: joshwardell/model3dbc (Model3CAN.dbc)";
CM_ BO_ 644 "source: joshwardell/model3dbc (Model3CAN.dbc)";
CM_ BO_ 645 "source: onyx-m2/onyx-m2-dbc (tesla_model3.dbc)";
CM_ BO_ 646 "source: onyx-m2/onyx-m2-dbc (tesla_model3.dbc)";
CM_ BO_ 647 "source: joshwardell/model3dbc (Model3CAN.dbc)";
CM_ BO_ 648 "source: joshwardell/model3dbc (Model3CAN.dbc)";
CM_ BO_ 658 "source: joshwardell/model3dbc (Model3CAN.dbc)";
CM_ BO_ 659 "source: joshwardell/model3dbc (Model3CAN.dbc)";
CM_ BO_ 664 "source: onyx-m2/onyx-m2-dbc (tesla_model3.dbc)";
CM_ BO_ 669 "source: joshwardell/model3dbc (Model3CAN.dbc)";
CM_ BO_ 676 "source: onyx-m2/onyx-m2-dbc (tesla_model3.dbc)";
CM_ BO_ 679 "source: onyx-m2/onyx-m2-dbc (tesla_model3.dbc)";
CM_ BO_ 680 "source: joshwardell/model3dbc (Model3CAN.dbc)";
CM_ BO_ 681 "source: talas9/tesla_can_signals (ModelY_ETH.compact.json)";
CM_ BO_ 690 "source: onyx-m2/onyx-m2-dbc (tesla_model3.dbc)";
CM_ BO_ 691 "source: onyx-m2/onyx-m2-dbc (tesla_model3.dbc)";
